VERSION "HINBNNNYNNNNNNNNNNNNNNNNNNNNNNNNNNNYYNNNNN/4>%%%/4/'%**4NNN///"

NS_ :

BS_:

BU_: Traffic Tester CGW ADU

BO_ 1025 PCM_ELEC_AC_INFO: 32 CGW
 SG_ Gen_on_disp_req_CMU m2 : 182|2@0+ (1,0) [0|0] "" Vector__XXX
 SG_ DrvSys_Pwrdwn_Req_Xev m2 : 183|1@0+ (1,0) [0|0] "" Vector__XXX
 SG_ V2H_Supply_State m2 : 169|2@0+ (1,0) [0|0] "" Vector__XXX
 SG_ TrqDwn_MsgC_Rq m2 : 170|1@0+ (1,0) [0|0] "" Vector__XXX
 SG_ SelfWake_Set_Req m2 : 172|2@0+ (1,0) [0|0] "" Vector__XXX
 SG_ PSU_Supply_State m2 : 160|4@0+ (1,0) [0|0] "" Vector__XXX
 SG_ HvBatSysWarn_D_Rq m2 : 162|2@0+ (1,0) [0|0] "" Vector__XXX
 SG_ GenSysState_D_Rq m2 : 165|3@0+ (1,0) [0|0] "" Vector__XXX
 SG_ TrqDwn_MsgB_Rq m2 : 166|1@0+ (1,0) [0|0] "" Vector__XXX
 SG_ TrqDwn_MsgA_Rq m2 : 167|1@0+ (1,0) [0|0] "" Vector__XXX
 SG_ TrqDwn_BzB_Rq m2 : 152|1@0+ (1,0) [0|0] "" Vector__XXX
 SG_ TrqDwn_BzA_Rq m2 : 153|1@0+ (1,0) [0|0] "" Vector__XXX
 SG_ DispEVMode_D_Rq m2 : 155|2@0+ (1,0) [0|0] "" Vector__XXX
 SG_ BattTemp_Warn_D_Rq m2 : 157|2@0+ (1,0) [0|0] "" Vector__XXX
 SG_ BattTemp m2 : 151|10@0+ (0.5,-30) [-30|60] "degC" Vector__XXX
 SG_ RegenRejMsg_D_Req m2 : 136|1@0+ (1,0) [0|0] "" Vector__XXX
 SG_ RegenRejLamp_D_Req m2 : 137|1@0+ (1,0) [0|0] "" Vector__XXX
 SG_ Mot_D_ReqPwrHis m2 : 138|1@0+ (1,0) [0|0] "" Vector__XXX
 SG_ Mot_D_ReqPwrGain m2 : 140|2@0+ (1,0) [0|0] "" Vector__XXX
 SG_ ElecDrvSys_Pwrdwn_Req m2 : 141|1@0+ (1,0) [0|0] "" Vector__XXX
 SG_ PwrDwn_Flash_Req m2 : 142|1@0+ (1,0) [0|0] "" Vector__XXX
 SG_ PwrDwn_D_Req m2 : 143|1@0+ (1,0) [0|0] "" Vector__XXX
 SG_ Charging_State_D_Actl m1 : 187|4@0+ (1,0) [0|0] "" Vector__XXX
 SG_ Charger_Connector_Fit_State m1 : 191|4@0+ (1,0) [0|0] "" Vector__XXX
 SG_ GenSys_Notavail_Req_Xev m1 : 176|1@0+ (1,0) [0|0] "" Vector__XXX
 SG_ EV_Warning_Ind_Req m1 : 177|1@0+ (1,0) [0|0] "" Vector__XXX
 SG_ ElecDrvSys_Caut_Req m1 : 178|1@0+ (1,0) [0|0] "" Vector__XXX
 SG_ BatteryHeater_ON m1 : 179|1@0+ (1,0) [0|0] "" Vector__XXX
 SG_ Batt_Lack_Warn_D_Rq m1 : 182|3@0+ (1,0) [0|0] "" Vector__XXX
 SG_ BatteryChargingPreTelltale m1 : 183|1@0+ (1,0) [0|0] "" Vector__XXX
 SG_ Charger_Connector_Fitting m1 : 168|1@0+ (1,0) [0|0] "" Vector__XXX
 SG_ Air_BleedingMode_Req m1 : 169|1@0+ (1,0) [0|0] "" Vector__XXX
 SG_ BatteryHeater_info3 m1 : 171|2@0+ (1,0) [0|0] "" Vector__XXX
 SG_ BatteryHeater_info2 m1 : 173|2@0+ (1,0) [0|0] "" Vector__XXX
 SG_ BatteryHeater_info1 m1 : 175|2@0+ (1,0) [0|0] "" Vector__XXX
 SG_ SOC_Charge_Guide_Req_Xev m1 : 160|1@0+ (1,0) [0|0] "" Vector__XXX
 SG_ SOC_LowerLimit_HysL m1 : 152|8@0+ (0.5,0) [0|100] "%" Vector__XXX
 SG_ SOC_LowerLimit_HysH m1 : 144|8@0+ (0.5,0) [0|100] "%" Vector__XXX
 SG_ PbBatteryChargingState m1 : 147|3@0+ (1,0) [0|0] "" Vector__XXX
 SG_ HiVolt_Battery_FullCapacity m1 : 143|12@0+ (0.1,0) [0|100] "kWh" Vector__XXX
 SG_ Useract_Reject_Msg m0 : 186|3@0+ (1,0) [0|0] "" Vector__XXX
 SG_ Leakage_Advan_Com m0 : 187|1@0+ (1,0) [0|0] "" Vector__XXX
 SG_ ChargSys_Error_Req m0 : 188|1@0+ (1,0) [0|0] "" Vector__XXX
 SG_ ChargSys_Warn_Req m0 : 189|1@0+ (1,0) [0|0] "" Vector__XXX
 SG_ ElecDrvSys_mainte_Req m0 : 190|1@0+ (1,0) [0|0] "" Vector__XXX
 SG_ FuelLid_Close_B_Req m0 : 191|1@0+ (1,0) [0|0] "" Vector__XXX
 SG_ SOC_xev_EMPTY m0 : 183|8@0+ (0.5,0) [0|100] "%" Vector__XXX
 SG_ SOC_xev_FULL m0 : 175|8@0+ (0.5,0) [0|100] "%" Vector__XXX
 SG_ Power_generation_State m0 : 161|2@0+ (1,0) [0|0] "" Vector__XXX
 SG_ Battery_Deterioration m0 : 165|4@0+ (1,0) [0|0] "" Vector__XXX
 SG_ Batt_coling_disp_req_TCU m0 : 166|1@0+ (1,0) [0|0] "" Vector__XXX
 SG_ Batt_coling_disp_req_CMU m0 : 167|1@0+ (1,0) [0|0] "" Vector__XXX
 SG_ Max_Charge_Minute_AC m0 : 159|8@0+ (10,0) [0|2530] "min" Vector__XXX
 SG_ Max_Charge_Minute_QBC m0 : 151|8@0+ (5,0) [0|500] "min" Vector__XXX
 SG_ Refueling_Propriety_State m0 : 137|2@0+ (1,0) [0|0] "" Vector__XXX
 SG_ ElecDrvSys_Warn_Req m0 : 138|1@0+ (1,0) [0|0] "" Vector__XXX
 SG_ PowerDown m0 : 139|1@0+ (1,0) [0|0] "" Vector__XXX
 SG_ REX_Run m0 : 140|1@0+ (1,0) [0|0] "" Vector__XXX
 SG_ SuplyStatus m0 : 141|1@0+ (1,0) [0|0] "" Vector__XXX
 SG_ DCChargeStatus m0 : 142|1@0+ (1,0) [0|0] "" Vector__XXX
 SG_ ACChargeStatus m0 : 143|1@0+ (1,0) [0|0] "" Vector__XXX
 SG_ EVData_2_mode M : 135|8@0+ (1,0) [0|0] "" Vector__XXX
 SG_ AirAmb_Te_Actl : 113|10@0+ (0.25,-128) [-128|127.75] "degC"  ADU
 SG_ OilDtrWrn_Stat_B_Actl : 114|1@0+ (1,0) [0|0] "" Vector__XXX
 SG_ SedimentWarning : 115|1@0+ (1,0) [0|0] "" Vector__XXX
 SG_ AirAmbTe_D_Qf : 117|2@0+ (1,0) [0|0] ""  ADU
 SG_ EngClntTe_D_Qf : 119|2@0+ (1,0) [0|0] "" Vector__XXX
 SG_ DPFTelltale : 104|1@0+ (1,0) [0|0] "" Vector__XXX
 SG_ OilDtrWrn_Init_B_Eco : 105|1@0+ (1,0) [0|0] "" Vector__XXX
 SG_ Oil_deteriorate_warning : 106|1@0+ (1,0) [0|0] "" Vector__XXX
 SG_ FuelFilterWarning : 107|1@0+ (1,0) [0|0] "" Vector__XXX
 SG_ OilPressureWarning : 108|1@0+ (1,0) [0|0] "" Vector__XXX
 SG_ OverrevBz_D_Rq : 110|2@0+ (1,0) [0|0] "" Vector__XXX
 SG_ FUEL_CAP_OFF_TELTAL : 111|1@0+ (1,0) [0|0] "" Vector__XXX
 SG_ EngineIdleStatus : 96|1@0+ (1,0) [0|0] "" Vector__XXX
 SG_ BatteryChargingTelltale : 97|1@0+ (1,0) [0|0] "" Vector__XXX
 SG_ DieselGlowplugTelltale : 98|1@0+ (1,0) [0|0] "" Vector__XXX
 SG_ Oil_Deteriorate_Warn_Rst : 99|1@0+ (1,0) [0|0] "" Vector__XXX
 SG_ GPF_SootDepoWarning : 100|1@0+ (1,0) [0|0] "" Vector__XXX
 SG_ PCM_BPS_DrESUPwr_Fail : 101|1@0+ (1,0) [0|0] "" Vector__XXX
 SG_ DriverStatus_disp : 102|1@0+ (1,0) [0|0] "" Vector__XXX
 SG_ LowTempTorqLimit : 103|1@0+ (1,0) [0|0] "" Vector__XXX
 SG_ HighTempTorqLimit : 88|1@0+ (1,0) [0|0] "" Vector__XXX
 SG_ MildHevBatteryWarningTelltale : 89|1@0+ (1,0) [0|0] "" Vector__XXX
 SG_ MildHevWarningTelltale : 90|1@0+ (1,0) [0|0] "" Vector__XXX
 SG_ BatteryPerformanceTelltale : 91|1@0+ (1,0) [0|0] "" Vector__XXX
 SG_ OilLevelWarning : 93|2@0+ (1,0) [0|0] "" Vector__XXX
 SG_ ECMMILRequest : 95|2@0+ (1,0) [0|0] "" Vector__XXX
 SG_ AirAmb_P_Actl : 85|6@0+ (10,500) [500|1110] "millibar" Vector__XXX
 SG_ PCM_INDLvl_D_Rq : 87|2@0+ (1,0) [0|0] "" Vector__XXX
 SG_ FuelPulse : 79|8@0+ (20,0) [0|5100] "Microliters" Vector__XXX
 SG_ EngClnt_Te_Actl : 71|8@0+ (1,-40) [-40|214] "degC" Vector__XXX
 SG_ HPECU_DTC_Clear_Rq : 56|1@0+ (1,0) [0|0] "" Vector__XXX
 SG_ AC_Mode_Sig : 59|3@0+ (1,0) [0|0] "" Vector__XXX
 SG_ BAT_Refcooling_Lvl : 63|4@0+ (1,0) [0|0] "" Vector__XXX
 SG_ FAN_AC_State_Actl : 55|8@0+ (0.5,0) [0|100] "%" Vector__XXX
 SG_ PTCHeater_Win_Actual : 47|8@0+ (50,0) [0|12750] "W" Vector__XXX
 SG_ Permit_Power_AC : 39|8@0+ (50,0) [0|10000] "W" Vector__XXX
 SG_ Compressor_Power_Actual : 31|8@0+ (50,0) [0|10000] "W" Vector__XXX
 SG_ Compressor_Rev_Actual : 15|16@0+ (1,0) [0|10000] "rpm" Vector__XXX
 SG_ PTCHeater_Power_Actual : 7|8@0+ (50,0) [0|10000] "W" Vector__XXX

BO_ 1010 HP_ECU_Infomation: 32 CGW
 SG_ CXP_UERR : 186|1@0+ (1,0) [0|0] ""  ADU
 SG_ GFPEXT : 188|2@0+ (1,0) [0|0] ""  ADU
 SG_ P2Z_INV : 189|1@0+ (1,0) [0|0] ""  ADU
 SG_ GRPHLDR : 190|1@0+ (1,0) [0|0] ""  ADU
 SG_ GRPHLDL : 191|1@0+ (1,0) [0|0] ""  ADU
 SG_ TMPMFIX : 176|1@0+ (1,0) [0|0] ""  ADU
 SG_ TMPABNR : 177|1@0+ (1,0) [0|0] ""  ADU
 SG_ TMPABNL : 178|1@0+ (1,0) [0|0] ""  ADU
 SG_ GRPFAIL1 : 179|1@0+ (1,0) [0|0] ""  ADU
 SG_ GRPFAIL0 : 180|1@0+ (1,0) [0|0] ""  ADU
 SG_ F_HTRSW : 181|1@0+ (1,0) [0|0] ""  ADU
 SG_ F_HTROP : 182|1@0+ (1,0) [0|0] ""  ADU
 SG_ F_HTRGS : 183|1@0+ (1,0) [0|0] ""  ADU
 SG_ Wtrcond_WtrTrg : 175|8@0+ (1,0) [0|255] "deg.C" Vector__XXX
 SG_ HtrcoreWtrTrg : 167|8@0+ (1,0) [0|255] "deg.C" Vector__XXX
 SG_ HPECU_MasterWarning_Rq : 154|3@0+ (1,0) [0|0] "" Vector__XXX
 SG_ HPECU_calc_CVN : 155|1@0+ (1,0) [0|0] "" Vector__XXX
 SG_ HPECU_DTC_Clear_Comp : 156|1@0+ (1,0) [0|0] "" Vector__XXX
 SG_ HP_Remote_PreAC_Res : 157|1@0+ (1,0) [0|0] "" Vector__XXX
 SG_ HP_PreAC_RearDef_Rq : 158|1@0+ (1,0) [0|0] "" Vector__XXX
 SG_ HP_State_PreAC_Operation : 146|4@0+ (1,0) [0|0] "" Vector__XXX
 SG_ HP_Flg_HeatExchgFrost : 149|3@0+ (1,0) [0|0] "" Vector__XXX
 SG_ HP_Fail_OperationCycleFail : 151|2@0+ (1,0) [0|0] "" Vector__XXX
 SG_ HP_State_OperationCycle : 139|4@0+ (1,0) [0|0] "" Vector__XXX
 SG_ HP_Fail_TempRfrgCondOut : 143|4@0+ (1,0) [0|0] "" Vector__XXX
 SG_ HP_Fail_SolVlv_Warm : 131|4@0+ (1,0) [0|0] "" Vector__XXX
 SG_ HP_Fail_SolVlv_HiPre_Fail : 135|4@0+ (1,0) [0|0] "" Vector__XXX
 SG_ DBKL_MET : 113|2@0+ (1,0) [0|0] "" Vector__XXX
 SG_ atcTAO_Ps : 108|8@0+ (1,-127) [-127|128] "" Vector__XXX
 SG_ atcTAO_Dr : 100|8@0+ (1,-127) [-127|128] "" Vector__XXX
 SG_ atcBlwAirflow : 91|7@0+ (5,0) [0|635] "m3/h" Vector__XXX
 SG_ atcAMratioPs : 83|8@0+ (0.5,0) [0|100] "%" Vector__XXX
 SG_ atcAMratioDr : 75|8@0+ (0.5,0) [0|100] "%" Vector__XXX
 SG_ atcAImodeRecRatio : 67|8@0+ (0.5,0) [0|100] "%" Vector__XXX
 SG_ atcADmode : 71|4@0+ (1,0) [0|0] "" Vector__XXX
 SG_ BAT_Cool_DistRate : 63|6@0+ (2,0) [0|100] "%" Vector__XXX
 SG_ BAT_TXV_Trg : 43|12@0+ (0.05,0) [0|100] "%" Vector__XXX
 SG_ FAN_AC_Out_Trg : 35|8@0+ (0.5,0) [0|127.5] "%" Vector__XXX
 SG_ PTCheater_Wout_Trg : 17|14@0+ (1,0) [0|10000] "W" Vector__XXX
 SG_ THO_Control_Req : 8|3@0+ (1,0) [0|0] "" Vector__XXX
 SG_ Compressor_Rev_Rq : 9|1@0+ (1,0) [0|0] "" Vector__XXX
 SG_ Compressor_Rev_Trg : 7|14@0+ (1,0) [0|10000] "rpm" Vector__XXX

BO_ 994 Navi_Tnnl_Brdg_Info: 32 CGW
 SG_ Navi_grad_MM : 135|8@0+ (1,0) [0|255] ""  ADU
 SG_ Navi_Oneway_dist0 : 88|8@0+ (1,0) [0|255] ""  ADU
 SG_ Navi_Oneway_dist_lsb0 : 89|1@0+ (1,0) [0|0] ""  ADU
 SG_ Navi_Oneway_flg0 : 92|3@0+ (1,0) [0|0] ""  ADU
 SG_ Navi_Oneway_MM : 95|3@0+ (1,0) [0|0] ""  ADU
 SG_ Navi_BuildupArea_dist2 : 87|8@0+ (1,0) [0|255] ""  ADU
 SG_ Navi_BuildupArea_dist_lsb2 : 72|1@0+ (1,0) [0|0] ""  ADU
 SG_ Navi_BuildupArea_flg2 : 74|2@0+ (1,0) [0|0] ""  ADU
 SG_ Navi_BuildupArea_dist1 : 66|8@0+ (1,0) [0|255] ""  ADU
 SG_ Navi_BuildupArea_dist_lsb1 : 67|1@0+ (1,0) [0|0] ""  ADU
 SG_ Navi_BuildupArea_flg1 : 69|2@0+ (1,0) [0|0] ""  ADU
 SG_ Navi_BuildupArea_MM : 71|2@0+ (1,0) [0|0] ""  ADU
 SG_ Navi_brdg_sctn_dist0 : 27|8@0+ (1,0) [0|255] ""  ADU
 SG_ Navi_brdg_dist_type0 : 28|1@0+ (1,0) [0|0] ""  ADU
 SG_ Navi_brdg_dist0 : 20|8@0+ (1,0) [0|255] ""  ADU
 SG_ Navi_brdg_dist_lsb0 : 21|1@0+ (1,0) [0|0] ""  ADU
 SG_ Navi_tnnl_sctn_dist_type0 : 13|8@0+ (1,0) [0|255] ""  ADU
 SG_ Navi_tnnl_dist_type0 : 14|1@0+ (1,0) [0|0] ""  ADU
 SG_ Navi_tnnl_dist0 : 6|8@0+ (1,0) [0|255] ""  ADU
 SG_ Navi_tnnl_dist_lsb0 : 7|1@0+ (1,0) [0|0] ""  ADU

BO_ 988 EgoPath_Info2: 32 CGW
 SG_ ADAS_Map_PositionConf_cost56 : 201|7@0+ (1,0) [0|100] "%"  ADU
 SG_ ADAS_Map_PositionConf_cost45 : 192|7@0+ (1,0) [0|100] "%"  ADU
 SG_ ADAS_Map_PositionConf_cost34 : 199|7@0+ (1,0) [0|100] "%"  ADU
 SG_ ADAS_Map_PositionConf_cost23 : 190|7@0+ (1,0) [0|100] "%"  ADU
 SG_ ADAS_Map_PositionConf_cost12 : 181|7@0+ (1,0) [0|100] "%"  ADU
 SG_ ADAS_Map_PositionConfidence4 : 168|3@0+ (1,0) [0|0] ""  ADU
 SG_ ADAS_Map_PositionConfidence3 : 170|2@0+ (1,0) [0|0] ""  ADU
 SG_ ADAS_Map_PositionConfidence2 : 172|2@0+ (1,0) [0|0] ""  ADU
 SG_ ADAS_Map_PositionConfidence1 : 175|3@0+ (1,0) [0|0] ""  ADU
 SG_ MAP_Version : 158|15@0+ (1,0) [0|0] ""  ADU
 SG_ CMU_Package_Version : 143|17@0+ (1,0) [0|131071] ""  ADU
 SG_ NavRegionCode : 133|6@0+ (1,0) [0|63] ""  ADU
 SG_ NavRouteGuidance_flg : 135|2@0+ (1,0) [0|0] ""  ADU
 SG_ Multi_Carriageway_Dist : 105|10@0+ (1,0) [0|1022] "m"  ADU
 SG_ Multi_Carriageway_Ego : 107|2@0+ (1,0) [0|0] ""  ADU
 SG_ Lane_Num_Next : 111|4@0+ (1,0) [0|0] ""  ADU
 SG_ Lane_Num_Dist : 91|12@0+ (1,0) [0|4094] "m"  ADU
 SG_ Lane_Num_Ego : 95|4@0+ (1,0) [0|0] ""  ADU
 SG_ ADAS_Map_Link_Type_Dist : 73|10@0+ (1,0) [0|1022] "m"  ADU
 SG_ ADAS_Map_SUB_Distance_Ego : 67|10@0+ (1,0) [0|1022] "m"  ADU
 SG_ ADAS_Map_SUB_Attribute_Ego : 71|4@0+ (1,0) [0|0] ""  ADU
 SG_ Route_Destination_Dist : 33|12@0+ (1,0) [0|4094] "m"  ADU
 SG_ Route_Destination_Ego : 35|2@0+ (1,0) [0|0] ""  ADU
 SG_ Stop_Info_Dist : 29|10@0+ (1,0) [0|1022] "m"  ADU
 SG_ Stop_Info_Ego : 31|2@0+ (1,0) [0|0] ""  ADU
 SG_ One_Way_Code_Dist : 9|10@0+ (1,0) [0|1022] "m"  ADU
 SG_ One_Way_Code_Ego : 11|2@0+ (1,0) [0|0] ""  ADU
 SG_ Supplymental_Speed_Sign_Ego : 15|4@0+ (1,0) [0|0] ""  ADU
 SG_ Supplymental_Speed_Limit_Ego : 7|8@0+ (1,0) [0|254] "Unitless"  ADU

BO_ 985 ADAS_MAP_Information1: 32 CGW
 SG_ NavCountry_Roadside : 175|2@0+ (1,0) [0|0] ""  ADU
 SG_ Speed_Limit_Unit : 161|2@0+ (1,0) [0|0] ""  ADU
 SG_ Speed_Limit : 155|10@0+ (1,0) [1|999] ""  ADU
 SG_ NavZoneArea_flag_300m : 123|1@0+ (1,0) [0|0] ""  ADU
 SG_ NavZoneArea_flag_200m : 124|1@0+ (1,0) [0|0] ""  ADU
 SG_ NavZoneArea_flag_100m : 125|1@0+ (1,0) [0|0] ""  ADU
 SG_ NavZoneArea_flag : 126|1@0+ (1,0) [0|0] ""  ADU
 SG_ Implicit_Speed_Sign_Ego : 113|3@0+ (1,0) [0|0] ""  ADU
 SG_ Speed_Limit_Sign_Ego : 115|2@0+ (1,0) [0|0] ""  ADU
 SG_ Speed_Limit_Accuracy_Ego : 117|2@0+ (1,0) [0|0] ""  ADU
 SG_ Speed_Limit_Next : 109|8@0+ (1,0) [0|255] "Unitless"  ADU
 SG_ Speed_Limit_Dist : 89|12@0+ (1,0) [0|4094] "m"  ADU
 SG_ Speed_Limit_Ego : 81|8@0+ (1,0) [0|255] "Unitless"  ADU
 SG_ NavFunctionalRoadClass_Next : 86|5@0+ (1,0) [0|0] ""  ADU
 SG_ NavFunctionalRoadClass_Dist : 66|12@0+ (1,0) [0|4094] "m"  ADU
 SG_ NavFunctionalRoadClass_Ego : 71|5@0+ (1,0) [0|0] ""  ADU
 SG_ ADAS_MAP_DR_Confidence : 49|2@0+ (1,0) [0|0] ""  ADU
 SG_ ADAS_MAP_MAP_Accuracy : 51|2@0+ (1,0) [0|0] ""  ADU
 SG_ ADAS_MAP_Curvature300_index : 53|2@0+ (1,0) [0|3] ""  ADU
 SG_ ADAS_MAP_Curvature300_2digit : 44|7@0+ (1,-64) [-64|62] ""  ADU
 SG_ ADAS_MAP_Curvature200_index : 46|2@0+ (1,0) [0|3] ""  ADU
 SG_ ADAS_MAP_Curvature200_2digit : 37|7@0+ (1,-64) [-64|62] ""  ADU
 SG_ ADAS_MAP_Curvature100_index : 39|2@0+ (1,0) [0|3] ""  ADU
 SG_ ADAS_MAP_Curvature100_2digit : 30|7@0+ (1,-64) [-64|62] ""  ADU
 SG_ ADAS_MAP_Curvature0_index : 16|2@0+ (1,0) [0|3] ""  ADU
 SG_ ADAS_MAP_Curvature0_2digit : 23|7@0+ (1,-64) [-64|62] ""  ADU
 SG_ ADAS_Map_SUB_Attribute : 10|3@0+ (1,0) [0|0] ""  ADU
 SG_ ADAS_Map_SUB_Distance : 4|10@0+ (1,0) [0|1022] "m"  ADU
 SG_ ADAS_Map_PositionConfidence : 7|3@0+ (1,0) [0|0] ""  ADU

BO_ 977 HMI_Status_Notification: 8 CGW
 SG_ HMI_State_Notice_ISPU : 7|2@0+ (1,0) [0|0] ""  ADU

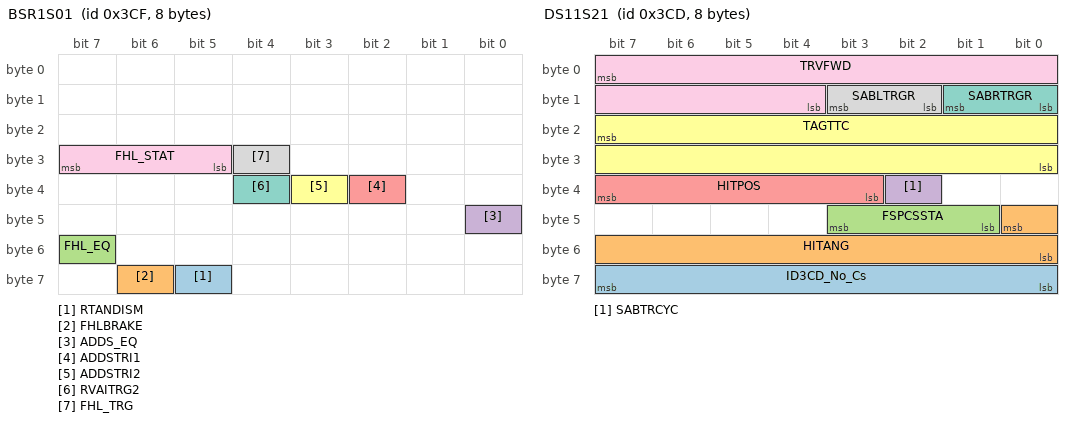
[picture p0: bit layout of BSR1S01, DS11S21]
BO_ 975 BSR1S01: 8 ADU
 SG_ RTANDISM : 61|1@0+ (1,0) [0|1] ""  CGW
 SG_ FHLBRAKE : 62|1@0+ (1,0) [0|1] ""  CGW
 SG_ FHL_EQ : 55|1@0+ (1,0) [0|1] ""  CGW
 SG_ ADDS_EQ : 40|1@0+ (1,0) [0|1] ""  CGW
 SG_ ADDSTRI1 : 34|1@0+ (1,0) [0|1] ""  CGW
 SG_ ADDSTRI2 : 35|1@0+ (1,0) [0|1] ""  CGW
 SG_ RVAITRG2 : 36|1@0+ (1,0) [0|1] ""  CGW
 SG_ FHL_TRG : 28|1@0+ (1,0) [0|1] ""  CGW
 SG_ FHL_STAT : 31|3@0+ (1,0) [0|7] ""  CGW

BO_ 974 BCC1S06: 8 ADU
 SG_ CAAINDIR : 34|2@0+ (1,0) [0|3] ""  CGW
 SG_ CAAINDIM : 38|4@0+ (1,0) [0|15] ""  CGW

BO_ 973 DS11S21: 8 ADU
 SG_ ID3CD_No_Cs : 63|8@0+ (1,0) [0|255] ""  CGW
 SG_ HITANG : 40|9@0- (0.01,0) [-2.56|2.55] "rad"  CGW
 SG_ FSPCSSTA : 43|3@0+ (1,0) [0|7] ""  CGW
 SG_ SABTRCYC : 34|1@0+ (1,0) [0|1] ""  CGW
 SG_ HITPOS : 39|5@0+ (1,0) [0|31] ""  CGW
 SG_ TAGTTC : 23|16@0+ (1,0) [0|65535] "ms"  CGW
 SG_ SABRTRGR : 9|2@0+ (1,0) [0|3] ""  CGW
 SG_ SABLTRGR : 11|2@0+ (1,0) [0|3] ""  CGW
 SG_ TRVFWD : 7|12@0+ (0.2,0) [0|819] "km/h"  CGW

BO_ 972 CSR1S08: 8 ADU
 SG_ CSR_BUZ : 43|4@0+ (1,0) [0|15] ""  CGW
 SG_ CSR_VOL : 46|3@0+ (1,0) [0|7] ""  CGW
 SG_ CAM_INF1 : 32|1@0+ (1,0) [0|1] ""  CGW
 SG_ CSRAVABL : 34|1@0+ (1,0) [0|1] ""  CGW
 SG_ ICSAVABL : 35|1@0+ (1,0) [0|1] ""  CGW
 SG_ RCDAVABL : 36|1@0+ (1,0) [0|1] ""  CGW
 SG_ PKSS_VE : 37|1@0+ (1,0) [0|1] ""  CGW
 SG_ PKSSINFO : 29|2@0+ (1,0) [0|3] ""  CGW
 SG_ CSR_INF2 : 30|1@0+ (1,0) [0|1] ""  CGW
 SG_ CSR_INF1 : 31|1@0+ (1,0) [0|1] ""  CGW
 SG_ RLS_DIRT : 17|2@0+ (1,0) [0|3] ""  CGW
 SG_ RRS_DIRT : 19|2@0+ (1,0) [0|3] ""  CGW
 SG_ FLS_DIRT : 21|2@0+ (1,0) [0|3] ""  CGW
 SG_ FRS_DIRT : 23|2@0+ (1,0) [0|3] ""  CGW
 SG_ RLC_DIRT : 9|2@0+ (1,0) [0|3] ""  CGW
 SG_ RRC_DIRT : 11|2@0+ (1,0) [0|3] ""  CGW
 SG_ RL_DIRT : 13|2@0+ (1,0) [0|3] ""  CGW
 SG_ RR_DIRT : 15|2@0+ (1,0) [0|3] ""  CGW
 SG_ FLC_DIRT : 1|2@0+ (1,0) [0|3] ""  CGW
 SG_ FRC_DIRT : 3|2@0+ (1,0) [0|3] ""  CGW
 SG_ FL_DIRT : 5|2@0+ (1,0) [0|3] ""  CGW
 SG_ FR_DIRT : 7|2@0+ (1,0) [0|3] ""  CGW

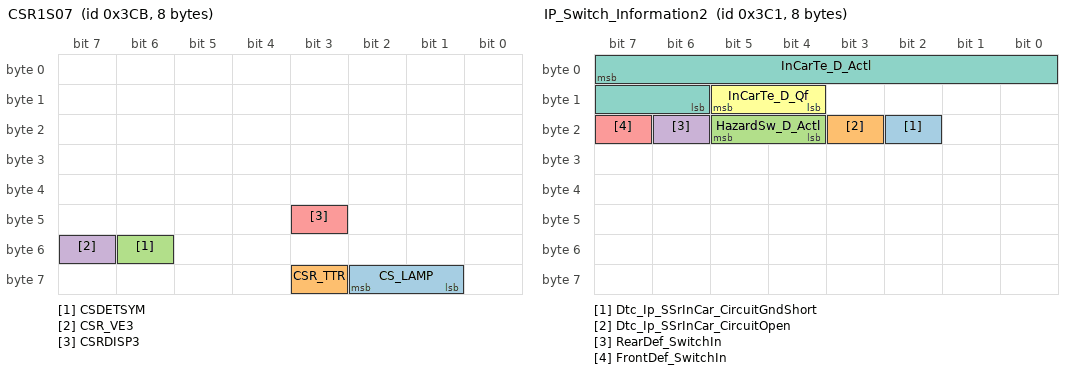
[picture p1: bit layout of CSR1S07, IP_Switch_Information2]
BO_ 971 CSR1S07: 8 ADU
 SG_ CS_LAMP : 58|2@0+ (1,0) [0|3] ""  CGW
 SG_ CSR_TTR : 59|1@0+ (1,0) [0|1] ""  CGW
 SG_ CSDETSYM : 54|1@0+ (1,0) [0|1] ""  CGW
 SG_ CSR_VE3 : 55|1@0+ (1,0) [0|1] ""  CGW
 SG_ CSRDISP3 : 43|1@0+ (1,0) [0|1] ""  CGW

BO_ 961 IP_Switch_Information2: 8 CGW
 SG_ Dtc_Ip_SSrInCar_CircuitGndShort : 18|1@0+ (1,0) [0|0] "" Vector__XXX
 SG_ Dtc_Ip_SSrInCar_CircuitOpen : 19|1@0+ (1,0) [0|0] "" Vector__XXX
 SG_ HazardSw_D_Actl : 21|2@0+ (1,0) [0|0] ""  ADU
 SG_ RearDef_SwitchIn : 22|1@0+ (1,0) [0|0] "" Vector__XXX
 SG_ FrontDef_SwitchIn : 23|1@0+ (1,0) [0|0] "" Vector__XXX
 SG_ InCarTe_D_Qf : 13|2@0+ (1,0) [0|0] ""  ADU
 SG_ InCarTe_D_Actl : 7|10@0+ (0.1,-40) [-40|62.3] "deg.C"  ADU

BO_ 960 IP_Switch_Information: 32 CGW
 SG_ ADAS_MAP_Distance_to_tunnel : 205|9@0+ (1,0) [0|510] "m"  ADU
 SG_ ADAS_MAP_Tunnel_inf : 207|2@0+ (1,0) [0|0] ""  ADU
 SG_ ADAS_Map_Link_Type_Ego : 195|4@0+ (1,0) [0|0] ""  ADU
 SG_ ADAS_Map_FormofWay_Ego : 199|4@0+ (1,0) [0|0] ""  ADU
 SG_ NavFunctionalRoadClass : 92|5@0+ (1,0) [0|0] ""  ADU
 SG_ NavBuildUpArea_flg : 93|1@0+ (1,0) [0|0] ""  ADU
 SG_ NavDataAvailable_flg : 95|2@0+ (1,0) [0|0] ""  ADU
 SG_ NavCountryCode : 73|10@0+ (1,0) [0|1023] ""  ADU
 SG_ ipRearDef_Ind : 60|1@0+ (1,0) [0|0] "" Vector__XXX
 SG_ RearDef_B_Rq : 61|1@0+ (1,0) [0|0] "" Vector__XXX
 SG_ FrontDef_B_Rq : 62|1@0+ (1,0) [0|0] "" Vector__XXX
 SG_ PanelHeaterSwitchIn_RH : 49|3@0+ (1,0) [0|0] "" Vector__XXX
 SG_ PanelHeaterSwitchIn_LH : 52|3@0+ (1,0) [0|0] "" Vector__XXX
 SG_ SteeringHeaterSwitchIn : 55|3@0+ (1,0) [0|0] "" Vector__XXX
 SG_ SeatVentilationSwitchIn_RH : 42|3@0+ (1,0) [0|0] "" Vector__XXX
 SG_ SeatHeaterSwitchIn_RH : 45|3@0+ (1,0) [0|0] "" Vector__XXX
 SG_ SeatVentilationSwitchIn_LH : 32|3@0+ (1,0) [0|0] "" Vector__XXX
 SG_ SeatHeaterSwitchIn_LH : 35|3@0+ (1,0) [0|0] "" Vector__XXX
 SG_ ipREARmode : 37|2@0+ (1,0) [0|0] "" Vector__XXX
 SG_ ipECOmode : 39|2@0+ (1,0) [0|0] "" Vector__XXX
 SG_ ipAImode : 27|4@0+ (1,0) [0|0] "" Vector__XXX
 SG_ ipADmode : 31|4@0+ (1,0) [0|0] "" Vector__XXX
 SG_ ipACmode : 19|4@0+ (1,0) [0|0] "" Vector__XXX
 SG_ ipBlwLvl : 23|4@0+ (1,0) [0|0] "" Vector__XXX
 SG_ ipTSetPs : 15|8@0+ (0.1,12) [12|37.5] "deg.C" Vector__XXX
 SG_ ipTSetDr : 7|8@0+ (0.1,12) [12|37.5] "deg.C" Vector__XXX

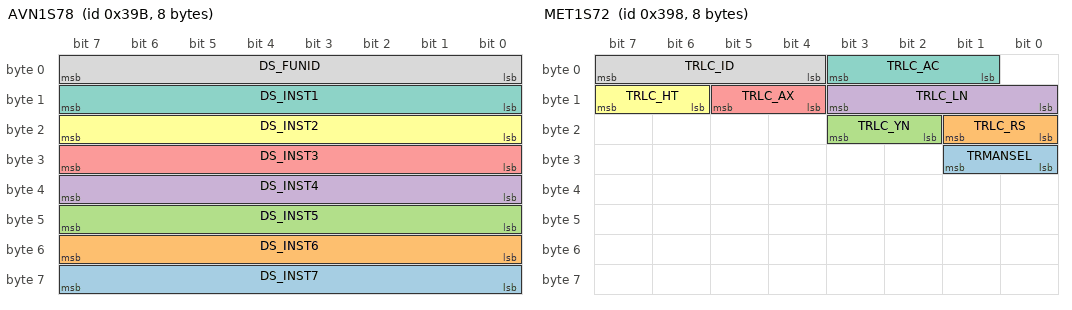
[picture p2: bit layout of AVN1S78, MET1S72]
BO_ 923 AVN1S78: 8 CGW
 SG_ DS_INST7 : 63|8@0+ (1,0) [0|255] ""  ADU
 SG_ DS_INST6 : 55|8@0+ (1,0) [0|255] ""  ADU
 SG_ DS_INST5 : 47|8@0+ (1,0) [0|255] ""  ADU
 SG_ DS_INST4 : 39|8@0+ (1,0) [0|255] ""  ADU
 SG_ DS_INST3 : 31|8@0+ (1,0) [0|255] ""  ADU
 SG_ DS_INST2 : 23|8@0+ (1,0) [0|255] ""  ADU
 SG_ DS_INST1 : 15|8@0+ (1,0) [0|255] ""  ADU
 SG_ DS_FUNID : 7|8@0+ (1,0) [0|255] ""  ADU

BO_ 920 MET1S72: 8 CGW
 SG_ TRMANSEL : 25|2@0+ (1,0) [0|3] ""  ADU
 SG_ TRLC_RS : 17|2@0+ (1,0) [0|3] ""  ADU
 SG_ TRLC_YN : 19|2@0+ (1,0) [0|3] ""  ADU
 SG_ TRLC_LN : 11|4@0+ (1,0) [0|15] ""  ADU
 SG_ TRLC_AX : 13|2@0+ (1,0) [0|3] ""  ADU
 SG_ TRLC_HT : 15|2@0+ (1,0) [0|3] ""  ADU
 SG_ TRLC_AC : 3|3@0+ (1,0) [0|7] ""  ADU
 SG_ TRLC_ID : 7|4@0+ (1,0) [0|15] ""  ADU

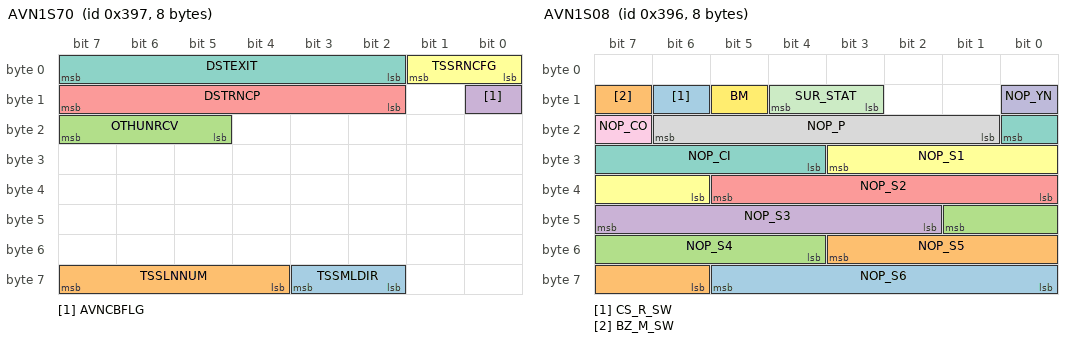
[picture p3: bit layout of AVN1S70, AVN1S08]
BO_ 919 AVN1S70: 8 CGW
 SG_ TSSMLDIR : 59|2@0+ (1,0) [0|3] ""  ADU
 SG_ TSSLNNUM : 63|4@0+ (1,0) [0|15] ""  ADU
 SG_ OTHUNRCV : 23|3@0+ (1,0) [0|7] ""  ADU
 SG_ AVNCBFLG : 8|1@0+ (1,0) [0|1] ""  ADU
 SG_ DSTRNCP : 15|6@0+ (1,0) [0|63] ""  ADU
 SG_ TSSRNCFG : 1|2@0+ (1,0) [0|3] ""  ADU
 SG_ DSTEXIT : 7|6@0+ (1,0) [0|63] ""  ADU

BO_ 918 AVN1S08: 8 CGW
 SG_ NOP_S6 : 61|6@0+ (1,0) [0|63] ""  ADU
 SG_ NOP_S5 : 51|6@0+ (1,0) [0|63] ""  ADU
 SG_ NOP_S4 : 41|6@0+ (1,0) [0|63] ""  ADU
 SG_ NOP_S3 : 47|6@0+ (1,0) [0|63] ""  ADU
 SG_ NOP_S2 : 37|6@0+ (1,0) [0|63] ""  ADU
 SG_ NOP_S1 : 27|6@0+ (1,0) [0|63] ""  ADU
 SG_ NOP_CI : 16|5@0+ (1,0) [0|31] ""  ADU
 SG_ NOP_P : 22|6@0+ (1,0) [0|63] ""  ADU
 SG_ NOP_CO : 23|1@0+ (1,0) [0|1] ""  ADU
 SG_ NOP_YN : 8|1@0+ (1,0) [0|1] ""  ADU
 SG_ SUR_STAT : 12|2@0+ (1,0) [0|3] ""  ADU
 SG_ BM : 13|1@0+ (1,0) [0|1] ""  ADU
 SG_ CS_R_SW : 14|1@0+ (1,0) [0|0] ""  ADU
 SG_ BZ_M_SW : 15|1@0+ (1,0) [0|0] ""  ADU

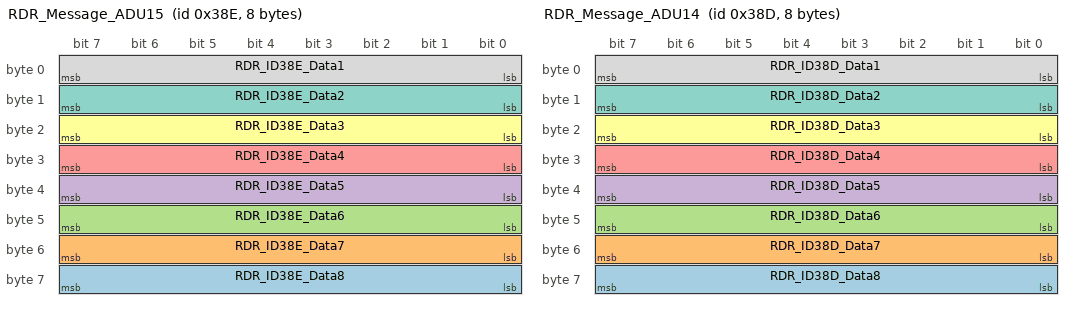
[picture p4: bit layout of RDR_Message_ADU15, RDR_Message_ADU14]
BO_ 910 RDR_Message_ADU15: 8 ADU
 SG_ RDR_ID38E_Data8 : 63|8@0+ (1,0) [0|255] ""  CGW
 SG_ RDR_ID38E_Data7 : 55|8@0+ (1,0) [0|255] ""  CGW
 SG_ RDR_ID38E_Data6 : 47|8@0+ (1,0) [0|255] ""  CGW
 SG_ RDR_ID38E_Data5 : 39|8@0+ (1,0) [0|255] ""  CGW
 SG_ RDR_ID38E_Data4 : 31|8@0+ (1,0) [0|255] ""  CGW
 SG_ RDR_ID38E_Data3 : 23|8@0+ (1,0) [0|255] ""  CGW
 SG_ RDR_ID38E_Data2 : 15|8@0+ (1,0) [0|255] ""  CGW
 SG_ RDR_ID38E_Data1 : 7|8@0+ (1,0) [0|255] ""  CGW

BO_ 909 RDR_Message_ADU14: 8 ADU
 SG_ RDR_ID38D_Data8 : 63|8@0+ (1,0) [0|255] ""  CGW
 SG_ RDR_ID38D_Data7 : 55|8@0+ (1,0) [0|255] ""  CGW
 SG_ RDR_ID38D_Data6 : 47|8@0+ (1,0) [0|255] ""  CGW
 SG_ RDR_ID38D_Data5 : 39|8@0+ (1,0) [0|255] ""  CGW
 SG_ RDR_ID38D_Data4 : 31|8@0+ (1,0) [0|255] ""  CGW
 SG_ RDR_ID38D_Data3 : 23|8@0+ (1,0) [0|255] ""  CGW
 SG_ RDR_ID38D_Data2 : 15|8@0+ (1,0) [0|255] ""  CGW
 SG_ RDR_ID38D_Data1 : 7|8@0+ (1,0) [0|255] ""  CGW

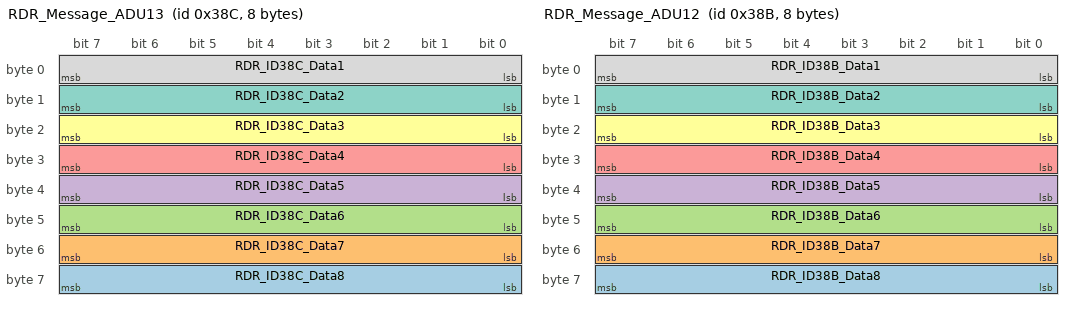
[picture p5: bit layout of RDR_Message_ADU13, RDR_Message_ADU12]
BO_ 908 RDR_Message_ADU13: 8 ADU
 SG_ RDR_ID38C_Data8 : 63|8@0+ (1,0) [0|255] ""  CGW
 SG_ RDR_ID38C_Data7 : 55|8@0+ (1,0) [0|255] ""  CGW
 SG_ RDR_ID38C_Data6 : 47|8@0+ (1,0) [0|255] ""  CGW
 SG_ RDR_ID38C_Data5 : 39|8@0+ (1,0) [0|255] ""  CGW
 SG_ RDR_ID38C_Data4 : 31|8@0+ (1,0) [0|255] ""  CGW
 SG_ RDR_ID38C_Data3 : 23|8@0+ (1,0) [0|255] ""  CGW
 SG_ RDR_ID38C_Data2 : 15|8@0+ (1,0) [0|255] ""  CGW
 SG_ RDR_ID38C_Data1 : 7|8@0+ (1,0) [0|255] ""  CGW

BO_ 907 RDR_Message_ADU12: 8 ADU
 SG_ RDR_ID38B_Data8 : 63|8@0+ (1,0) [0|255] ""  CGW
 SG_ RDR_ID38B_Data7 : 55|8@0+ (1,0) [0|255] ""  CGW
 SG_ RDR_ID38B_Data6 : 47|8@0+ (1,0) [0|255] ""  CGW
 SG_ RDR_ID38B_Data5 : 39|8@0+ (1,0) [0|255] ""  CGW
 SG_ RDR_ID38B_Data4 : 31|8@0+ (1,0) [0|255] ""  CGW
 SG_ RDR_ID38B_Data3 : 23|8@0+ (1,0) [0|255] ""  CGW
 SG_ RDR_ID38B_Data2 : 15|8@0+ (1,0) [0|255] ""  CGW
 SG_ RDR_ID38B_Data1 : 7|8@0+ (1,0) [0|255] ""  CGW

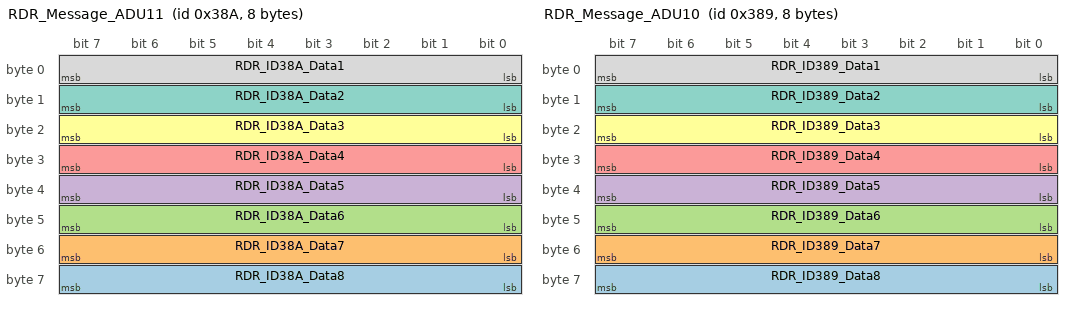
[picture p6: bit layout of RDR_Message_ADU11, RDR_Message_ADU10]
BO_ 906 RDR_Message_ADU11: 8 ADU
 SG_ RDR_ID38A_Data8 : 63|8@0+ (1,0) [0|255] ""  CGW
 SG_ RDR_ID38A_Data7 : 55|8@0+ (1,0) [0|255] ""  CGW
 SG_ RDR_ID38A_Data6 : 47|8@0+ (1,0) [0|255] ""  CGW
 SG_ RDR_ID38A_Data5 : 39|8@0+ (1,0) [0|255] ""  CGW
 SG_ RDR_ID38A_Data4 : 31|8@0+ (1,0) [0|255] ""  CGW
 SG_ RDR_ID38A_Data3 : 23|8@0+ (1,0) [0|255] ""  CGW
 SG_ RDR_ID38A_Data2 : 15|8@0+ (1,0) [0|255] ""  CGW
 SG_ RDR_ID38A_Data1 : 7|8@0+ (1,0) [0|255] ""  CGW

BO_ 905 RDR_Message_ADU10: 8 ADU
 SG_ RDR_ID389_Data8 : 63|8@0+ (1,0) [0|255] ""  CGW
 SG_ RDR_ID389_Data7 : 55|8@0+ (1,0) [0|255] ""  CGW
 SG_ RDR_ID389_Data6 : 47|8@0+ (1,0) [0|255] ""  CGW
 SG_ RDR_ID389_Data5 : 39|8@0+ (1,0) [0|255] ""  CGW
 SG_ RDR_ID389_Data4 : 31|8@0+ (1,0) [0|255] ""  CGW
 SG_ RDR_ID389_Data3 : 23|8@0+ (1,0) [0|255] ""  CGW
 SG_ RDR_ID389_Data2 : 15|8@0+ (1,0) [0|255] ""  CGW
 SG_ RDR_ID389_Data1 : 7|8@0+ (1,0) [0|255] ""  CGW

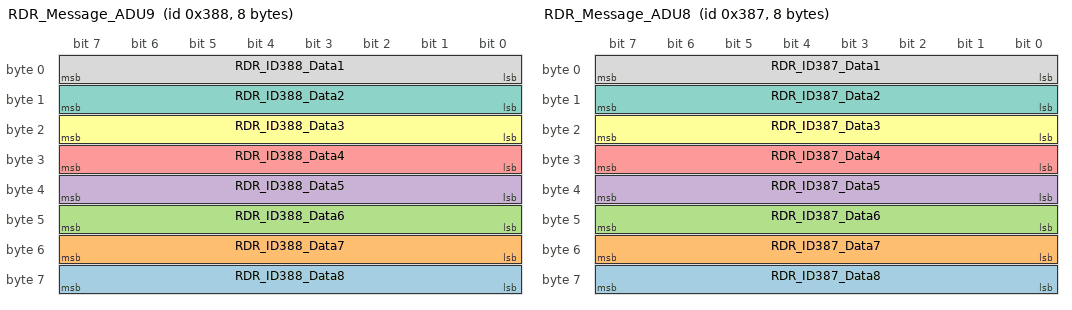
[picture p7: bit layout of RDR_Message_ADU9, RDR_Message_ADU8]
BO_ 904 RDR_Message_ADU9: 8 ADU
 SG_ RDR_ID388_Data8 : 63|8@0+ (1,0) [0|255] ""  CGW
 SG_ RDR_ID388_Data7 : 55|8@0+ (1,0) [0|255] ""  CGW
 SG_ RDR_ID388_Data6 : 47|8@0+ (1,0) [0|255] ""  CGW
 SG_ RDR_ID388_Data5 : 39|8@0+ (1,0) [0|255] ""  CGW
 SG_ RDR_ID388_Data4 : 31|8@0+ (1,0) [0|255] ""  CGW
 SG_ RDR_ID388_Data3 : 23|8@0+ (1,0) [0|255] ""  CGW
 SG_ RDR_ID388_Data2 : 15|8@0+ (1,0) [0|255] ""  CGW
 SG_ RDR_ID388_Data1 : 7|8@0+ (1,0) [0|255] ""  CGW

BO_ 903 RDR_Message_ADU8: 8 ADU
 SG_ RDR_ID387_Data8 : 63|8@0+ (1,0) [0|255] ""  CGW
 SG_ RDR_ID387_Data7 : 55|8@0+ (1,0) [0|255] ""  CGW
 SG_ RDR_ID387_Data6 : 47|8@0+ (1,0) [0|255] ""  CGW
 SG_ RDR_ID387_Data5 : 39|8@0+ (1,0) [0|255] ""  CGW
 SG_ RDR_ID387_Data4 : 31|8@0+ (1,0) [0|255] ""  CGW
 SG_ RDR_ID387_Data3 : 23|8@0+ (1,0) [0|255] ""  CGW
 SG_ RDR_ID387_Data2 : 15|8@0+ (1,0) [0|255] ""  CGW
 SG_ RDR_ID387_Data1 : 7|8@0+ (1,0) [0|255] ""  CGW

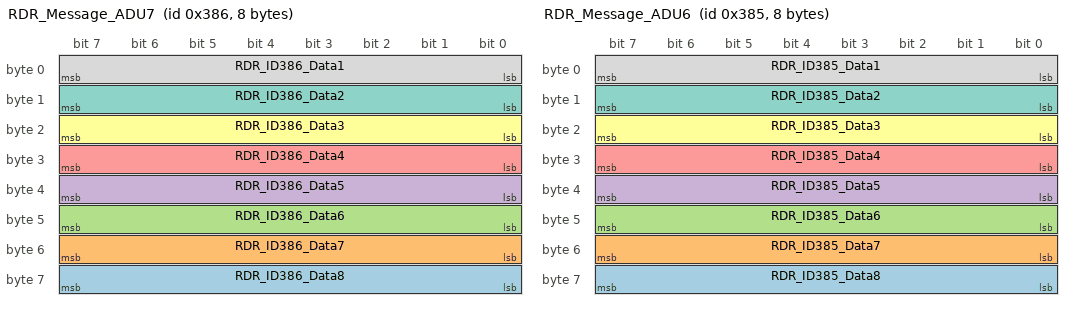
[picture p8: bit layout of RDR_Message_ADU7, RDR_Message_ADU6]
BO_ 902 RDR_Message_ADU7: 8 ADU
 SG_ RDR_ID386_Data8 : 63|8@0+ (1,0) [0|255] ""  CGW
 SG_ RDR_ID386_Data7 : 55|8@0+ (1,0) [0|255] ""  CGW
 SG_ RDR_ID386_Data6 : 47|8@0+ (1,0) [0|255] ""  CGW
 SG_ RDR_ID386_Data5 : 39|8@0+ (1,0) [0|255] ""  CGW
 SG_ RDR_ID386_Data4 : 31|8@0+ (1,0) [0|255] ""  CGW
 SG_ RDR_ID386_Data3 : 23|8@0+ (1,0) [0|255] ""  CGW
 SG_ RDR_ID386_Data2 : 15|8@0+ (1,0) [0|255] ""  CGW
 SG_ RDR_ID386_Data1 : 7|8@0+ (1,0) [0|255] ""  CGW

BO_ 901 RDR_Message_ADU6: 8 ADU
 SG_ RDR_ID385_Data8 : 63|8@0+ (1,0) [0|255] ""  CGW
 SG_ RDR_ID385_Data7 : 55|8@0+ (1,0) [0|255] ""  CGW
 SG_ RDR_ID385_Data6 : 47|8@0+ (1,0) [0|255] ""  CGW
 SG_ RDR_ID385_Data5 : 39|8@0+ (1,0) [0|255] ""  CGW
 SG_ RDR_ID385_Data4 : 31|8@0+ (1,0) [0|255] ""  CGW
 SG_ RDR_ID385_Data3 : 23|8@0+ (1,0) [0|255] ""  CGW
 SG_ RDR_ID385_Data2 : 15|8@0+ (1,0) [0|255] ""  CGW
 SG_ RDR_ID385_Data1 : 7|8@0+ (1,0) [0|255] ""  CGW

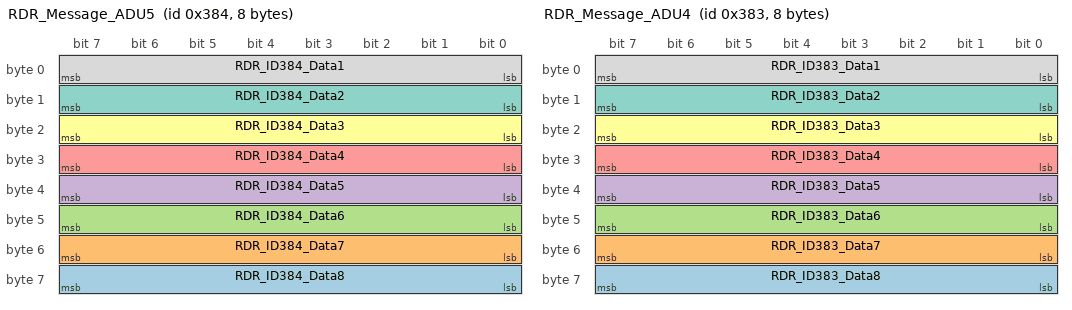
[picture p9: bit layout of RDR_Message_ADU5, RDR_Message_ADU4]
BO_ 900 RDR_Message_ADU5: 8 ADU
 SG_ RDR_ID384_Data8 : 63|8@0+ (1,0) [0|255] ""  CGW
 SG_ RDR_ID384_Data7 : 55|8@0+ (1,0) [0|255] ""  CGW
 SG_ RDR_ID384_Data6 : 47|8@0+ (1,0) [0|255] ""  CGW
 SG_ RDR_ID384_Data5 : 39|8@0+ (1,0) [0|255] ""  CGW
 SG_ RDR_ID384_Data4 : 31|8@0+ (1,0) [0|255] ""  CGW
 SG_ RDR_ID384_Data3 : 23|8@0+ (1,0) [0|255] ""  CGW
 SG_ RDR_ID384_Data2 : 15|8@0+ (1,0) [0|255] ""  CGW
 SG_ RDR_ID384_Data1 : 7|8@0+ (1,0) [0|255] ""  CGW

BO_ 899 RDR_Message_ADU4: 8 ADU
 SG_ RDR_ID383_Data8 : 63|8@0+ (1,0) [0|255] ""  CGW
 SG_ RDR_ID383_Data7 : 55|8@0+ (1,0) [0|255] ""  CGW
 SG_ RDR_ID383_Data6 : 47|8@0+ (1,0) [0|255] ""  CGW
 SG_ RDR_ID383_Data5 : 39|8@0+ (1,0) [0|255] ""  CGW
 SG_ RDR_ID383_Data4 : 31|8@0+ (1,0) [0|255] ""  CGW
 SG_ RDR_ID383_Data3 : 23|8@0+ (1,0) [0|255] ""  CGW
 SG_ RDR_ID383_Data2 : 15|8@0+ (1,0) [0|255] ""  CGW
 SG_ RDR_ID383_Data1 : 7|8@0+ (1,0) [0|255] ""  CGW

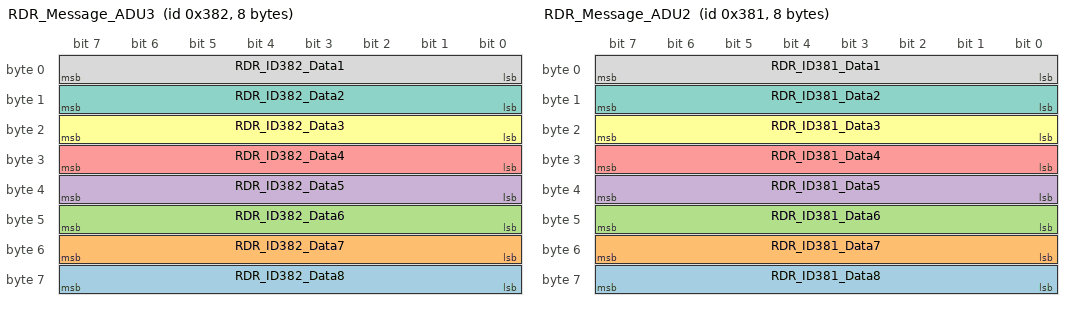
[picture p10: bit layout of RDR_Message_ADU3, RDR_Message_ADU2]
BO_ 898 RDR_Message_ADU3: 8 ADU
 SG_ RDR_ID382_Data8 : 63|8@0+ (1,0) [0|255] ""  CGW
 SG_ RDR_ID382_Data7 : 55|8@0+ (1,0) [0|255] ""  CGW
 SG_ RDR_ID382_Data6 : 47|8@0+ (1,0) [0|255] ""  CGW
 SG_ RDR_ID382_Data5 : 39|8@0+ (1,0) [0|255] ""  CGW
 SG_ RDR_ID382_Data4 : 31|8@0+ (1,0) [0|255] ""  CGW
 SG_ RDR_ID382_Data3 : 23|8@0+ (1,0) [0|255] ""  CGW
 SG_ RDR_ID382_Data2 : 15|8@0+ (1,0) [0|255] ""  CGW
 SG_ RDR_ID382_Data1 : 7|8@0+ (1,0) [0|255] ""  CGW

BO_ 897 RDR_Message_ADU2: 8 ADU
 SG_ RDR_ID381_Data8 : 63|8@0+ (1,0) [0|255] ""  CGW
 SG_ RDR_ID381_Data7 : 55|8@0+ (1,0) [0|255] ""  CGW
 SG_ RDR_ID381_Data6 : 47|8@0+ (1,0) [0|255] ""  CGW
 SG_ RDR_ID381_Data5 : 39|8@0+ (1,0) [0|255] ""  CGW
 SG_ RDR_ID381_Data4 : 31|8@0+ (1,0) [0|255] ""  CGW
 SG_ RDR_ID381_Data3 : 23|8@0+ (1,0) [0|255] ""  CGW
 SG_ RDR_ID381_Data2 : 15|8@0+ (1,0) [0|255] ""  CGW
 SG_ RDR_ID381_Data1 : 7|8@0+ (1,0) [0|255] ""  CGW

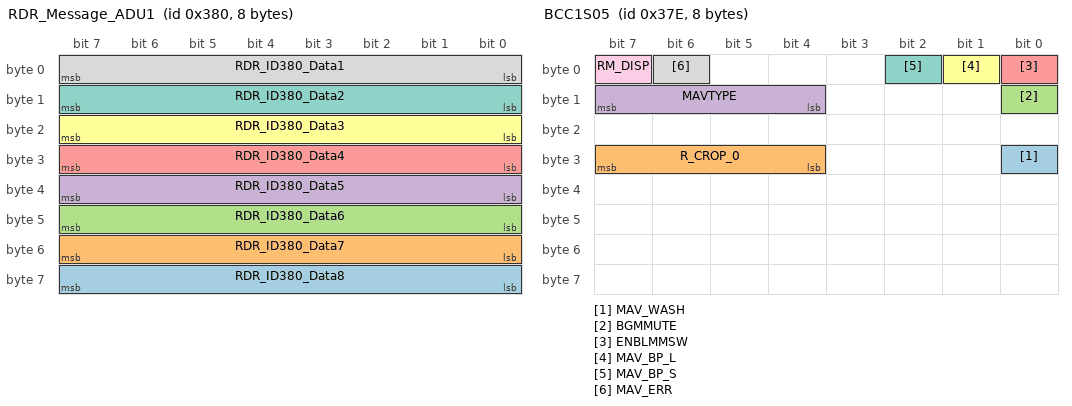
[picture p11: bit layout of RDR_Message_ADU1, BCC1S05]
BO_ 896 RDR_Message_ADU1: 8 ADU
 SG_ RDR_ID380_Data8 : 63|8@0+ (1,0) [0|255] ""  CGW
 SG_ RDR_ID380_Data7 : 55|8@0+ (1,0) [0|255] ""  CGW
 SG_ RDR_ID380_Data6 : 47|8@0+ (1,0) [0|255] ""  CGW
 SG_ RDR_ID380_Data5 : 39|8@0+ (1,0) [0|255] ""  CGW
 SG_ RDR_ID380_Data4 : 31|8@0+ (1,0) [0|255] ""  CGW
 SG_ RDR_ID380_Data3 : 23|8@0+ (1,0) [0|255] ""  CGW
 SG_ RDR_ID380_Data2 : 15|8@0+ (1,0) [0|255] ""  CGW
 SG_ RDR_ID380_Data1 : 7|8@0+ (1,0) [0|255] ""  CGW

BO_ 894 BCC1S05: 8 ADU
 SG_ MAV_WASH : 24|1@0+ (1,0) [0|0] ""  CGW
 SG_ R_CROP_0 : 31|4@0+ (1,0) [0|0] ""  CGW
 SG_ BGMMUTE : 8|1@0+ (1,0) [0|0] ""  CGW
 SG_ MAVTYPE : 15|4@0+ (1,0) [0|0] ""  CGW
 SG_ ENBLMMSW : 0|1@0+ (1,0) [0|0] ""  CGW
 SG_ MAV_BP_L : 1|1@0+ (1,0) [0|0] ""  CGW
 SG_ MAV_BP_S : 2|1@0+ (1,0) [0|0] ""  CGW
 SG_ MAV_ERR : 6|1@0+ (1,0) [0|0] ""  CGW
 SG_ RM_DISP : 7|1@0+ (1,0) [0|0] ""  CGW

BO_ 893 DS11S35: 32 ADU
 SG_ LCDRSTE : 207|3@0+ (1,0) [0|0] ""  CGW
 SG_ LCDRINV : 192|1@0+ (1,0) [0|0] ""  CGW
 SG_ EDAPHZ : 159|3@0+ (1,0) [0|0] ""  CGW
 SG_ EDAHZD : 150|2@0+ (1,0) [0|0] ""  CGW
 SG_ EDAHRN : 151|1@0+ (1,0) [0|0] ""  CGW
 SG_ EDRLCA : 82|3@0+ (1,0) [0|0] ""  CGW
 SG_ EDRAES : 74|3@0+ (1,0) [0|0] ""  CGW
 SG_ EDRLTA : 78|3@0+ (1,0) [0|0] ""  CGW
 SG_ EDRESA : 70|3@0+ (1,0) [0|0] ""  CGW
 SG_ EDRLDWS : 59|4@0+ (1,0) [0|0] ""  CGW
 SG_ EDRLDA : 62|3@0+ (1,0) [0|0] ""  CGW

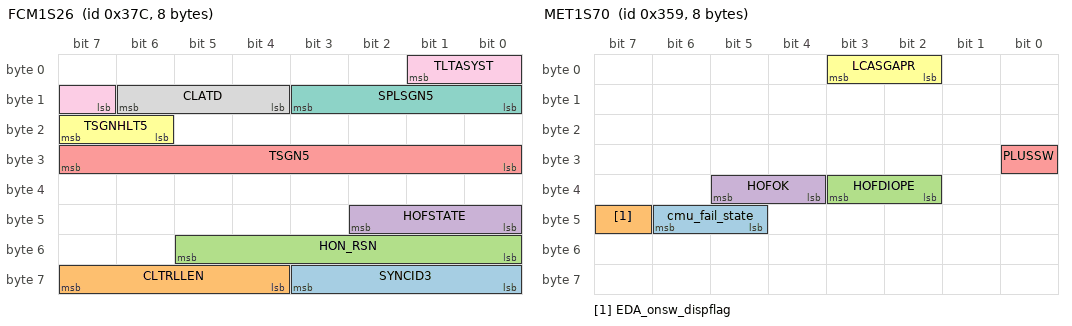
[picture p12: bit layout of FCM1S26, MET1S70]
BO_ 892 FCM1S26: 8 ADU
 SG_ SYNCID3 : 59|4@0+ (1,0) [0|15] ""  CGW
 SG_ CLTRLLEN : 63|4@0+ (1,0) [0|15] ""  CGW
 SG_ HON_RSN : 53|6@0+ (1,0) [0|63] ""  CGW
 SG_ HOFSTATE : 42|3@0+ (1,0) [0|7] ""  CGW
 SG_ TSGN5 : 31|8@0+ (1,0) [0|255] ""  CGW
 SG_ TSGNHLT5 : 23|2@0+ (1,0) [0|3] ""  CGW
 SG_ SPLSGN5 : 11|4@0+ (1,0) [0|15] ""  CGW
 SG_ CLATD : 14|3@0+ (1,0) [0|7] ""  CGW
 SG_ TLTASYST : 1|3@0+ (1,0) [0|7] ""  CGW

BO_ 857 MET1S70: 8 CGW
 SG_ cmu_fail_state : 46|2@0+ (1,0) [0|0] ""  ADU
 SG_ EDA_onsw_dispflag : 47|1@0+ (1,0) [0|0] ""  ADU
 SG_ HOFDIOPE : 35|2@0+ (1,0) [0|0] ""  ADU
 SG_ HOFOK : 37|2@0+ (1,0) [0|3] ""  ADU
 SG_ PLUSSW : 24|1@0+ (1,0) [0|1] ""  ADU
 SG_ LCASGAPR : 3|2@0+ (1,0) [0|3] ""  ADU

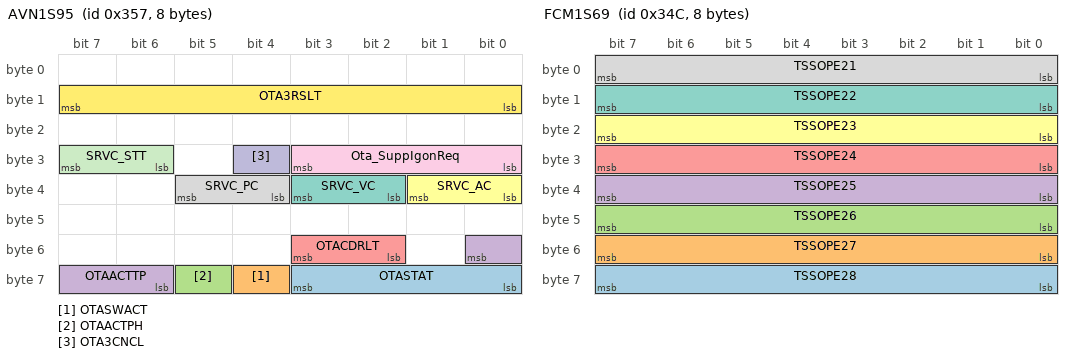
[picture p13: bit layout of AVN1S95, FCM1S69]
BO_ 855 AVN1S95: 8 CGW
 SG_ OTASTAT : 59|4@0+ (1,0) [0|15] ""  ADU
 SG_ OTASWACT : 60|1@0+ (1,0) [0|1] ""  ADU
 SG_ OTAACTPH : 61|1@0+ (1,0) [0|1] ""  ADU
 SG_ OTAACTTP : 48|3@0+ (1,0) [0|7] ""  ADU
 SG_ OTACDRLT : 51|2@0+ (1,0) [0|3] ""  ADU
 SG_ SRVC_AC : 33|2@0+ (1,0) [0|0] "" Vector__XXX
 SG_ SRVC_VC : 35|2@0+ (1,0) [0|0] ""  ADU
 SG_ SRVC_PC : 37|2@0+ (1,0) [0|0] ""  ADU
 SG_ Ota_SuppIgonReq : 27|4@0+ (1,0) [0|0] "" Vector__XXX
 SG_ OTA3CNCL : 28|1@0+ (1,0) [0|1] ""  ADU
 SG_ SRVC_STT : 31|2@0+ (1,0) [0|0] ""  ADU
 SG_ OTA3RSLT : 15|8@0+ (1,0) [0|255] ""  ADU

BO_ 854 AVN1SA5: 32 CGW
 SG_ SPLDIST2 : 246|8@0+ (1,0) [0|255] "m"  ADU
 SG_ SPLUNT2 : 247|1@0+ (1,0) [0|1] ""  ADU
 SG_ SPLDIST1 : 239|8@0+ (1,0) [0|255] "m"  ADU
 SG_ SPLUNT1 : 224|1@0+ (1,0) [0|1] ""  ADU
 SG_ SNBDIST2 : 216|8@0+ (1,0) [0|255] "m"  ADU
 SG_ SNBUNT2 : 217|1@0+ (1,0) [0|1] ""  ADU
 SG_ SNBINF2 : 219|2@0+ (1,0) [0|3] ""  ADU
 SG_ SNBDIST1 : 211|8@0+ (1,0) [0|255] "m"  ADU
 SG_ SNBUNT1 : 212|1@0+ (1,0) [0|1] ""  ADU
 SG_ SNBINF1 : 214|2@0+ (1,0) [0|3] ""  ADU
 SG_ CURINF8 : 194|12@0+ (1,0) [0|4095] ""  ADU
 SG_ CURVAL8 : 190|12@0+ (1,0) [0|4095] ""  ADU
 SG_ CURINF7 : 170|12@0+ (1,0) [0|4095] ""  ADU
 SG_ CURVAL7 : 166|12@0+ (1,0) [0|4095] ""  ADU
 SG_ CURINF6 : 146|12@0+ (1,0) [0|4095] ""  ADU
 SG_ CURVAL6 : 142|12@0+ (1,0) [0|4095] ""  ADU
 SG_ CURINF5 : 122|12@0+ (1,0) [0|4095] ""  ADU
 SG_ CURVAL5 : 118|12@0+ (1,0) [0|4095] ""  ADU
 SG_ CURINF4 : 98|12@0+ (1,0) [0|4095] ""  ADU
 SG_ CURVAL4 : 94|12@0+ (1,0) [0|4095] ""  ADU
 SG_ CURINF3 : 74|12@0+ (1,0) [0|4095] ""  ADU
 SG_ CURVAL3 : 70|12@0+ (1,0) [0|4095] ""  ADU
 SG_ CURINF2 : 50|12@0+ (1,0) [0|4095] ""  ADU
 SG_ CURVAL2 : 46|12@0+ (1,0) [0|4095] ""  ADU
 SG_ CURINF1 : 26|12@0+ (1,0) [0|4095] ""  ADU
 SG_ CURVAL1 : 22|12@0+ (1,0) [0|4095] ""  ADU
 SG_ CURINFO2 : 2|12@0+ (1,0) [0|4095] ""  ADU
 SG_ FRMSID5 : 7|5@0+ (1,0) [0|31] ""  ADU

BO_ 851 AVN1SA4: 32 CGW
 SG_ ALTYP3 : 243|10@0+ (1,0) [0|1023] ""  ADU
 SG_ ALRDTY3 : 232|5@0+ (1,0) [0|31] ""  ADU
 SG_ SPDIST2 : 224|8@0+ (1,0) [0|255] "m"  ADU
 SG_ SPDISTU2 : 225|1@0+ (1,0) [0|1] ""  ADU
 SG_ FWSPAU2 : 229|4@0+ (1,0) [0|15] ""  ADU
 SG_ FWSPTY2 : 216|3@0+ (1,0) [0|7] ""  ADU
 SG_ FWSPD2 : 221|5@0+ (1,0) [0|31] ""  ADU
 SG_ SPDIST1 : 213|8@0+ (1,0) [0|255] "m"  ADU
 SG_ SPDISTU1 : 214|1@0+ (1,0) [0|1] ""  ADU
 SG_ FWSPAU1 : 202|4@0+ (1,0) [0|15] ""  ADU
 SG_ FWSPTY1 : 205|3@0+ (1,0) [0|7] ""  ADU
 SG_ FWSPD1 : 194|5@0+ (1,0) [0|31] ""  ADU
 SG_ MPSPAU1 : 198|4@0+ (1,0) [0|15] ""  ADU
 SG_ MPSPTY1 : 185|3@0+ (1,0) [0|7] ""  ADU
 SG_ MPSP1 : 190|5@0+ (1,0) [0|31] ""  ADU
 SG_ NALRDTY6 : 179|5@0+ (1,0) [0|31] ""  ADU
 SG_ NALRDTY5 : 168|5@0+ (1,0) [0|31] ""  ADU
 SG_ NALRDTY4 : 173|5@0+ (1,0) [0|31] ""  ADU
 SG_ NALRDTY3 : 162|5@0+ (1,0) [0|31] ""  ADU
 SG_ NALRDTY2 : 167|5@0+ (1,0) [0|31] ""  ADU
 SG_ NALRDTY1 : 156|5@0+ (1,0) [0|31] ""  ADU
 SG_ NALANG6 : 146|6@0+ (1,0) [0|63] ""  ADU
 SG_ NALNEN6 : 148|2@0+ (1,0) [0|3] ""  ADU
 SG_ NALNLN6 : 136|4@0+ (1,0) [0|15] ""  ADU
 SG_ NALTYP6 : 130|10@0+ (1,0) [0|1023] ""  ADU
 SG_ NALINT6 : 133|3@0+ (1,0) [0|7] ""  ADU
 SG_ NALANG5 : 123|6@0+ (1,0) [0|63] ""  ADU
 SG_ NALNEN5 : 125|2@0+ (1,0) [0|3] ""  ADU
 SG_ NALNLN5 : 113|4@0+ (1,0) [0|15] ""  ADU
 SG_ NALTYP5 : 107|10@0+ (1,0) [0|1023] ""  ADU
 SG_ NALINT5 : 110|3@0+ (1,0) [0|7] ""  ADU
 SG_ NALANG4 : 100|6@0+ (1,0) [0|63] ""  ADU
 SG_ NALNEN4 : 102|2@0+ (1,0) [0|3] ""  ADU
 SG_ NALNLN4 : 90|4@0+ (1,0) [0|15] ""  ADU
 SG_ NALTYP4 : 84|10@0+ (1,0) [0|1023] ""  ADU
 SG_ NALINT4 : 87|3@0+ (1,0) [0|7] ""  ADU
 SG_ NALANG3 : 77|6@0+ (1,0) [0|63] ""  ADU
 SG_ NALNEN3 : 79|2@0+ (1,0) [0|3] ""  ADU
 SG_ NALNLN3 : 67|4@0+ (1,0) [0|15] ""  ADU
 SG_ NALTYP3 : 61|10@0+ (1,0) [0|1023] ""  ADU
 SG_ NALINT3 : 48|3@0+ (1,0) [0|7] ""  ADU
 SG_ NALANG2 : 54|6@0+ (1,0) [0|63] ""  ADU
 SG_ NALNEN2 : 40|2@0+ (1,0) [0|3] ""  ADU
 SG_ NALNLN2 : 44|4@0+ (1,0) [0|15] ""  ADU
 SG_ NALTYP2 : 38|10@0+ (1,0) [0|1023] ""  ADU
 SG_ NALINT2 : 25|3@0+ (1,0) [0|7] ""  ADU
 SG_ NALANG1 : 31|6@0+ (1,0) [0|63] ""  ADU
 SG_ NALNEN1 : 17|2@0+ (1,0) [0|3] ""  ADU
 SG_ NALNLN1 : 21|4@0+ (1,0) [0|15] ""  ADU
 SG_ NALTYP1 : 15|10@0+ (1,0) [0|1023] ""  ADU
 SG_ NALINT1 : 2|3@0+ (1,0) [0|7] ""  ADU
 SG_ FRMSID3 : 7|5@0+ (1,0) [0|31] ""  ADU

BO_ 850 AVN1SA3: 32 CGW
 SG_ INTID2 : 252|3@0+ (1,0) [0|7] ""  ADU
 SG_ INTID1 : 255|3@0+ (1,0) [0|7] ""  ADU
 SG_ RLDXUNT2 : 240|1@0+ (1,0) [0|1] ""  ADU
 SG_ RLDXUNT1 : 241|1@0+ (1,0) [0|1] ""  ADU
 SG_ ALANG3 : 247|6@0+ (1,0) [0|63] ""  ADU
 SG_ ALNLN3 : 235|4@0+ (1,0) [0|15] ""  ADU
 SG_ CURINF10 : 231|12@0+ (1,0) [0|4095] ""  ADU
 SG_ ALNLN2 : 219|4@0+ (1,0) [0|15] ""  ADU
 SG_ CURVAL10 : 215|12@0+ (1,0) [0|4095] ""  ADU
 SG_ ENSIBD2 : 201|2@0+ (1,0) [0|3] ""  ADU
 SG_ ENSIBD1 : 203|2@0+ (1,0) [0|3] ""  ADU
 SG_ CURINF9 : 199|12@0+ (1,0) [0|4095] ""  ADU
 SG_ ALNLN1 : 187|4@0+ (1,0) [0|15] ""  ADU
 SG_ CURVAL9 : 183|12@0+ (1,0) [0|4095] ""  ADU
 SG_ RLDXDST2 : 175|8@0+ (1,0) [0|255] "m"  ADU
 SG_ RLDXDST1 : 167|8@0+ (1,0) [0|255] "m"  ADU
 SG_ TRLDIST2 : 159|8@0+ (1,0) [0|255] "m"  ADU
 SG_ TRLDIST1 : 151|8@0+ (1,0) [0|255] "m"  ADU
 SG_ PAYMTB1 : 143|8@0+ (1,0) [0|255] ""  ADU
 SG_ PAYMTA1 : 135|8@0+ (1,0) [0|255] ""  ADU
 SG_ TOLSTY1 : 127|8@0+ (1,0) [0|255] ""  ADU
 SG_ TOLDIST1 : 119|8@0+ (1,0) [0|255] "m"  ADU
 SG_ TRLUNT2 : 104|1@0+ (1,0) [0|1] ""  ADU
 SG_ ALRDTY2 : 109|5@0+ (1,0) [0|31] ""  ADU
 SG_ ALTYP2 : 103|10@0+ (1,0) [0|1023] ""  ADU
 SG_ TRLUNT1 : 88|1@0+ (1,0) [0|1] ""  ADU
 SG_ ALRDTY1 : 93|5@0+ (1,0) [0|31] ""  ADU
 SG_ ALTYP1 : 87|10@0+ (1,0) [0|1023] ""  ADU
 SG_ ALANG2 : 77|6@0+ (1,0) [0|63] ""  ADU
 SG_ ENLNTY2 : 71|10@0+ (1,0) [0|1023] ""  ADU
 SG_ ALANG1 : 61|6@0+ (1,0) [0|63] ""  ADU
 SG_ ENLNTY1 : 55|10@0+ (1,0) [0|1023] ""  ADU
 SG_ ENSIG2 : 41|2@0+ (1,0) [0|3] ""  ADU
 SG_ ENSIG1 : 43|2@0+ (1,0) [0|3] ""  ADU
 SG_ ENRDTY2 : 32|5@0+ (1,0) [0|31] ""  ADU
 SG_ ENRDTY1 : 37|5@0+ (1,0) [0|31] ""  ADU
 SG_ INTNLN2 : 26|5@0+ (1,0) [0|31] ""  ADU
 SG_ INTNLN1 : 31|5@0+ (1,0) [0|31] ""  ADU
 SG_ INTDIS2 : 23|8@0+ (1,0) [0|255] "m"  ADU
 SG_ INTDIS1 : 15|8@0+ (1,0) [0|255] "m"  ADU
 SG_ TOLDU1 : 0|1@0+ (1,0) [0|1] ""  ADU
 SG_ INTDISU2 : 1|1@0+ (1,0) [0|1] ""  ADU
 SG_ INTDISU1 : 2|1@0+ (1,0) [0|1] ""  ADU
 SG_ FRMSID2 : 7|5@0+ (1,0) [0|31] ""  ADU

BO_ 849 AVN1SA2: 32 CGW
 SG_ INTID3 : 254|3@0+ (1,0) [0|7] ""  ADU
 SG_ DFLGDU2 : 255|1@0+ (1,0) [0|1] ""  ADU
 SG_ DWAYFLG2 : 241|2@0+ (1,0) [0|3] ""  ADU
 SG_ DWAYFLG1 : 243|2@0+ (1,0) [0|3] ""  ADU
 SG_ CURINF11 : 239|12@0+ (1,0) [0|4095] ""  ADU
 SG_ MPOSDFLG : 225|2@0+ (1,0) [0|3] ""  ADU
 SG_ MAPTYRO : 227|2@0+ (1,0) [0|3] ""  ADU
 SG_ CURVAL11 : 223|12@0+ (1,0) [0|4095] ""  ADU
 SG_ DFLGD2 : 215|8@0+ (1,0) [0|255] "m"  ADU
 SG_ DFLGD1 : 207|8@0+ (1,0) [0|255] "m"  ADU
 SG_ DFLGDU1 : 192|1@0+ (1,0) [0|1] ""  ADU
 SG_ ENRDTY3 : 197|5@0+ (1,0) [0|31] ""  ADU
 SG_ ENSIBD3 : 199|2@0+ (1,0) [0|3] ""  ADU
 SG_ INTNLN3 : 188|5@0+ (1,0) [0|31] ""  ADU
 SG_ INTDISU3 : 189|1@0+ (1,0) [0|1] ""  ADU
 SG_ ENLNTY3 : 183|10@0+ (1,0) [0|1023] ""  ADU
 SG_ INTDIS3 : 175|8@0+ (1,0) [0|255] "m"  ADU
 SG_ LNNUMD3 : 167|8@0+ (1,0) [0|255] "m"  ADU
 SG_ LNNUMD2 : 159|8@0+ (1,0) [0|255] "m"  ADU
 SG_ LNNUMD1 : 151|8@0+ (1,0) [0|255] "m"  ADU
 SG_ LNNUM3 : 139|4@0+ (1,0) [0|15] ""  ADU
 SG_ LNNUM2 : 143|4@0+ (1,0) [0|15] ""  ADU
 SG_ LNNUM1 : 131|4@0+ (1,0) [0|15] ""  ADU
 SG_ ENSIG3 : 133|2@0+ (1,0) [0|3] ""  ADU
 SG_ LNNUMDU3 : 134|1@0+ (1,0) [0|1] ""  ADU
 SG_ LNNUMDU2 : 135|1@0+ (1,0) [0|1] ""  ADU
 SG_ LNNUMDU1 : 120|1@0+ (1,0) [0|1] ""  ADU
 SG_ MPLNNUM : 124|4@0+ (1,0) [0|15] ""  ADU
 SG_ MPMEDFLG : 126|2@0+ (1,0) [0|3] ""  ADU
 SG_ MPLNKTYP : 104|10@0+ (1,0) [0|1023] ""  ADU
 SG_ RDTYPD2 : 96|8@0+ (1,0) [0|255] "m"  ADU
 SG_ RDTYPDU2 : 97|1@0+ (1,0) [0|1] ""  ADU
 SG_ FWRDTYP2 : 102|5@0+ (1,0) [0|31] ""  ADU
 SG_ RDTYPD1 : 94|8@0+ (1,0) [0|255] "m"  ADU
 SG_ RDTYPDU1 : 95|1@0+ (1,0) [0|1] ""  ADU
 SG_ FWRDTYP1 : 84|5@0+ (1,0) [0|31] ""  ADU
 SG_ MPRDTYP : 73|5@0+ (1,0) [0|31] ""  ADU
 SG_ RERTCNTR : 77|4@0+ (1,0) [0|15] ""  ADU
 SG_ CNTRYCD : 71|10@0+ (1,0) [0|1023] ""  ADU
 SG_ DAYFMUPD : 39|32@0+ (1,0) [0|4294967295] ""  ADU
 SG_ MOBNAVST : 28|5@0+ (1,0) [0|31] ""  ADU
 SG_ MAPCNFLG : 30|2@0+ (1,0) [0|3] ""  ADU
 SG_ MAPCVR : 16|2@0+ (1,0) [0|3] ""  ADU
 SG_ MLTMDST : 18|2@0+ (1,0) [0|3] ""  ADU
 SG_ MAPMCNFD : 10|8@0+ (1,0) [0|255] ""  ADU
 SG_ RTGUIDST : 12|2@0+ (1,0) [0|3] ""  ADU
 SG_ SENSORF : 15|3@0+ (1,0) [0|7] ""  ADU
 SG_ SENSST : 2|3@0+ (1,0) [0|7] ""  ADU
 SG_ FRMSID1 : 7|5@0+ (1,0) [0|31] ""  ADU

BO_ 848 AVN1SA6: 8 CGW
 SG_ RECRNOFF : 14|4@0+ (1,0) [0|0] "" Vector__XXX
 SG_ WUREQ : 15|1@0+ (1,0) [0|0] ""  ADU
 SG_ RECEND : 0|1@0+ (1,0) [0|0] "" Vector__XXX
 SG_ IMGI_POF : 1|1@0+ (1,0) [0|0] ""  ADU

BO_ 847 DS11S37: 8 ADU
 SG_ ID34F_No_Cs : 63|8@0+ (1,0) [0|255] ""  CGW
 SG_ LCFP : 51|2@0+ (1,0) [0|0] ""  CGW
 SG_ DM_BZR : 55|4@0+ (1,0) [0|0] ""  CGW
 SG_ LCAINDI : 42|3@0+ (1,0) [0|0] ""  CGW
 SG_ DM_DISPM : 46|4@0+ (1,0) [0|0] ""  CGW
 SG_ DM_HRNRQ : 47|1@0+ (1,0) [0|0] ""  CGW
 SG_ DM_DRULK : 32|1@0+ (1,0) [0|0] ""  CGW
 SG_ ACCSPMEX : 33|1@0+ (1,0) [0|0] ""  CGW
 SG_ ACCSPMD : 35|2@0+ (1,0) [0|0] ""  CGW
 SG_ DM_TRNRQ : 39|3@0+ (1,0) [0|0] ""  CGW
 SG_ LCSRWNGD : 25|2@0+ (1,0) [0|0] ""  CGW
 SG_ LCSARRRD : 28|3@0+ (1,0) [0|0] ""  CGW
 SG_ LCSARRLD : 31|3@0+ (1,0) [0|0] ""  CGW
 SG_ LCSLWNGD : 17|2@0+ (1,0) [0|0] ""  CGW
 SG_ LCASGIND : 21|4@0+ (1,0) [0|0] ""  CGW
 SG_ LCAMSG : 9|4@0+ (1,0) [0|0] ""  CGW
 SG_ LCWNKONR : 10|1@0+ (1,0) [0|0] ""  CGW
 SG_ LCWNKONL : 11|1@0+ (1,0) [0|0] ""  CGW
 SG_ DISPREQA : 12|1@0+ (1,0) [0|0] ""  CGW
 SG_ DISPUP : 13|1@0+ (1,0) [0|0] ""  CGW
 SG_ LTCMODE : 14|1@0+ (1,0) [0|0] ""  CGW
 SG_ LCSONSD : 15|1@0+ (1,0) [0|0] ""  CGW
 SG_ LCSRQBZ : 1|1@0+ (1,0) [0|0] ""  CGW
 SG_ LCAVCBZ : 2|1@0+ (1,0) [0|0] ""  CGW
 SG_ LCANGBZ : 3|1@0+ (1,0) [0|0] ""  CGW
 SG_ ID34F_No_Cnt : 7|4@0+ (1,0) [0|15] "counter"  CGW

BO_ 846 BSR1S03: 8 ADU
 SG_ OMI_R : 36|2@0+ (1,0) [0|0] ""  CGW
 SG_ OMI_L : 38|2@0+ (1,0) [0|0] ""  CGW

BO_ 845 TRA1S01: 8 ADU
 SG_ TRABUZ : 5|2@0+ (1,0) [0|3] ""  CGW

BO_ 844 FCM1S69: 8 ADU
 SG_ TSSOPE28 : 63|8@0+ (1,0) [0|255] ""  CGW
 SG_ TSSOPE27 : 55|8@0+ (1,0) [0|255] ""  CGW
 SG_ TSSOPE26 : 47|8@0+ (1,0) [0|255] ""  CGW
 SG_ TSSOPE25 : 39|8@0+ (1,0) [0|255] ""  CGW
 SG_ TSSOPE24 : 31|8@0+ (1,0) [0|255] ""  CGW
 SG_ TSSOPE23 : 23|8@0+ (1,0) [0|255] ""  CGW
 SG_ TSSOPE22 : 15|8@0+ (1,0) [0|255] ""  CGW
 SG_ TSSOPE21 : 7|8@0+ (1,0) [0|255] ""  CGW

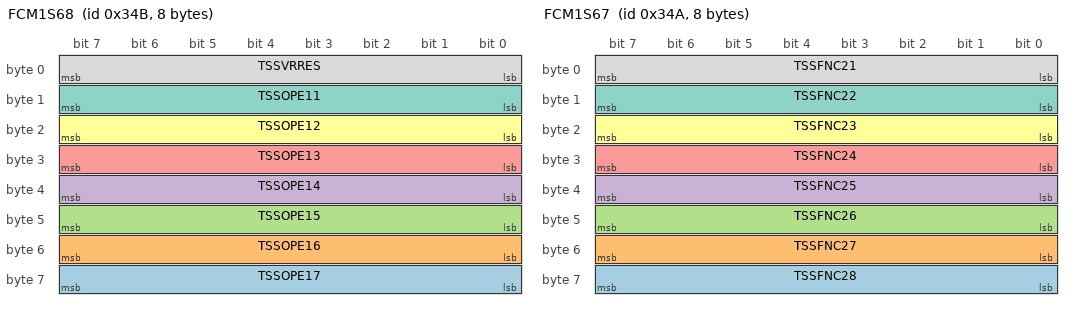
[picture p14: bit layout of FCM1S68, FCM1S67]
BO_ 843 FCM1S68: 8 ADU
 SG_ TSSOPE17 : 63|8@0+ (1,0) [0|255] ""  CGW
 SG_ TSSOPE16 : 55|8@0+ (1,0) [0|255] ""  CGW
 SG_ TSSOPE15 : 47|8@0+ (1,0) [0|255] ""  CGW
 SG_ TSSOPE14 : 39|8@0+ (1,0) [0|255] ""  CGW
 SG_ TSSOPE13 : 31|8@0+ (1,0) [0|255] ""  CGW
 SG_ TSSOPE12 : 23|8@0+ (1,0) [0|255] ""  CGW
 SG_ TSSOPE11 : 15|8@0+ (1,0) [0|255] ""  CGW
 SG_ TSSVRRES : 7|8@0+ (1,0) [0|255] ""  CGW

BO_ 842 FCM1S67: 8 ADU
 SG_ TSSFNC28 : 63|8@0+ (1,0) [0|255] ""  CGW
 SG_ TSSFNC27 : 55|8@0+ (1,0) [0|255] ""  CGW
 SG_ TSSFNC26 : 47|8@0+ (1,0) [0|255] ""  CGW
 SG_ TSSFNC25 : 39|8@0+ (1,0) [0|255] ""  CGW
 SG_ TSSFNC24 : 31|8@0+ (1,0) [0|255] ""  CGW
 SG_ TSSFNC23 : 23|8@0+ (1,0) [0|255] ""  CGW
 SG_ TSSFNC22 : 15|8@0+ (1,0) [0|255] ""  CGW
 SG_ TSSFNC21 : 7|8@0+ (1,0) [0|255] ""  CGW

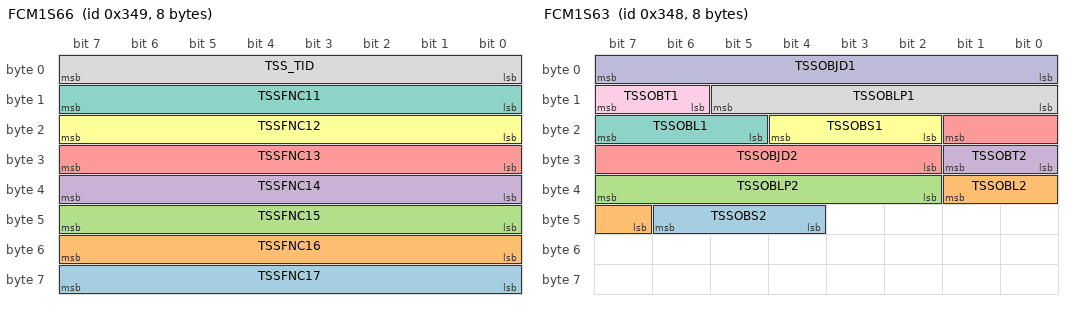
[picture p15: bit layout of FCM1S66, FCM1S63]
BO_ 841 FCM1S66: 8 ADU
 SG_ TSSFNC17 : 63|8@0+ (1,0) [0|255] ""  CGW
 SG_ TSSFNC16 : 55|8@0+ (1,0) [0|255] ""  CGW
 SG_ TSSFNC15 : 47|8@0+ (1,0) [0|255] ""  CGW
 SG_ TSSFNC14 : 39|8@0+ (1,0) [0|255] ""  CGW
 SG_ TSSFNC13 : 31|8@0+ (1,0) [0|255] ""  CGW
 SG_ TSSFNC12 : 23|8@0+ (1,0) [0|255] ""  CGW
 SG_ TSSFNC11 : 15|8@0+ (1,0) [0|255] ""  CGW
 SG_ TSS_TID : 7|8@0+ (1,0) [0|255] ""  CGW

BO_ 840 FCM1S63: 8 ADU
 SG_ TSSOBS2 : 46|3@0+ (1,0) [0|7] ""  CGW
 SG_ TSSOBL2 : 33|3@0+ (1,0) [0|7] ""  CGW
 SG_ TSSOBLP2 : 39|6@0+ (1,0) [0|63] ""  CGW
 SG_ TSSOBT2 : 25|2@0+ (1,0) [0|3] ""  CGW
 SG_ TSSOBJD2 : 17|8@0+ (1,0) [0|255] ""  CGW
 SG_ TSSOBS1 : 20|3@0+ (1,0) [0|7] ""  CGW
 SG_ TSSOBL1 : 23|3@0+ (1,0) [0|7] ""  CGW
 SG_ TSSOBLP1 : 13|6@0+ (1,0) [0|63] ""  CGW
 SG_ TSSOBT1 : 15|2@0+ (1,0) [0|3] ""  CGW
 SG_ TSSOBJD1 : 7|8@0+ (1,0) [0|255] ""  CGW

BO_ 839 FCM1S58: 8 ADU
 SG_ ACCVRAPR : 57|2@0+ (1,0) [0|3] ""  CGW
 SG_ CCSVRAPR : 59|2@0+ (1,0) [0|3] ""  CGW
 SG_ ISAVRAPR : 61|2@0+ (1,0) [0|3] ""  CGW
 SG_ LTAVRAPR : 63|2@0+ (1,0) [0|3] ""  CGW
 SG_ TSSMDREJ : 51|1@0+ (1,0) [0|1] ""  CGW
 SG_ GUI_LTA : 54|1@0+ (1,0) [0|1] ""  CGW
 SG_ GUI_MODE : 55|1@0+ (1,0) [0|1] ""  CGW
 SG_ LDAINDIM : 43|4@0+ (1,0) [0|15] ""  CGW
 SG_ PCSINDIM : 47|4@0+ (1,0) [0|15] ""  CGW
 SG_ FCMINDIR : 39|2@0+ (1,0) [0|3] ""  CGW
 SG_ TSSSPMS1 : 24|1@0+ (1,0) [0|1] ""  CGW
 SG_ TSSSPMS2 : 25|1@0+ (1,0) [0|1] ""  CGW
 SG_ TSSSPMS3 : 26|1@0+ (1,0) [0|1] ""  CGW
 SG_ GUI_DOWN : 30|1@0+ (1,0) [0|1] ""  CGW
 SG_ GUI_UP : 31|1@0+ (1,0) [0|1] ""  CGW
 SG_ TSSSPMD3 : 18|3@0+ (1,0) [0|7] ""  CGW
 SG_ TSSSPMD2 : 21|3@0+ (1,0) [0|7] ""  CGW
 SG_ GUI_SET : 22|1@0+ (1,0) [0|1] ""  CGW
 SG_ GUI_RES : 23|1@0+ (1,0) [0|1] ""  CGW
 SG_ TSSSPMD1 : 10|3@0+ (1,0) [0|7] ""  CGW
 SG_ TSSSPMSG : 13|3@0+ (1,0) [0|7] ""  CGW
 SG_ GUI_CAN : 14|1@0+ (1,0) [0|1] ""  CGW
 SG_ GUI_DIST : 15|1@0+ (1,0) [0|1] ""  CGW
 SG_ TSSSPSEL : 2|3@0+ (1,0) [0|7] ""  CGW
 SG_ TSSSPNUM : 5|3@0+ (1,0) [0|7] ""  CGW
 SG_ TSSSPDIS : 6|1@0+ (1,0) [0|1] ""  CGW
 SG_ GUI_MAIN : 7|1@0+ (1,0) [0|1] ""  CGW

BO_ 838 FCM1S54: 8 ADU
 SG_ OTAMSTAT : 27|4@0+ (1,0) [0|15] ""  CGW
 SG_ OTA3ERR : 23|8@0+ (1,0) [0|255] ""  CGW
 SG_ OTA3PROG : 15|8@0+ (1,0) [0|255] "%"  CGW
 SG_ OTA3STAT : 3|4@0+ (1,0) [0|15] ""  CGW
 SG_ OTA3TYPE : 7|4@0+ (1,0) [0|15] ""  CGW

BO_ 837 FCM1S52: 8 ADU
 SG_ PDAEXIST : 48|1@0+ (1,0) [0|0] ""  CGW
 SG_ PDAONST : 49|1@0+ (1,0) [0|0] ""  CGW
 SG_ SDGEXIST : 50|1@0+ (1,0) [0|0] ""  CGW
 SG_ SDGONST : 51|1@0+ (1,0) [0|0] ""  CGW
 SG_ SDGCONT : 52|1@0+ (1,0) [0|0] ""  CGW
 SG_ USMEXIST : 53|1@0+ (1,0) [0|0] ""  CGW
 SG_ USMONST : 54|1@0+ (1,0) [0|0] ""  CGW
 SG_ USMTLTYP : 41|2@0+ (1,0) [0|0] ""  CGW
 SG_ USMTLDSW : 44|1@0+ (1,0) [0|0] ""  CGW
 SG_ USMSW : 47|2@0+ (1,0) [0|0] ""  CGW
 SG_ USMDSE : 34|3@0+ (1,0) [0|0] ""  CGW
 SG_ USMDSPSW : 35|1@0+ (1,0) [0|0] ""  CGW
 SG_ ISAAVABL : 37|1@0+ (1,0) [0|0] ""  CGW
 SG_ TMNAVABL : 38|1@0+ (1,0) [0|0] ""  CGW
 SG_ TSSPOP : 25|2@0+ (1,0) [0|0] ""  CGW
 SG_ CCEX : 27|1@0+ (1,0) [0|0] ""  CGW
 SG_ CCAVABL : 28|1@0+ (1,0) [0|0] ""  CGW
 SG_ AHBEXIST : 16|1@0+ (1,0) [0|0] ""  CGW
 SG_ IDAAVABL : 8|1@0+ (1,0) [0|0] ""  CGW
 SG_ USMAVABL : 9|1@0+ (1,0) [0|0] ""  CGW
 SG_ AHBAVABL : 10|1@0+ (1,0) [0|0] ""  CGW
 SG_ ACCAVABL : 15|1@0+ (1,0) [0|0] ""  CGW
 SG_ PCSAVABL : 0|1@0+ (1,0) [0|0] ""  CGW
 SG_ TSSTUNA : 1|1@0+ (1,0) [0|0] ""  CGW
 SG_ TSSMALF : 2|1@0+ (1,0) [0|0] ""  CGW
 SG_ FRDTUCT : 3|1@0+ (1,0) [0|0] ""  CGW
 SG_ FRDTEMP : 4|1@0+ (1,0) [0|0] ""  CGW
 SG_ FRDDUST : 5|1@0+ (1,0) [0|0] ""  CGW
 SG_ FCMTEMP : 6|1@0+ (1,0) [0|0] ""  CGW
 SG_ FCMDUST : 7|1@0+ (1,0) [0|0] ""  CGW

BO_ 832 RCMStatusMessage_MAC: 32 CGW
 SG_ RCMStatusMessage_MACTx : 227|28@0+ (1,0) [0|268435455] "" Vector__XXX
 SG_ RCMStatusMessage_FVTx : 231|4@0+ (1,0) [0|15] "" Vector__XXX
 SG_ ID340_No_Cs : 223|8@0+ (1,0) [0|255] "" Vector__XXX
 SG_ ID340_No_Cnt : 211|4@0+ (1,0) [0|15] "" Vector__XXX
 SG_ Sensor_fault_condition : 143|16@0+ (1,0) [0|255] "" Vector__XXX
 SG_ AB_Config : 127|16@0+ (1,0) [0|255] "" Vector__XXX
 SG_ Time_from_1to2_at_multi_event : 119|8@0+ (100,0) [0|5000] "msec" Vector__XXX
 SG_ Max_lat_deltaV_second_old : 95|8@0+ (1,-100) [-100|100] "km/h" Vector__XXX
 SG_ Max_long_deltaV_second_old : 87|8@0+ (1,-100) [-100|100] "km/h" Vector__XXX
 SG_ Max_lat_deltaV_latest : 79|8@0+ (1,-100) [-100|100] "km/h" Vector__XXX
 SG_ Max_long_deltaV_latest : 71|8@0+ (1,-100) [-100|100] "km/h" Vector__XXX
 SG_ Event_Type_Info_second_old : 39|16@0+ (1,0) [0|255] "" Vector__XXX
 SG_ Event_Type_Info_latest : 23|16@0+ (1,0) [0|255] "" Vector__XXX
 SG_ RCM_EDRtype : 10|1@0+ (1,0) [0|0] "" Vector__XXX
 SG_ EDRTrigger : 12|2@0+ (1,0) [0|0] "" Vector__XXX
 SG_ FirstRowBucklePsngr_FD : 0|2@0+ (1,0) [0|0] "" Vector__XXX
 SG_ OCS_Status : 2|2@0+ (1,0) [0|0] "" Vector__XXX
 SG_ PAD_Ind_Req : 5|3@0+ (1,0) [0|0] "" Vector__XXX

BO_ 807 FCM1S51: 8 ADU
 SG_ USMDPRTR : 56|1@0+ (1,0) [0|1] ""  CGW
 SG_ USMDPRTL : 57|1@0+ (1,0) [0|1] ""  CGW
 SG_ USMAVDST : 60|3@0+ (1,0) [0|7] ""  CGW
 SG_ USMPVDST : 63|3@0+ (1,0) [0|7] ""  CGW
 SG_ USMBZ : 50|3@0+ (1,0) [0|0] ""  CGW
 SG_ USMBLNK : 51|1@0+ (1,0) [0|1] ""  CGW
 SG_ USMMSG : 55|4@0+ (1,0) [0|15] ""  CGW
 SG_ USMIRPTR : 40|1@0+ (1,0) [0|1] ""  CGW
 SG_ USMIRPTL : 41|1@0+ (1,0) [0|1] ""  CGW
 SG_ USMOR : 42|1@0+ (1,0) [0|0] ""  CGW
 SG_ USMDSPCR : 43|1@0+ (1,0) [0|0] ""  CGW
 SG_ USMDSPSS : 45|2@0+ (1,0) [0|3] ""  CGW
 SG_ USMDSPTL : 32|3@0+ (1,0) [0|0] ""  CGW
 SG_ USMIRQ : 33|1@0+ (1,0) [0|1] ""  CGW
 SG_ USMDSPPV : 35|2@0+ (1,0) [0|0] ""  CGW
 SG_ DWREQ : 37|2@0+ (1,0) [0|0] ""  CGW
 SG_ USMBLNK2 : 38|1@0+ (1,0) [0|1] ""  CGW
 SG_ USMAVPOS : 39|1@0+ (1,0) [0|1] ""  CGW
 SG_ USMAVCOL : 25|2@0+ (1,0) [0|3] ""  CGW
 SG_ IDAINDI : 27|2@0+ (1,0) [0|3] ""  CGW
 SG_ IDACON : 31|4@0+ (1,0) [0|15] ""  CGW
 SG_ IDAIRQ : 16|1@0+ (1,0) [0|1] ""  CGW
 SG_ IDADSPR : 19|3@0+ (1,0) [0|7] ""  CGW
 SG_ IDACAN : 21|2@0+ (1,0) [0|3] ""  CGW
 SG_ IDABUZZ : 23|2@0+ (1,0) [0|3] ""  CGW
 SG_ IDADSPC : 9|2@0+ (1,0) [0|3] ""  CGW
 SG_ IDAEMPR : 11|2@0+ (1,0) [0|3] ""  CGW
 SG_ IDAEMPL : 13|2@0+ (1,0) [0|3] ""  CGW
 SG_ IDAEMPC : 15|2@0+ (1,0) [0|3] ""  CGW
 SG_ IDAONST : 0|1@0+ (1,0) [0|1] ""  CGW
 SG_ IDASENST : 2|2@0+ (1,0) [0|3] ""  CGW
 SG_ IDAEXIST : 3|1@0+ (1,0) [0|1] ""  CGW
 SG_ IDADSPL : 7|3@0+ (1,0) [0|7] ""  CGW

BO_ 806 FCM1S49: 32 ADU
 SG_ OTHVRVPC : 225|11@0+ (0.1,-185) [-185|19.7] "km/h"  CGW
 SG_ OTHRVPC : 220|11@0+ (0.1,-185) [-185|19.7] "km/h"  CGW
 SG_ OTHOVLPC : 211|7@0+ (1,0) [0|127] "%"  CGW
 SG_ OTHHRVPC : 205|10@0+ (0.1,0) [0|102.3] "km/h"  CGW
 SG_ OTHDISPC : 198|9@0+ (0.1,0) [0|51.1] "m"  CGW
 SG_ OTHTRCYC : 199|1@0+ (1,0) [0|1] ""  CGW
 SG_ OTHCPRO : 186|1@0+ (1,0) [0|1] ""  CGW
 SG_ OTHFNSST : 191|5@0+ (1,0) [0|31] ""  CGW
 SG_ OTHRVLEX : 178|1@0+ (1,0) [0|1] ""  CGW
 SG_ OTHTNO : 183|5@0+ (1,0) [0|31] ""  CGW
 SG_ OTHHRVEL : 164|10@0- (0.1,0) [-51.2|51.1] "km/h"  CGW
 SG_ OTHVRVEL : 159|11@0+ (0.1,-185) [-185|19.7] "km/h"  CGW
 SG_ OTHTSSST : 151|8@0+ (1,0) [0|255] ""  CGW
 SG_ OTHFUNC : 140|4@0+ (1,0) [0|15] ""  CGW
 SG_ OTHGENE : 143|3@0+ (1,0) [0|7] ""  CGW
 SG_ OTHRDANG : 127|9@0- (1,0) [-256|255] "deg"  CGW
 SG_ OTHOVLAP : 118|7@0+ (1,0) [0|127] "%"  CGW
 SG_ OTHHRDIS : 111|9@0- (0.05,0) [-12.8|12.75] "m"  CGW
 SG_ OTHVRDIS : 103|8@0+ (0.1,0) [0|25.5] "m"  CGW
 SG_ OTHRVEL : 87|11@0+ (0.1,-185) [-185|19.7] "km/h"  CGW
 SG_ OTHTTYP : 79|5@0+ (1,0) [0|31] ""  CGW
 SG_ OTHRVANG : 59|9@0- (1,0) [-256|255] "deg"  CGW
 SG_ OTHTTC : 55|12@0+ (1,0) [0|4095] "ms"  CGW
 SG_ OTHPB : 44|1@0+ (1,0) [0|1] ""  CGW
 SG_ OTHFPB : 45|1@0+ (1,0) [0|1] ""  CGW
 SG_ OTHPBA : 46|1@0+ (1,0) [0|1] ""  CGW
 SG_ OTHALM : 47|1@0+ (1,0) [0|1] ""  CGW
 SG_ OTHVH : 39|7@0+ (0.05,0) [0|6.35] "m"  CGW
 SG_ OTHVW : 31|6@0+ (0.05,0) [0|3.15] "m"  CGW

BO_ 805 CSR1G13: 8 ADU
 SG_ KZK325_MACTx : 35|28@0+ (1,0) [0|268435455] ""  CGW
 SG_ FV325_FVTx : 39|4@0+ (1,0) [0|15] ""  CGW
 SG_ ApsShiftLvrLock_D_Req : 15|2@0+ (1,0) [0|0] ""  CGW
 SG_ APPSYS2 : 0|1@0+ (1,0) [0|0] ""  CGW
 SG_ APPMD2 : 3|3@0+ (1,0) [0|0] ""  CGW

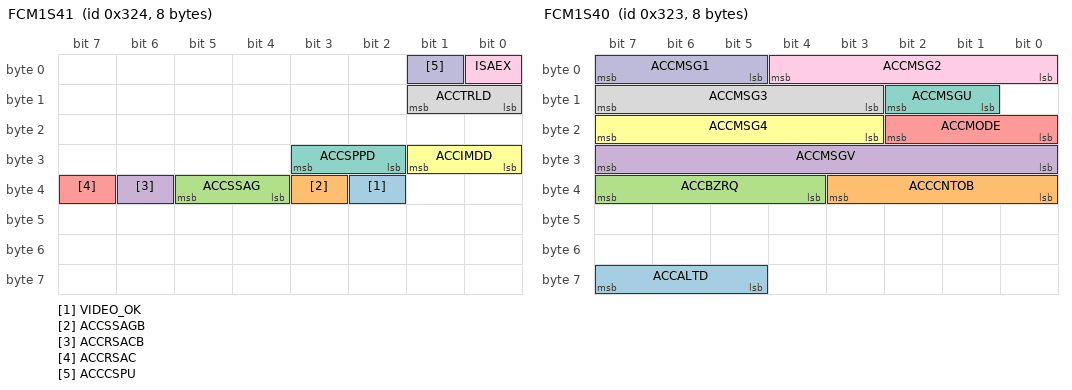
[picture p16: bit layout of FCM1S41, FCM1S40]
BO_ 804 FCM1S41: 8 ADU
 SG_ VIDEO_OK : 34|1@0+ (1,0) [0|1] ""  CGW
 SG_ ACCSSAGB : 35|1@0+ (1,0) [0|1] ""  CGW
 SG_ ACCSSAG : 37|2@0+ (1,0) [0|3] ""  CGW
 SG_ ACCRSACB : 38|1@0+ (1,0) [0|1] ""  CGW
 SG_ ACCRSAC : 39|1@0+ (1,0) [0|1] ""  CGW
 SG_ ACCIMDD : 25|2@0+ (1,0) [0|3] ""  CGW
 SG_ ACCSPPD : 27|2@0+ (1,0) [0|3] ""  CGW
 SG_ ACCTRLD : 9|2@0+ (1,0) [0|3] ""  CGW
 SG_ ISAEX : 0|1@0+ (1,0) [0|1] ""  CGW
 SG_ ACCCSPU : 1|1@0+ (1,0) [0|1] ""  CGW

BO_ 803 FCM1S40: 8 ADU
 SG_ ACCALTD : 63|3@0+ (1,0) [0|7] ""  CGW
 SG_ ACCCNTOB : 35|4@0+ (1,0) [0|15] ""  CGW
 SG_ ACCBZRQ : 39|4@0+ (1,0) [0|15] ""  CGW
 SG_ ACCMSGV : 31|8@0+ (1,0) [0|255] ""  CGW
 SG_ ACCMODE : 18|3@0+ (1,0) [0|7] ""  CGW
 SG_ ACCMSG4 : 23|5@0+ (1,0) [0|31] ""  CGW
 SG_ ACCMSGU : 10|2@0+ (1,0) [0|3] ""  CGW
 SG_ ACCMSG3 : 15|5@0+ (1,0) [0|31] ""  CGW
 SG_ ACCMSG2 : 4|5@0+ (1,0) [0|31] ""  CGW
 SG_ ACCMSG1 : 7|3@0+ (1,0) [0|7] ""  CGW

BO_ 802 FCM1S39: 8 ADU
 SG_ ACCDTST2 : 42|1@0+ (1,0) [0|1] ""  CGW
 SG_ ACCDTST1 : 44|2@0+ (1,0) [0|3] ""  CGW
 SG_ ACCDST : 47|3@0+ (1,0) [0|7] ""  CGW
 SG_ ERMMAXID : 32|1@0+ (1,0) [0|1] ""  CGW
 SG_ ACCSUST2 : 26|1@0+ (1,0) [0|1] ""  CGW
 SG_ ACCSUST1 : 28|2@0+ (1,0) [0|3] ""  CGW
 SG_ ACCSPST2 : 29|1@0+ (1,0) [0|1] ""  CGW
 SG_ ACCSPST1 : 31|2@0+ (1,0) [0|3] ""  CGW
 SG_ ACCSP : 23|8@0+ (1,0) [0|255] ""  CGW
 SG_ ACCSPEXC : 10|1@0+ (1,0) [0|1] ""  CGW
 SG_ ACCSPU : 12|2@0+ (1,0) [0|3] ""  CGW
 SG_ ISALIMID : 13|1@0+ (1,0) [0|1] ""  CGW
 SG_ ASLID : 15|2@0+ (1,0) [0|3] ""  CGW
 SG_ ACCSETID : 0|1@0+ (1,0) [0|1] ""  CGW
 SG_ ISAID : 2|2@0+ (1,0) [0|3] ""  CGW
 SG_ ACCCCSID : 4|2@0+ (1,0) [0|3] ""  CGW
 SG_ ACCID : 6|2@0+ (1,0) [0|3] ""  CGW

BO_ 800 FCM1S81: 8 ADU
 SG_ PCSDISPD : 15|2@0+ (1,0) [0|3] ""  CGW
 SG_ PCSDIDST : 3|4@0+ (1,0) [0|15] ""  CGW
 SG_ PCSDWIND : 5|1@0+ (1,0) [0|1] ""  CGW
 SG_ PCSDWON : 6|1@0+ (1,0) [0|1] ""  CGW
 SG_ PCSDWVLD : 7|1@0+ (1,0) [0|1] ""  CGW

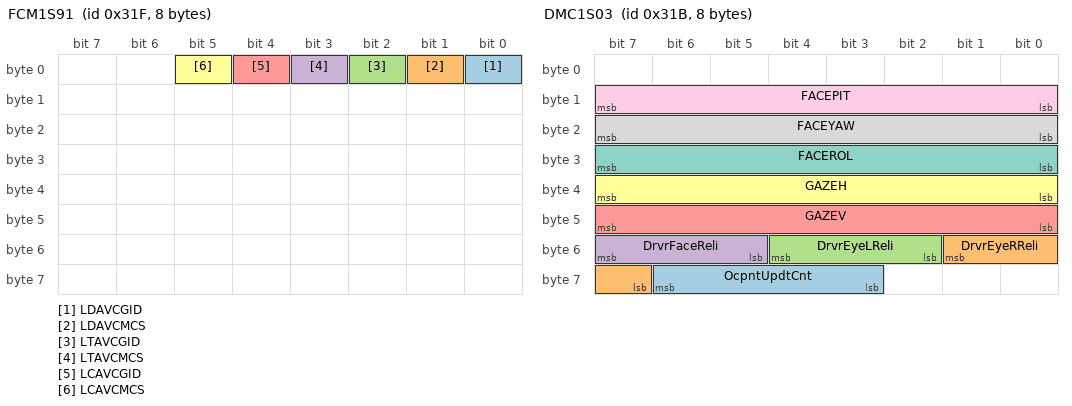
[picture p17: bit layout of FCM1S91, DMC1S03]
BO_ 799 FCM1S91: 8 ADU
 SG_ LDAVCGID : 0|1@0+ (1,0) [0|1] ""  CGW
 SG_ LDAVCMCS : 1|1@0+ (1,0) [0|1] ""  CGW
 SG_ LTAVCGID : 2|1@0+ (1,0) [0|1] ""  CGW
 SG_ LTAVCMCS : 3|1@0+ (1,0) [0|1] ""  CGW
 SG_ LCAVCGID : 4|1@0+ (1,0) [0|1] ""  CGW
 SG_ LCAVCMCS : 5|1@0+ (1,0) [0|1] ""  CGW

BO_ 798 RCP1S02: 8 ADU
 SG_ RLS_WRN : 45|2@0+ (1,0) [0|3] ""  CGW
 SG_ RRS_WRN : 47|2@0+ (1,0) [0|3] ""  CGW
 SG_ FLS_WRN : 33|2@0+ (1,0) [0|3] ""  CGW
 SG_ RLS_POS : 36|3@0+ (1,0) [0|7] ""  CGW
 SG_ RRS_POS : 39|3@0+ (1,0) [0|7] ""  CGW
 SG_ FRS_WRN : 25|2@0+ (1,0) [0|3] ""  CGW
 SG_ FLS_POS : 28|3@0+ (1,0) [0|7] ""  CGW
 SG_ FRS_POS : 31|3@0+ (1,0) [0|7] ""  CGW
 SG_ MV_RC : 17|2@0+ (1,0) [0|3] ""  CGW
 SG_ MV_FC : 19|2@0+ (1,0) [0|3] ""  CGW
 SG_ MV_RRS : 9|2@0+ (1,0) [0|3] ""  CGW
 SG_ MV_RLS : 11|2@0+ (1,0) [0|3] ""  CGW
 SG_ MV_FRS : 13|2@0+ (1,0) [0|3] ""  CGW
 SG_ MV_FLS : 15|2@0+ (1,0) [0|3] ""  CGW
 SG_ MV_RR : 1|2@0+ (1,0) [0|3] ""  CGW
 SG_ MV_RL : 3|2@0+ (1,0) [0|3] ""  CGW
 SG_ MV_FR : 5|2@0+ (1,0) [0|3] ""  CGW
 SG_ MV_FL : 7|2@0+ (1,0) [0|3] ""  CGW

BO_ 797 DMC1S05: 8 ADU
 SG_ DrvrID_12_State_OMS : 40|1@0+ (1,0) [0|0] ""  CGW
 SG_ DrvrID_11_State_OMS : 41|1@0+ (1,0) [0|0] ""  CGW
 SG_ DrvrID_10_State_OMS : 42|1@0+ (1,0) [0|0] ""  CGW
 SG_ DrvrID_9_State_OMS : 43|1@0+ (1,0) [0|0] ""  CGW
 SG_ DrvrID_8_State_OMS : 44|1@0+ (1,0) [0|0] ""  CGW
 SG_ DrvrID_7_State_OMS : 45|1@0+ (1,0) [0|0] ""  CGW
 SG_ DrvrID_6_State_OMS : 46|1@0+ (1,0) [0|0] ""  CGW
 SG_ DrvrID_5_State_OMS : 47|1@0+ (1,0) [0|0] ""  CGW
 SG_ DrvrID_4_State_OMS : 32|1@0+ (1,0) [0|0] ""  CGW
 SG_ DrvrID_3_State_OMS : 33|1@0+ (1,0) [0|0] ""  CGW
 SG_ DrvrID_2_State_OMS : 34|1@0+ (1,0) [0|0] ""  CGW
 SG_ DrvrID_1_State_OMS : 35|1@0+ (1,0) [0|0] ""  CGW
 SG_ DrvrID_Invalid_State_OMS : 36|1@0+ (1,0) [0|0] ""  CGW
 SG_ Deletion_Result_OMS : 24|4@0+ (1,0) [0|0] ""  CGW
 SG_ Deletion_State_OMS : 27|3@0+ (1,0) [0|0] ""  CGW
 SG_ Registration_Result_OMS : 31|4@0+ (1,0) [0|0] ""  CGW
 SG_ Registration_State_OMS : 18|3@0+ (1,0) [0|0] ""  CGW
 SG_ Recovery_Request_OMS : 23|5@0+ (1,0) [0|0] ""  CGW
 SG_ Identification_Score_OMS : 14|7@0+ (1,0) [0|100] "%"  CGW
 SG_ Identification_Result_OMS : 2|4@0+ (1,0) [0|0] ""  CGW
 SG_ Identification_State_OMS : 5|3@0+ (1,0) [0|0] ""  CGW
 SG_ OMS_Mode_OMS : 7|2@0+ (1,0) [0|0] ""  CGW

BO_ 796 DMC1S04: 8 ADU
 SG_ AimHeadZ : 60|1@0+ (1,0) [0|0] ""  CGW
 SG_ DrvrHeadReli : 63|3@0+ (1,0) [0|0] ""  CGW
 SG_ FACEZ : 55|8@0+ (0.01,-0.4) [-0.4|0.87] "m"  CGW
 SG_ FACEY : 47|8@0+ (0.01,-1.25) [-1.25|1.27] "m"  CGW
 SG_ FACEX : 39|8@0+ (0.01,-1.25) [-1.25|0.02] "m"  CGW

BO_ 795 DMC1S03: 8 ADU
 SG_ OcpntUpdtCnt : 62|4@0+ (1,0) [0|15] "counter"  CGW
 SG_ DrvrEyeRReli : 49|3@0+ (1,0) [0|0] ""  CGW
 SG_ DrvrEyeLReli : 52|3@0+ (1,0) [0|0] ""  CGW
 SG_ DrvrFaceReli : 55|3@0+ (1,0) [0|0] ""  CGW
 SG_ GAZEV : 47|8@0+ (1,-120) [-120|122] "deg"  CGW
 SG_ GAZEH : 39|8@0+ (1,-120) [-120|122] "deg"  CGW
 SG_ FACEROL : 31|8@0+ (1,-120) [-120|122] "deg"  CGW
 SG_ FACEYAW : 23|8@0+ (1,-120) [-120|122] "deg"  CGW
 SG_ FACEPIT : 15|8@0+ (1,-120) [-120|122] "deg"  CGW

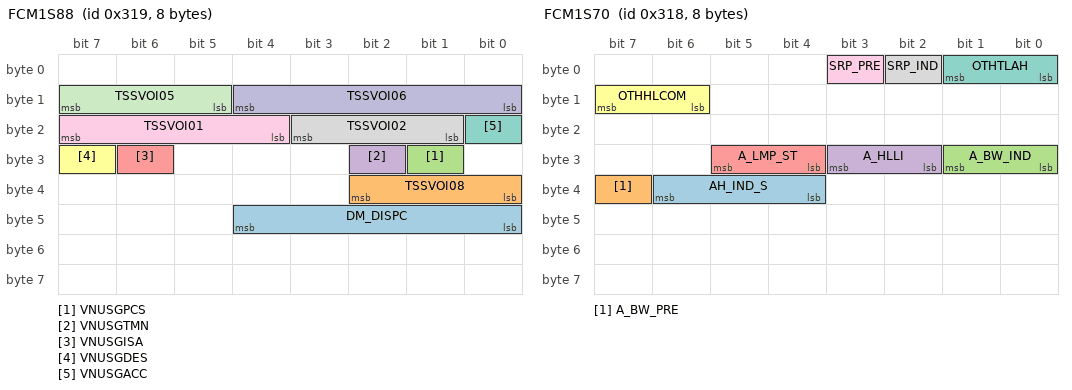
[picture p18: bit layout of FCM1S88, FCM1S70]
BO_ 793 FCM1S88: 8 ADU
 SG_ DM_DISPC : 44|5@0+ (1,0) [0|31] ""  CGW
 SG_ TSSVOI08 : 34|3@0+ (1,0) [0|7] ""  CGW
 SG_ VNUSGPCS : 25|1@0+ (1,0) [0|1] ""  CGW
 SG_ VNUSGTMN : 26|1@0+ (1,0) [0|1] ""  CGW
 SG_ VNUSGISA : 30|1@0+ (1,0) [0|1] ""  CGW
 SG_ VNUSGDES : 31|1@0+ (1,0) [0|1] ""  CGW
 SG_ VNUSGACC : 16|1@0+ (1,0) [0|1] ""  CGW
 SG_ TSSVOI02 : 19|3@0+ (1,0) [0|7] ""  CGW
 SG_ TSSVOI01 : 23|4@0+ (1,0) [0|15] ""  CGW
 SG_ TSSVOI06 : 12|5@0+ (1,0) [0|31] ""  CGW
 SG_ TSSVOI05 : 15|3@0+ (1,0) [0|7] ""  CGW

BO_ 792 FCM1S70: 8 ADU
 SG_ AH_IND_S : 38|3@0+ (1,0) [0|0] ""  CGW
 SG_ A_BW_PRE : 39|1@0+ (1,0) [0|0] ""  CGW
 SG_ A_BW_IND : 25|2@0+ (1,0) [0|0] ""  CGW
 SG_ A_HLLI : 27|2@0+ (1,0) [0|0] ""  CGW
 SG_ A_LMP_ST : 29|2@0+ (1,0) [0|0] ""  CGW
 SG_ OTHHLCOM : 15|2@0+ (1,0) [0|0] ""  CGW
 SG_ OTHTLAH : 1|2@0+ (1,0) [0|0] ""  CGW
 SG_ SRP_IND : 2|1@0+ (1,0) [0|0] ""  CGW
 SG_ SRP_PRE : 3|1@0+ (1,0) [0|0] ""  CGW

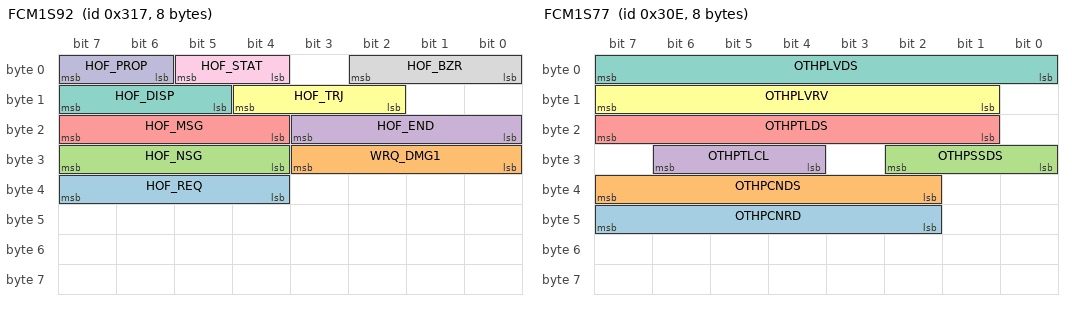
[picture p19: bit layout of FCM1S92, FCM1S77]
BO_ 791 FCM1S92: 8 ADU
 SG_ HOF_REQ : 39|4@0+ (1,0) [0|15] ""  CGW
 SG_ WRQ_DMG1 : 27|4@0+ (1,0) [0|15] ""  CGW
 SG_ HOF_NSG : 31|4@0+ (1,0) [0|15] ""  CGW
 SG_ HOF_END : 19|4@0+ (1,0) [0|15] ""  CGW
 SG_ HOF_MSG : 23|4@0+ (1,0) [0|15] ""  CGW
 SG_ HOF_TRJ : 12|3@0+ (1,0) [0|7] ""  CGW
 SG_ HOF_DISP : 15|3@0+ (1,0) [0|7] ""  CGW
 SG_ HOF_BZR : 2|3@0+ (1,0) [0|7] ""  CGW
 SG_ HOF_STAT : 5|2@0+ (1,0) [0|3] ""  CGW
 SG_ HOF_PROP : 7|2@0+ (1,0) [0|3] ""  CGW

BO_ 790 FCM1S96: 8 ADU
 SG_ EDSSLPON : 0|1@0+ (1,0) [0|1] ""  CGW
 SG_ EDSSSION : 2|2@0+ (1,0) [0|3] ""  CGW
 SG_ EDSSHRN : 4|2@0+ (1,0) [0|3] ""  CGW
 SG_ EDSSBZON : 6|2@0+ (1,0) [0|3] ""  CGW

BO_ 788 FCM1S55: 8 ADU
 SG_ OTH_OFDF : 25|2@0+ (1,0) [0|3] ""  CGW
 SG_ OTHERRC : 29|4@0+ (1,0) [0|15] ""  CGW

BO_ 787 ADU1S07: 32 ADU
 SG_ RSL_BZ_E : 52|1@0+ (1,0) [0|1] ""  CGW
 SG_ RSL_BZ_C : 53|1@0+ (1,0) [0|1] ""  CGW
 SG_ RSR_BZ_E : 54|1@0+ (1,0) [0|1] ""  CGW
 SG_ RSR_BZ_C : 55|1@0+ (1,0) [0|1] ""  CGW
 SG_ FSL_BZ_E : 40|1@0+ (1,0) [0|1] ""  CGW
 SG_ FSL_BZ_C : 41|1@0+ (1,0) [0|1] ""  CGW
 SG_ FSR_BZ_E : 42|1@0+ (1,0) [0|1] ""  CGW
 SG_ FSR_BZ_C : 43|1@0+ (1,0) [0|1] ""  CGW
 SG_ HTR_REQ : 44|1@0+ (1,0) [0|1] ""  CGW
 SG_ FRD_PLRQ : 27|1@0+ (1,0) [0|1] ""  CGW
 SG_ FSR_PLRQ : 28|1@0+ (1,0) [0|1] ""  CGW
 SG_ FSL_PLRQ : 29|1@0+ (1,0) [0|1] ""  CGW
 SG_ RSR_PLRQ : 30|1@0+ (1,0) [0|1] ""  CGW
 SG_ RSL_PLRQ : 31|1@0+ (1,0) [0|1] ""  CGW
 SG_ PLANTREQ : 2|2@0+ (1,0) [0|3] ""  CGW

BO_ 784 RCP1S04: 8 ADU
 SG_ RCPIGOF2 : 33|2@0+ (1,0) [0|3] ""  CGW
 SG_ E_CNT1B3 : 23|8@0+ (1,0) [0|255] ""  CGW
 SG_ E_CRC1B3 : 7|16@0+ (1,0) [0|65535] ""  CGW

BO_ 782 FCM1S77: 8 ADU
 SG_ OTHPCNRD : 47|6@0+ (10,0) [0|630] "m"  CGW
 SG_ OTHPCNDS : 39|6@0+ (5,0) [0|315] "m"  CGW
 SG_ OTHPSSDS : 26|3@0+ (10,30) [30|100] "m"  CGW
 SG_ OTHPTLCL : 30|3@0+ (1,0) [0|7] ""  CGW
 SG_ OTHPTLDS : 23|7@0+ (1,0) [0|127] "m"  CGW
 SG_ OTHPLVRV : 15|7@0- (1,0) [-64|63] "kph"  CGW
 SG_ OTHPLVDS : 7|8@0+ (1,0) [0|255] "m"  CGW

BO_ 780 ADU1S01: 32 ADU
 SG_ IMGOP_P : 0|1@0+ (1,0) [0|0] ""  CGW
 SG_ DRADUABN : 3|3@0+ (1,0) [0|0] ""  CGW
 SG_ DRADUTMP : 4|1@0+ (1,0) [0|0] ""  CGW
 SG_ OFKP_ADU : 5|1@0+ (1,0) [0|1] ""  CGW

BO_ 608 Information4x4: 32 CGW
 SG_ ASE_Jrk_Trg : 86|20@0+ (0.1,-52428.7) [-52428.7|52428.6] "m/s^3" Vector__XXX
 SG_ ASE_Sport_Mode_Active : 87|1@0+ (1,0) [0|0] "" Vector__XXX
 SG_ ASE_PrplWhlTot_Tq_Actl : 71|16@0+ (4,-131072) [-131072|131060] "Nm" Vector__XXX
 SG_ crnt_PT_pwr : 53|12@0+ (0.1,-100) [-100|100] "%" Vector__XXX
 SG_ Ambient_PT_GainReq : 45|8@0+ (0.5,0) [0|100] "%" Vector__XXX
 SG_ TRQ_XFER_CMD_BY_BRK_ALOWD : 46|1@0+ (1,0) [0|0] "" Vector__XXX
 SG_ IDM_SD_Evl_D_Num_260 : 35|5@0+ (1,0) [0|0] "" Vector__XXX
 SG_ TELLTALE_4X4_AUTO : 39|4@0+ (1,0) [0|0] "" Vector__XXX
 SG_ SvdFuelByHV_D_Actl_260 : 23|16@0+ (0.004,0) [0|262.14] "Micro Litter" Vector__XXX
 SG_ TRQ_XFER_CMND : 15|8@0+ (0.5,0) [0|127.5] "Percent" Vector__XXX
 SG_ LOW4 : 2|1@0+ (1,0) [0|0] ""  ADU
 SG_ AI4WD : 3|1@0+ (1,0) [0|0] ""  ADU
 SG_ MODE_4x4 : 7|4@0+ (1,0) [0|0] "" Vector__XXX

BO_ 599 HMI_Request_ADU_CatS3: 32 ADU
 SG_ HMI_Request_ADU_CatS3_MACTx : 227|28@0+ (1,0) [0|268435455] ""  CGW
 SG_ HMI_Request_ADU_CatS3_FVTx : 231|4@0+ (1,0) [0|15] ""  CGW
 SG_ HMI_Request_ADU_CatS3_No_Cs : 223|8@0+ (1,0) [0|255] ""  CGW
 SG_ HMI_Request_ADU_CatS3_No_Cnt : 211|4@0+ (1,0) [0|15] ""  CGW
 SG_ HMI_Warning_LCA1_Rq : 57|1@0+ (1,0) [0|0] ""  CGW
 SG_ HMI_Warning_DM3_Rq : 58|1@0+ (1,0) [0|0] ""  CGW
 SG_ HMI_Warning_DM2_Rq : 59|1@0+ (1,0) [0|0] ""  CGW
 SG_ HMI_Warning_DM1_Rq : 60|1@0+ (1,0) [0|0] ""  CGW
 SG_ HMI_Warning_VCUNIT1_Rq : 61|1@0+ (1,0) [0|0] ""  CGW
 SG_ HMI_Warning_OMC10_Rq : 62|1@0+ (1,0) [0|0] ""  CGW
 SG_ HMI_Warning_OMC8_Rq : 63|1@0+ (1,0) [0|0] ""  CGW
 SG_ HMI_Warning_OMC7_Rq : 48|1@0+ (1,0) [0|0] ""  CGW
 SG_ HMI_Warning_OMC6_Rq : 49|1@0+ (1,0) [0|0] ""  CGW
 SG_ HMI_Warning_OMC5_Rq : 50|1@0+ (1,0) [0|0] ""  CGW
 SG_ HMI_Warning_OMC4_Rq : 51|1@0+ (1,0) [0|0] ""  CGW
 SG_ HMI_Warning_OMC3_Rq : 52|1@0+ (1,0) [0|0] ""  CGW
 SG_ HMI_Warning_OMC2_Rq : 53|1@0+ (1,0) [0|0] ""  CGW
 SG_ HMI_Warning_OMC1_Rq : 54|1@0+ (1,0) [0|0] ""  CGW
 SG_ HMI_Warning_VMC8_Rq : 55|1@0+ (1,0) [0|0] ""  CGW
 SG_ HMI_Warning_VMC7_Rq : 40|1@0+ (1,0) [0|0] ""  CGW
 SG_ HMI_Warning_VMC6_Rq : 41|1@0+ (1,0) [0|0] ""  CGW
 SG_ HMI_Warning_VMC5_Rq : 42|1@0+ (1,0) [0|0] ""  CGW
 SG_ HMI_Warning_VMC4_Rq : 43|1@0+ (1,0) [0|0] ""  CGW
 SG_ HMI_Warning_VMC3_Rq : 44|1@0+ (1,0) [0|0] ""  CGW
 SG_ HMI_Warning_VMC2_Rq : 45|1@0+ (1,0) [0|0] ""  CGW
 SG_ HMI_Warning_VMC1_Rq : 46|1@0+ (1,0) [0|0] ""  CGW
 SG_ HMI_Warning_Sonar4_Rq : 47|1@0+ (1,0) [0|0] ""  CGW
 SG_ HMI_Warning_Sonar3_Rq : 32|1@0+ (1,0) [0|0] ""  CGW
 SG_ HMI_Warning_Sonar2_Rq : 33|1@0+ (1,0) [0|0] ""  CGW
 SG_ HMI_Warning_Sonar1_Rq : 34|1@0+ (1,0) [0|0] ""  CGW
 SG_ HMI_Warning_RSRDR6_Rq : 35|1@0+ (1,0) [0|0] ""  CGW
 SG_ HMI_Warning_RSRDR5_Rq : 36|1@0+ (1,0) [0|0] ""  CGW
 SG_ HMI_Warning_RSRDR4_Rq : 37|1@0+ (1,0) [0|0] ""  CGW
 SG_ HMI_Warning_RSRDR3_Rq : 38|1@0+ (1,0) [0|0] ""  CGW
 SG_ HMI_Warning_RSRDR2_Rq : 39|1@0+ (1,0) [0|0] ""  CGW
 SG_ HMI_Warning_RSRDR1_Rq : 24|1@0+ (1,0) [0|0] ""  CGW
 SG_ HMI_Warning_FSRDR6_Rq : 25|1@0+ (1,0) [0|0] ""  CGW
 SG_ HMI_Warning_FSRDR5_Rq : 26|1@0+ (1,0) [0|0] ""  CGW
 SG_ HMI_Warning_FSRDR4_Rq : 27|1@0+ (1,0) [0|0] ""  CGW
 SG_ HMI_Warning_FSRDR3_Rq : 28|1@0+ (1,0) [0|0] ""  CGW
 SG_ HMI_Warning_FSRDR2_Rq : 29|1@0+ (1,0) [0|0] ""  CGW
 SG_ HMI_Warning_FSRDR1_Rq : 30|1@0+ (1,0) [0|0] ""  CGW
 SG_ HMI_Warning_FRDR6_Rq : 31|1@0+ (1,0) [0|0] ""  CGW
 SG_ HMI_Warning_FRDR5_Rq : 16|1@0+ (1,0) [0|0] ""  CGW
 SG_ HMI_Warning_FRDR4_Rq : 17|1@0+ (1,0) [0|0] ""  CGW
 SG_ HMI_Warning_FRDR3_Rq : 18|1@0+ (1,0) [0|0] ""  CGW
 SG_ HMI_Warning_FRDR2_Rq : 19|1@0+ (1,0) [0|0] ""  CGW
 SG_ HMI_Warning_FRDR1_Rq : 20|1@0+ (1,0) [0|0] ""  CGW
 SG_ HMI_Warning_FSC6_Rq : 21|1@0+ (1,0) [0|0] ""  CGW
 SG_ HMI_Warning_FSC5_Rq : 22|1@0+ (1,0) [0|0] ""  CGW
 SG_ HMI_Warning_FSC4_Rq : 23|1@0+ (1,0) [0|0] ""  CGW
 SG_ HMI_Warning_FSC3_Rq : 8|1@0+ (1,0) [0|0] ""  CGW
 SG_ HMI_Warning_FSC2_Rq : 9|1@0+ (1,0) [0|0] ""  CGW
 SG_ HMI_Warning_FSC1_Rq : 10|1@0+ (1,0) [0|0] ""  CGW
 SG_ HMI_Warning_HBC1_Rq : 12|2@0+ (1,0) [0|0] ""  CGW
 SG_ HMI_Warning_ALH1_Rq : 14|2@0+ (1,0) [0|0] ""  CGW
 SG_ HMI_Warning_PASR1_Rq : 15|1@0+ (1,0) [0|0] ""  CGW
 SG_ HMI_Warning_TSR1_Rq : 1|2@0+ (1,0) [0|0] ""  CGW
 SG_ HMI_Warning_LKA1_Rq : 3|2@0+ (1,0) [0|0] ""  CGW
 SG_ HMI_Warning_ISA1_Rq : 4|1@0+ (1,0) [0|0] ""  CGW
 SG_ HMI_Warning_ASC1_Rq : 5|1@0+ (1,0) [0|0] ""  CGW
 SG_ HMI_Warning_ACC1_Rq : 7|2@0+ (1,0) [0|0] ""  CGW

BO_ 598 HMI_Request_ADU_CatS2: 32 ADU
 SG_ HMI_Request_ADU_CatS2_MACTx : 227|28@0+ (1,0) [0|268435455] ""  CGW
 SG_ HMI_Request_ADU_CatS2_FVTx : 231|4@0+ (1,0) [0|15] ""  CGW
 SG_ HMI_Request_ADU_CatS2_No_Cs : 223|8@0+ (1,0) [0|255] ""  CGW
 SG_ HMI_Request_ADU_CatS2_No_Cnt : 211|4@0+ (1,0) [0|15] ""  CGW
 SG_ HMI_Status_VCUNIT1_Rq : 133|2@0+ (1,0) [0|0] ""  CGW
 SG_ HMI_Status_OMC1_Rq : 134|1@0+ (1,0) [0|0] ""  CGW
 SG_ HMI_Status_VMC1_Rq : 135|1@0+ (1,0) [0|0] ""  CGW
 SG_ HMI_Status_Sonar1_Rq : 120|1@0+ (1,0) [0|0] ""  CGW
 SG_ HMI_Status_RSRDR3_Rq : 121|1@0+ (1,0) [0|0] ""  CGW
 SG_ HMI_Status_RSRDR2_Rq : 122|1@0+ (1,0) [0|0] ""  CGW
 SG_ HMI_Status_RSRDR1_Rq : 123|1@0+ (1,0) [0|0] ""  CGW
 SG_ HMI_Status_FSRDR3_Rq : 124|1@0+ (1,0) [0|0] ""  CGW
 SG_ HMI_Status_FSRDR2_Rq : 125|1@0+ (1,0) [0|0] ""  CGW
 SG_ HMI_Status_FSRDR1_Rq : 126|1@0+ (1,0) [0|0] ""  CGW
 SG_ HMI_Status_FRDR3_Rq : 127|1@0+ (1,0) [0|0] ""  CGW
 SG_ HMI_Status_FRDR2_Rq : 112|1@0+ (1,0) [0|0] ""  CGW
 SG_ HMI_Status_FRDR1_Rq : 113|1@0+ (1,0) [0|0] ""  CGW
 SG_ HMI_Status_FSC3_Rq : 114|1@0+ (1,0) [0|0] ""  CGW
 SG_ HMI_Status_FSC2_Rq : 115|1@0+ (1,0) [0|0] ""  CGW
 SG_ HMI_Status_FSC1_Rq : 116|1@0+ (1,0) [0|0] ""  CGW
 SG_ HMI_Status_TMN2_Rq : 117|1@0+ (1,0) [0|0] ""  CGW
 SG_ HMI_Status_TMN1_Rq : 118|1@0+ (1,0) [0|0] ""  CGW
 SG_ HMI_Status_LCA12_Rq : 119|1@0+ (1,0) [0|0] ""  CGW
 SG_ HMI_Status_LCA11_Rq : 105|2@0+ (1,0) [0|0] ""  CGW
 SG_ HMI_Status_LCA10_Rq : 106|1@0+ (1,0) [0|0] ""  CGW
 SG_ HMI_Status_LCA9_Rq : 107|1@0+ (1,0) [0|0] ""  CGW
 SG_ HMI_Status_LCA8_Rq : 108|1@0+ (1,0) [0|0] ""  CGW
 SG_ HMI_Status_LCA7_Rq : 109|1@0+ (1,0) [0|0] ""  CGW
 SG_ HMI_Status_LCA6_Rq : 110|1@0+ (1,0) [0|0] ""  CGW
 SG_ HMI_Status_LCA5_Rq : 111|1@0+ (1,0) [0|0] ""  CGW
 SG_ HMI_Status_LCA4_Rq : 96|1@0+ (1,0) [0|0] ""  CGW
 SG_ HMI_Status_LCA3_Rq : 97|1@0+ (1,0) [0|0] ""  CGW
 SG_ HMI_Status_LCA2_Rq : 98|1@0+ (1,0) [0|0] ""  CGW
 SG_ HMI_Status_LCA1_Rq : 103|5@0+ (1,0) [0|0] ""  CGW
 SG_ HMI_Status_HoF11_Rq : 88|1@0+ (1,0) [0|0] ""  CGW
 SG_ HMI_Status_HoF10_Rq : 90|2@0+ (1,0) [0|0] ""  CGW
 SG_ HMI_Status_HoF9_Rq : 91|1@0+ (1,0) [0|0] ""  CGW
 SG_ HMI_Status_HoF8_Rq : 92|1@0+ (1,0) [0|0] ""  CGW
 SG_ HMI_Status_HoF7_Rq : 93|1@0+ (1,0) [0|0] ""  CGW
 SG_ HMI_Status_HoF6_Rq : 94|1@0+ (1,0) [0|0] ""  CGW
 SG_ HMI_Status_HoF5_Rq : 95|1@0+ (1,0) [0|0] ""  CGW
 SG_ HMI_Status_HoF4_Rq : 80|1@0+ (1,0) [0|0] ""  CGW
 SG_ HMI_Status_HoF3_Rq : 81|1@0+ (1,0) [0|0] ""  CGW
 SG_ HMI_Status_HoF2_Rq : 86|5@0+ (1,0) [0|0] ""  CGW
 SG_ HMI_Status_HoF1_Rq : 87|1@0+ (1,0) [0|0] ""  CGW
 SG_ HMI_Status_AESESA1_Rq : 74|3@0+ (1,0) [0|0] ""  CGW
 SG_ HMI_Status_PDA6_Rq : 75|1@0+ (1,0) [0|0] ""  CGW
 SG_ HMI_Status_PDA5_Rq : 76|1@0+ (1,0) [0|0] ""  CGW
 SG_ HMI_Status_PDA2_Rq : 79|2@0+ (1,0) [0|0] ""  CGW
 SG_ HMI_Status_PDA1_Rq : 66|3@0+ (1,0) [0|0] ""  CGW
 SG_ HMI_Status_REDKEY2_Rq : 67|1@0+ (1,0) [0|0] ""  CGW
 SG_ HMI_Status_REDKEY1_Rq : 68|1@0+ (1,0) [0|0] ""  CGW
 SG_ HMI_Status_EDA3_Rq : 69|1@0+ (1,0) [0|0] ""  CGW
 SG_ HMI_Status_EDA2_Rq : 70|1@0+ (1,0) [0|0] ""  CGW
 SG_ HMI_Status_EDA1_Rq : 58|4@0+ (1,0) [0|0] ""  CGW
 SG_ HMI_Status_APSRPC1_Rq : 61|3@0+ (1,0) [0|0] ""  CGW
 SG_ HMI_Status_DM18_Rq : 62|1@0+ (1,0) [0|0] ""  CGW
 SG_ HMI_Status_DM14_Rq : 50|1@0+ (1,0) [0|0] ""  CGW
 SG_ HMI_Status_DM13_Rq : 51|1@0+ (1,0) [0|0] ""  CGW
 SG_ HMI_Status_DM12_Rq : 52|1@0+ (1,0) [0|0] ""  CGW
 SG_ HMI_Status_DM11_Rq : 53|1@0+ (1,0) [0|0] ""  CGW
 SG_ HMI_Status_DM10_Rq : 54|1@0+ (1,0) [0|0] ""  CGW
 SG_ HMI_Status_DM9_Rq : 55|1@0+ (1,0) [0|0] ""  CGW
 SG_ HMI_Status_DM8_Rq : 41|2@0+ (1,0) [0|0] ""  CGW
 SG_ HMI_Status_DM7_Rq : 42|1@0+ (1,0) [0|0] ""  CGW
 SG_ HMI_Status_DM6_Rq : 43|1@0+ (1,0) [0|0] ""  CGW
 SG_ HMI_Status_DM5_Rq : 44|1@0+ (1,0) [0|0] ""  CGW
 SG_ HMI_Status_DM4_Rq : 45|1@0+ (1,0) [0|0] ""  CGW
 SG_ HMI_Status_DM3_Rq : 46|1@0+ (1,0) [0|0] ""  CGW
 SG_ HMI_Status_DM2_Rq : 47|1@0+ (1,0) [0|0] ""  CGW
 SG_ HMI_Status_DM1_Rq : 34|3@0+ (1,0) [0|0] ""  CGW
 SG_ HMI_Status_PASFR8_Rq : 37|3@0+ (1,0) [0|0] ""  CGW
 SG_ HMI_Status_PASFR7_Rq : 24|3@0+ (1,0) [0|0] ""  CGW
 SG_ HMI_Status_PASFR6_Rq : 27|3@0+ (1,0) [0|0] ""  CGW
 SG_ HMI_Status_PASFR5_Rq : 30|3@0+ (1,0) [0|0] ""  CGW
 SG_ HMI_Status_PASFR4_Rq : 17|3@0+ (1,0) [0|0] ""  CGW
 SG_ HMI_Status_PASFR3_Rq : 20|3@0+ (1,0) [0|0] ""  CGW
 SG_ HMI_Status_PASFR2_Rq : 23|3@0+ (1,0) [0|0] ""  CGW
 SG_ HMI_Status_PASFR1_Rq : 10|3@0+ (1,0) [0|0] ""  CGW
 SG_ HMI_Status_PASR4_Rq : 13|3@0+ (1,0) [0|0] ""  CGW
 SG_ HMI_Status_PASR3_Rq : 0|3@0+ (1,0) [0|0] ""  CGW
 SG_ HMI_Status_PASR2_Rq : 3|3@0+ (1,0) [0|0] ""  CGW
 SG_ HMI_Status_PASR1_Rq : 6|3@0+ (1,0) [0|0] ""  CGW
 SG_ HMI_Status_PAS1_Rq : 7|1@0+ (1,0) [0|0] ""  CGW

BA_DEF_REL_ BU_SG_REL_  "SC_Verification" ENUM  "No","Yes";
BA_DEF_ BO_  "SCP_FreshnessValueTxLength" INT 0 512;
BA_DEF_ BO_  "SCP_FreshnessValueLength" INT 0 512;
BA_DEF_ BO_  "SCP_DataId" INT 0 65535;
BA_DEF_ BO_  "SCP_AuthInfoTxLength" INT 0 512;
BA_DEF_ BO_  "SC_Message" ENUM  "No","Yes";
BA_DEF_ BO_  "CANFD_BRS" ENUM  "0","1";
BA_DEF_ BO_  "VFrameFormat" ENUM  "StandardCAN","ExtendedCAN","reserved","reserved","reserved","reserved","reserved","reserved","reserved","reserved","reserved","reserved","reserved","reserved","StandardCAN_FD","ExtendedCAN_FD";
BA_DEF_ BO_  "DiagRequest" ENUM  "No","Yes";
BA_DEF_ BO_  "DiagResponse" ENUM  "No","Yes";
BA_DEF_ BO_  "DiagState" ENUM  "No","Yes";
BA_DEF_ BO_  "DiagConnection" INT 0 65535;
BA_DEF_ BO_  "GenMsgCycleTime" INT 0 10000;
BA_DEF_ BO_  "GenMsgCycleTimeFast" INT 0 100000;
BA_DEF_ BO_  "GenMsgDelayTime" INT 0 1000;
BA_DEF_ BO_  "GenMsgILSupport" ENUM  "No","Yes";
BA_DEF_ BO_  "GenMsgNrOfRepetition" INT 0 100;
BA_DEF_ BO_  "GenMsgSendType" ENUM  "FixedPeriodic","Event","EnabledPeriodic","NotUsed","NotUsed","EventPeriodic","NotUsed","NotUsed","NoMsgSendType";
BA_DEF_ SG_  "GenSigSendType" ENUM  "Cyclic","OnWrite","OnWriteWithRepetition","OnChange","OnChangeWithRepetition","IfActive","IfActiveWithRepetition","NoSigSendType";
BA_DEF_ SG_  "GenSigStartValue" FLOAT 0 1E+011;
BA_DEF_ SG_  "GenSigTimeoutTime_CGW" INT 0 100000;
BA_DEF_ SG_  "GenSigTimeoutTime_ADU" INT 0 100000;
BA_DEF_ BO_  "NetworkInitialization" ENUM  "No","Yes";
BA_DEF_ SG_  "GenSigEnvVarType" ENUM  "int","float","undef";
BA_DEF_ SG_  "NWM-WakeupAllowed" ENUM  "No","Yes";
BA_DEF_ BO_  "NmAsrMessage" ENUM  "No","Yes";
BA_DEF_ BO_  "GenMsgTxConditionAccOn" ENUM  "No","Yes";
BA_DEF_ BO_  "GenMsgTxConditionIg1On" ENUM  "No","Yes";
BA_DEF_ BO_  "GenMsgTxConditionPlusBOn" ENUM  "No","Yes";
BA_DEF_ SG_  "GenSigInvalidValue" INT 0 10000000000;
BA_DEF_ BO_  "CANoeMsgTxTimingIgnitionSwitched" ENUM  "AccOn","IG1On","IG2On","NoMsgTxTiming";
BA_DEF_DEF_REL_ "SC_Verification" "Yes";
BA_DEF_DEF_  "SCP_FreshnessValueTxLength" 4;
BA_DEF_DEF_  "SCP_FreshnessValueLength" 48;
BA_DEF_DEF_  "SCP_DataId" 0;
BA_DEF_DEF_  "SCP_AuthInfoTxLength" 28;
BA_DEF_DEF_  "SC_Message" "No";
BA_DEF_DEF_  "CANFD_BRS" "1";
BA_DEF_DEF_  "VFrameFormat" "ExtendedCAN_FD";
BA_DEF_DEF_  "DiagRequest" "No";
BA_DEF_DEF_  "DiagResponse" "No";
BA_DEF_DEF_  "DiagState" "No";
BA_DEF_DEF_  "DiagConnection" 0;
BA_DEF_DEF_  "GenMsgCycleTime" 0;
BA_DEF_DEF_  "GenMsgCycleTimeFast" 0;
BA_DEF_DEF_  "GenMsgDelayTime" 20;
BA_DEF_DEF_  "GenMsgILSupport" "Yes";
BA_DEF_DEF_  "GenMsgNrOfRepetition" 0;
BA_DEF_DEF_  "GenMsgSendType" "NoMsgSendType";
BA_DEF_DEF_  "GenSigSendType" "NoSigSendType";
BA_DEF_DEF_  "GenSigStartValue" 0;
BA_DEF_DEF_  "GenSigTimeoutTime_CGW" 5000;
BA_DEF_DEF_  "GenSigTimeoutTime_ADU" 5000;
BA_DEF_DEF_  "NetworkInitialization" "No";
BA_DEF_DEF_  "GenSigEnvVarType" "undef";
BA_DEF_DEF_  "NWM-WakeupAllowed" "No";
BA_DEF_DEF_  "NmAsrMessage" "No";
BA_DEF_DEF_  "GenMsgTxConditionAccOn" "No";
BA_DEF_DEF_  "GenMsgTxConditionIg1On" "No";
BA_DEF_DEF_  "GenMsgTxConditionPlusBOn" "No";
BA_DEF_DEF_  "GenSigInvalidValue" 0;
BA_DEF_DEF_  "CANoeMsgTxTimingIgnitionSwitched" "NoMsgTxTiming";
BA_ "GenMsgSendType" BO_ 1025 0;
BA_ "GenMsgCycleTime" BO_ 1025 200;
BA_ "NetworkInitialization" BO_ 1025 1;
BA_ "VFrameFormat" BO_ 1025 14;
BA_ "GenMsgSendType" BO_ 1010 5;
BA_ "GenMsgCycleTime" BO_ 1010 200;
BA_ "NetworkInitialization" BO_ 1010 1;
BA_ "VFrameFormat" BO_ 1010 14;
BA_ "GenMsgSendType" BO_ 994 0;
BA_ "GenMsgCycleTime" BO_ 994 200;
BA_ "VFrameFormat" BO_ 994 14;
BA_ "GenMsgSendType" BO_ 988 0;
BA_ "GenMsgCycleTime" BO_ 988 300;
BA_ "VFrameFormat" BO_ 988 14;
BA_ "GenMsgSendType" BO_ 985 5;
BA_ "GenMsgCycleTime" BO_ 985 300;
BA_ "VFrameFormat" BO_ 985 14;
BA_ "GenMsgSendType" BO_ 977 5;
BA_ "GenMsgCycleTime" BO_ 977 500;
BA_ "VFrameFormat" BO_ 977 14;
BA_ "GenMsgSendType" BO_ 975 5;
BA_ "GenMsgCycleTime" BO_ 975 1000;
BA_ "VFrameFormat" BO_ 975 14;
BA_ "GenMsgSendType" BO_ 974 5;
BA_ "GenMsgCycleTime" BO_ 974 1008;
BA_ "VFrameFormat" BO_ 974 14;
BA_ "GenMsgSendType" BO_ 973 5;
BA_ "GenMsgCycleTime" BO_ 973 1000;
BA_ "VFrameFormat" BO_ 973 14;
BA_ "GenMsgSendType" BO_ 972 5;
BA_ "GenMsgCycleTime" BO_ 972 1000;
BA_ "VFrameFormat" BO_ 972 14;
BA_ "GenMsgSendType" BO_ 971 5;
BA_ "GenMsgCycleTime" BO_ 971 1000;
BA_ "VFrameFormat" BO_ 971 14;
BA_ "GenMsgSendType" BO_ 961 5;
BA_ "GenMsgCycleTime" BO_ 961 200;
BA_ "VFrameFormat" BO_ 961 14;
BA_ "GenMsgSendType" BO_ 960 5;
BA_ "GenMsgCycleTime" BO_ 960 200;
BA_ "VFrameFormat" BO_ 960 14;
BA_ "GenMsgSendType" BO_ 923 5;
BA_ "GenMsgCycleTime" BO_ 923 1000;
BA_ "VFrameFormat" BO_ 923 14;
BA_ "GenMsgSendType" BO_ 920 5;
BA_ "GenMsgCycleTime" BO_ 920 1000;
BA_ "VFrameFormat" BO_ 920 14;
BA_ "GenMsgSendType" BO_ 919 5;
BA_ "GenMsgCycleTime" BO_ 919 3000;
BA_ "VFrameFormat" BO_ 919 14;
BA_ "GenMsgSendType" BO_ 918 5;
BA_ "GenMsgCycleTime" BO_ 918 1000;
BA_ "VFrameFormat" BO_ 918 14;
BA_ "GenMsgSendType" BO_ 910 0;
BA_ "GenMsgCycleTime" BO_ 910 500;
BA_ "NetworkInitialization" BO_ 910 1;
BA_ "VFrameFormat" BO_ 910 14;
BA_ "GenMsgSendType" BO_ 909 0;
BA_ "GenMsgCycleTime" BO_ 909 500;
BA_ "NetworkInitialization" BO_ 909 1;
BA_ "VFrameFormat" BO_ 909 14;
BA_ "GenMsgSendType" BO_ 908 0;
BA_ "GenMsgCycleTime" BO_ 908 500;
BA_ "NetworkInitialization" BO_ 908 1;
BA_ "VFrameFormat" BO_ 908 14;
BA_ "GenMsgSendType" BO_ 907 0;
BA_ "GenMsgCycleTime" BO_ 907 500;
BA_ "NetworkInitialization" BO_ 907 1;
BA_ "VFrameFormat" BO_ 907 14;
BA_ "GenMsgSendType" BO_ 906 0;
BA_ "GenMsgCycleTime" BO_ 906 500;
BA_ "NetworkInitialization" BO_ 906 1;
BA_ "VFrameFormat" BO_ 906 14;
BA_ "GenMsgSendType" BO_ 905 0;
BA_ "GenMsgCycleTime" BO_ 905 500;
BA_ "NetworkInitialization" BO_ 905 1;
BA_ "VFrameFormat" BO_ 905 14;
BA_ "GenMsgSendType" BO_ 904 0;
BA_ "GenMsgCycleTime" BO_ 904 500;
BA_ "NetworkInitialization" BO_ 904 1;
BA_ "VFrameFormat" BO_ 904 14;
BA_ "GenMsgSendType" BO_ 903 0;
BA_ "GenMsgCycleTime" BO_ 903 500;
BA_ "NetworkInitialization" BO_ 903 1;
BA_ "VFrameFormat" BO_ 903 14;
BA_ "GenMsgSendType" BO_ 902 0;
BA_ "GenMsgCycleTime" BO_ 902 500;
BA_ "NetworkInitialization" BO_ 902 1;
BA_ "VFrameFormat" BO_ 902 14;
BA_ "GenMsgSendType" BO_ 901 0;
BA_ "GenMsgCycleTime" BO_ 901 500;
BA_ "NetworkInitialization" BO_ 901 1;
BA_ "VFrameFormat" BO_ 901 14;
BA_ "GenMsgSendType" BO_ 900 0;
BA_ "GenMsgCycleTime" BO_ 900 500;
BA_ "NetworkInitialization" BO_ 900 1;
BA_ "VFrameFormat" BO_ 900 14;
BA_ "GenMsgSendType" BO_ 899 0;
BA_ "GenMsgCycleTime" BO_ 899 500;
BA_ "NetworkInitialization" BO_ 899 1;
BA_ "VFrameFormat" BO_ 899 14;
BA_ "GenMsgSendType" BO_ 898 0;
BA_ "GenMsgCycleTime" BO_ 898 500;
BA_ "NetworkInitialization" BO_ 898 1;
BA_ "VFrameFormat" BO_ 898 14;
BA_ "GenMsgSendType" BO_ 897 0;
BA_ "GenMsgCycleTime" BO_ 897 500;
BA_ "NetworkInitialization" BO_ 897 1;
BA_ "VFrameFormat" BO_ 897 14;
BA_ "GenMsgSendType" BO_ 896 0;
BA_ "GenMsgCycleTime" BO_ 896 500;
BA_ "NetworkInitialization" BO_ 896 1;
BA_ "VFrameFormat" BO_ 896 14;
BA_ "GenMsgSendType" BO_ 894 5;
BA_ "GenMsgCycleTime" BO_ 894 1000;
BA_ "VFrameFormat" BO_ 894 14;
BA_ "GenMsgSendType" BO_ 893 5;
BA_ "GenMsgCycleTime" BO_ 893 200;
BA_ "VFrameFormat" BO_ 893 14;
BA_ "GenMsgSendType" BO_ 892 5;
BA_ "GenMsgCycleTime" BO_ 892 1000;
BA_ "VFrameFormat" BO_ 892 14;
BA_ "GenMsgSendType" BO_ 857 5;
BA_ "GenMsgCycleTime" BO_ 857 1000;
BA_ "VFrameFormat" BO_ 857 14;
BA_ "GenMsgSendType" BO_ 855 5;
BA_ "GenMsgCycleTime" BO_ 855 1000;
BA_ "VFrameFormat" BO_ 855 14;
BA_ "GenMsgSendType" BO_ 854 0;
BA_ "GenMsgCycleTime" BO_ 854 200;
BA_ "VFrameFormat" BO_ 854 14;
BA_ "GenMsgSendType" BO_ 851 0;
BA_ "GenMsgCycleTime" BO_ 851 200;
BA_ "VFrameFormat" BO_ 851 14;
BA_ "GenMsgSendType" BO_ 850 0;
BA_ "GenMsgCycleTime" BO_ 850 200;
BA_ "VFrameFormat" BO_ 850 14;
BA_ "GenMsgSendType" BO_ 849 0;
BA_ "GenMsgCycleTime" BO_ 849 200;
BA_ "VFrameFormat" BO_ 849 14;
BA_ "GenMsgSendType" BO_ 848 5;
BA_ "GenMsgCycleTime" BO_ 848 100;
BA_ "VFrameFormat" BO_ 848 14;
BA_ "GenMsgSendType" BO_ 847 5;
BA_ "GenMsgCycleTime" BO_ 847 1000;
BA_ "VFrameFormat" BO_ 847 14;
BA_ "GenMsgSendType" BO_ 846 5;
BA_ "GenMsgCycleTime" BO_ 846 1000;
BA_ "VFrameFormat" BO_ 846 14;
BA_ "GenMsgSendType" BO_ 845 5;
BA_ "GenMsgCycleTime" BO_ 845 1000;
BA_ "VFrameFormat" BO_ 845 14;
BA_ "GenMsgSendType" BO_ 844 5;
BA_ "GenMsgCycleTime" BO_ 844 1000;
BA_ "VFrameFormat" BO_ 844 14;
BA_ "GenMsgSendType" BO_ 843 5;
BA_ "GenMsgCycleTime" BO_ 843 1000;
BA_ "VFrameFormat" BO_ 843 14;
BA_ "GenMsgSendType" BO_ 842 5;
BA_ "GenMsgCycleTime" BO_ 842 1000;
BA_ "VFrameFormat" BO_ 842 14;
BA_ "GenMsgSendType" BO_ 841 5;
BA_ "GenMsgCycleTime" BO_ 841 1000;
BA_ "VFrameFormat" BO_ 841 14;
BA_ "GenMsgSendType" BO_ 840 5;
BA_ "GenMsgCycleTime" BO_ 840 1000;
BA_ "VFrameFormat" BO_ 840 14;
BA_ "GenMsgSendType" BO_ 839 5;
BA_ "GenMsgCycleTime" BO_ 839 1000;
BA_ "VFrameFormat" BO_ 839 14;
BA_ "GenMsgSendType" BO_ 838 5;
BA_ "GenMsgCycleTime" BO_ 838 1000;
BA_ "VFrameFormat" BO_ 838 14;
BA_ "GenMsgSendType" BO_ 837 5;
BA_ "GenMsgCycleTime" BO_ 837 1000;
BA_ "VFrameFormat" BO_ 837 14;
BA_ "GenMsgSendType" BO_ 832 5;
BA_ "GenMsgCycleTime" BO_ 832 100;
BA_ "VFrameFormat" BO_ 832 14;
BA_ "GenMsgSendType" BO_ 807 5;
BA_ "GenMsgCycleTime" BO_ 807 1000;
BA_ "VFrameFormat" BO_ 807 14;
BA_ "GenMsgSendType" BO_ 806 5;
BA_ "GenMsgCycleTime" BO_ 806 1000;
BA_ "VFrameFormat" BO_ 806 14;
BA_ "GenMsgSendType" BO_ 805 5;
BA_ "SC_Message" BO_ 805 1;
BA_ "SCP_DataId" BO_ 805 805;
BA_ "GenMsgCycleTime" BO_ 805 1000;
BA_ "VFrameFormat" BO_ 805 14;
BA_ "GenMsgSendType" BO_ 804 5;
BA_ "GenMsgCycleTime" BO_ 804 1000;
BA_ "VFrameFormat" BO_ 804 14;
BA_ "GenMsgSendType" BO_ 803 5;
BA_ "GenMsgCycleTime" BO_ 803 1000;
BA_ "VFrameFormat" BO_ 803 14;
BA_ "GenMsgSendType" BO_ 802 5;
BA_ "GenMsgCycleTime" BO_ 802 1000;
BA_ "VFrameFormat" BO_ 802 14;
BA_ "GenMsgSendType" BO_ 800 5;
BA_ "GenMsgCycleTime" BO_ 800 1000;
BA_ "VFrameFormat" BO_ 800 14;
BA_ "GenMsgSendType" BO_ 799 5;
BA_ "GenMsgCycleTime" BO_ 799 1000;
BA_ "VFrameFormat" BO_ 799 14;
BA_ "GenMsgSendType" BO_ 798 5;
BA_ "GenMsgCycleTime" BO_ 798 1000;
BA_ "VFrameFormat" BO_ 798 14;
BA_ "GenMsgSendType" BO_ 797 0;
BA_ "GenMsgCycleTime" BO_ 797 100;
BA_ "VFrameFormat" BO_ 797 14;
BA_ "GenMsgSendType" BO_ 796 0;
BA_ "GenMsgCycleTime" BO_ 796 100;
BA_ "VFrameFormat" BO_ 796 14;
BA_ "GenMsgSendType" BO_ 795 0;
BA_ "GenMsgCycleTime" BO_ 795 100;
BA_ "VFrameFormat" BO_ 795 14;
BA_ "GenMsgSendType" BO_ 793 5;
BA_ "GenMsgCycleTime" BO_ 793 1000;
BA_ "VFrameFormat" BO_ 793 14;
BA_ "GenMsgSendType" BO_ 792 5;
BA_ "GenMsgCycleTime" BO_ 792 1000;
BA_ "VFrameFormat" BO_ 792 14;
BA_ "GenMsgSendType" BO_ 791 5;
BA_ "GenMsgCycleTime" BO_ 791 1000;
BA_ "VFrameFormat" BO_ 791 14;
BA_ "GenMsgSendType" BO_ 790 5;
BA_ "GenMsgCycleTime" BO_ 790 1000;
BA_ "VFrameFormat" BO_ 790 14;
BA_ "GenMsgSendType" BO_ 788 0;
BA_ "GenMsgCycleTime" BO_ 788 100;
BA_ "VFrameFormat" BO_ 788 14;
BA_ "GenMsgSendType" BO_ 787 5;
BA_ "GenMsgCycleTime" BO_ 787 1000;
BA_ "VFrameFormat" BO_ 787 14;
BA_ "GenMsgSendType" BO_ 784 0;
BA_ "GenMsgCycleTime" BO_ 784 200;
BA_ "VFrameFormat" BO_ 784 14;
BA_ "GenMsgSendType" BO_ 782 0;
BA_ "GenMsgCycleTime" BO_ 782 200;
BA_ "VFrameFormat" BO_ 782 14;
BA_ "GenMsgSendType" BO_ 780 5;
BA_ "GenMsgCycleTime" BO_ 780 1000;
BA_ "VFrameFormat" BO_ 780 14;
BA_ "GenMsgSendType" BO_ 608 0;
BA_ "GenMsgCycleTime" BO_ 608 20;
BA_ "GenMsgDelayTime" BO_ 608 0;
BA_ "NetworkInitialization" BO_ 608 1;
BA_ "VFrameFormat" BO_ 608 14;
BA_ "GenMsgSendType" BO_ 599 5;
BA_ "GenMsgCycleTime" BO_ 599 100;
BA_ "VFrameFormat" BO_ 599 14;
BA_ "GenMsgSendType" BO_ 598 5;
BA_ "GenMsgCycleTime" BO_ 598 100;
BA_ "VFrameFormat" BO_ 598 14;
BA_ "GenMsgTxConditionIg1On" BO_ 975 1;
BA_ "GenMsgTxConditionIg1On" BO_ 974 1;
BA_ "GenMsgTxConditionIg1On" BO_ 973 1;
BA_ "GenMsgTxConditionIg1On" BO_ 972 1;
BA_ "GenMsgTxConditionIg1On" BO_ 971 1;
BA_ "GenMsgTxConditionIg1On" BO_ 920 1;
BA_ "GenMsgTxConditionIg1On" BO_ 919 1;
BA_ "GenMsgTxConditionIg1On" BO_ 910 1;
BA_ "GenMsgTxConditionIg1On" BO_ 909 1;
BA_ "GenMsgTxConditionIg1On" BO_ 908 1;
BA_ "GenMsgTxConditionIg1On" BO_ 907 1;
BA_ "GenMsgTxConditionIg1On" BO_ 906 1;
BA_ "GenMsgTxConditionIg1On" BO_ 905 1;
BA_ "GenMsgTxConditionIg1On" BO_ 904 1;
BA_ "GenMsgTxConditionIg1On" BO_ 903 1;
BA_ "GenMsgTxConditionIg1On" BO_ 902 1;
BA_ "GenMsgTxConditionIg1On" BO_ 901 1;
BA_ "GenMsgTxConditionIg1On" BO_ 900 1;
BA_ "GenMsgTxConditionIg1On" BO_ 899 1;
BA_ "GenMsgTxConditionIg1On" BO_ 898 1;
BA_ "GenMsgTxConditionIg1On" BO_ 897 1;
BA_ "GenMsgTxConditionIg1On" BO_ 896 1;
BA_ "GenMsgTxConditionIg1On" BO_ 894 1;
BA_ "GenMsgTxConditionIg1On" BO_ 893 1;
BA_ "GenMsgTxConditionIg1On" BO_ 892 1;
BA_ "GenMsgTxConditionIg1On" BO_ 857 1;
BA_ "GenMsgTxConditionIg1On" BO_ 854 1;
BA_ "GenMsgTxConditionIg1On" BO_ 851 1;
BA_ "GenMsgTxConditionIg1On" BO_ 850 1;
BA_ "GenMsgTxConditionIg1On" BO_ 849 1;
BA_ "GenMsgTxConditionIg1On" BO_ 847 1;
BA_ "GenMsgTxConditionIg1On" BO_ 845 1;
BA_ "GenMsgTxConditionIg1On" BO_ 844 1;
BA_ "GenMsgTxConditionIg1On" BO_ 843 1;
BA_ "GenMsgTxConditionIg1On" BO_ 842 1;
BA_ "GenMsgTxConditionIg1On" BO_ 841 1;
BA_ "GenMsgTxConditionIg1On" BO_ 840 1;
BA_ "GenMsgTxConditionIg1On" BO_ 839 1;
BA_ "GenMsgTxConditionIg1On" BO_ 838 1;
BA_ "GenMsgTxConditionIg1On" BO_ 837 1;
BA_ "GenMsgTxConditionIg1On" BO_ 832 1;
BA_ "GenMsgTxConditionIg1On" BO_ 807 1;
BA_ "GenMsgTxConditionIg1On" BO_ 806 1;
BA_ "GenMsgTxConditionIg1On" BO_ 805 1;
BA_ "GenMsgTxConditionIg1On" BO_ 804 1;
BA_ "GenMsgTxConditionIg1On" BO_ 803 1;
BA_ "GenMsgTxConditionIg1On" BO_ 802 1;
BA_ "GenMsgTxConditionIg1On" BO_ 800 1;
BA_ "GenMsgTxConditionIg1On" BO_ 799 1;
BA_ "GenMsgTxConditionIg1On" BO_ 798 1;
BA_ "GenMsgTxConditionIg1On" BO_ 793 1;
BA_ "GenMsgTxConditionIg1On" BO_ 792 1;
BA_ "GenMsgTxConditionIg1On" BO_ 791 1;
BA_ "GenMsgTxConditionIg1On" BO_ 790 1;
BA_ "GenMsgTxConditionIg1On" BO_ 788 1;
BA_ "GenMsgTxConditionIg1On" BO_ 787 1;
BA_ "GenMsgTxConditionIg1On" BO_ 784 1;
BA_ "GenMsgTxConditionIg1On" BO_ 782 1;
BA_ "GenMsgTxConditionIg1On" BO_ 780 1;
BA_ "GenMsgTxConditionIg1On" BO_ 608 1;
BA_ "GenMsgTxConditionIg1On" BO_ 599 1;
BA_ "GenMsgTxConditionIg1On" BO_ 598 1;
BA_ "GenMsgTxConditionPlusBOn" BO_ 1025 1;
BA_ "GenMsgTxConditionPlusBOn" BO_ 1010 1;
BA_ "GenMsgTxConditionPlusBOn" BO_ 994 1;
BA_ "GenMsgTxConditionPlusBOn" BO_ 988 1;
BA_ "GenMsgTxConditionPlusBOn" BO_ 985 1;
BA_ "GenMsgTxConditionPlusBOn" BO_ 977 1;
BA_ "GenMsgTxConditionPlusBOn" BO_ 961 1;
BA_ "GenMsgTxConditionPlusBOn" BO_ 960 1;
BA_ "GenMsgTxConditionPlusBOn" BO_ 923 1;
BA_ "GenMsgTxConditionPlusBOn" BO_ 918 1;
BA_ "GenMsgTxConditionPlusBOn" BO_ 855 1;
BA_ "GenMsgTxConditionPlusBOn" BO_ 848 1;
BA_ "GenMsgTxConditionPlusBOn" BO_ 846 1;
BA_ "GenMsgTxConditionPlusBOn" BO_ 797 1;
BA_ "GenMsgTxConditionPlusBOn" BO_ 796 1;
BA_ "GenMsgTxConditionPlusBOn" BO_ 795 1;
BA_ "GenSigInvalidValue" SG_ 1025 BattTemp 511;
BA_ "GenSigStartValue" SG_ 1025 Charging_State_D_Actl 14;
BA_ "GenSigInvalidValue" SG_ 1025 Charging_State_D_Actl 15;
BA_ "GenSigStartValue" SG_ 1025 Charger_Connector_Fit_State 14;
BA_ "GenSigInvalidValue" SG_ 1025 Charger_Connector_Fit_State 15;
BA_ "GenSigStartValue" SG_ 1025 SOC_LowerLimit_HysL 254;
BA_ "GenSigInvalidValue" SG_ 1025 SOC_LowerLimit_HysL 255;
BA_ "GenSigStartValue" SG_ 1025 SOC_LowerLimit_HysH 254;
BA_ "GenSigInvalidValue" SG_ 1025 SOC_LowerLimit_HysH 255;
BA_ "GenSigInvalidValue" SG_ 1025 HiVolt_Battery_FullCapacity 4095;
BA_ "GenSigStartValue" SG_ 1025 SOC_xev_EMPTY 254;
BA_ "GenSigInvalidValue" SG_ 1025 SOC_xev_EMPTY 255;
BA_ "GenSigStartValue" SG_ 1025 SOC_xev_FULL 254;
BA_ "GenSigInvalidValue" SG_ 1025 SOC_xev_FULL 255;
BA_ "GenSigInvalidValue" SG_ 1025 Max_Charge_Minute_AC 255;
BA_ "GenSigTimeoutTime_ADU" SG_ 1025 AirAmb_Te_Actl 300;
BA_ "GenSigStartValue" SG_ 1025 AirAmbTe_D_Qf 1;
BA_ "GenSigTimeoutTime_ADU" SG_ 1025 AirAmbTe_D_Qf 300;
BA_ "GenSigStartValue" SG_ 1025 EngClntTe_D_Qf 1;
BA_ "GenSigStartValue" SG_ 1025 GPF_SootDepoWarning 1;
BA_ "GenSigStartValue" SG_ 1025 ECMMILRequest 1;
BA_ "GenSigStartValue" SG_ 1025 AirAmb_P_Actl 62;
BA_ "GenSigInvalidValue" SG_ 1025 AirAmb_P_Actl 63;
BA_ "GenSigInvalidValue" SG_ 1025 Permit_Power_AC 255;
BA_ "GenSigInvalidValue" SG_ 1025 Compressor_Power_Actual 255;
BA_ "GenSigInvalidValue" SG_ 1025 Compressor_Rev_Actual 65535;
BA_ "GenSigInvalidValue" SG_ 1025 PTCHeater_Power_Actual 255;
BA_ "GenSigSendType" SG_ 1010 CXP_UERR 3;
BA_ "GenSigSendType" SG_ 1010 P2Z_INV 3;
BA_ "GenSigSendType" SG_ 1010 GRPHLDR 3;
BA_ "GenSigSendType" SG_ 1010 GRPHLDL 3;
BA_ "GenSigSendType" SG_ 1010 TMPMFIX 3;
BA_ "GenSigSendType" SG_ 1010 TMPABNR 3;
BA_ "GenSigSendType" SG_ 1010 TMPABNL 3;
BA_ "GenSigSendType" SG_ 1010 GRPFAIL1 3;
BA_ "GenSigSendType" SG_ 1010 GRPFAIL0 3;
BA_ "GenSigSendType" SG_ 1010 F_HTRSW 3;
BA_ "GenSigSendType" SG_ 1010 F_HTROP 3;
BA_ "GenSigSendType" SG_ 1010 F_HTRGS 3;
BA_ "GenSigSendType" SG_ 1010 HPECU_MasterWarning_Rq 3;
BA_ "GenSigSendType" SG_ 1010 HPECU_calc_CVN 3;
BA_ "GenSigSendType" SG_ 1010 HPECU_DTC_Clear_Comp 3;
BA_ "GenSigSendType" SG_ 1010 HP_Remote_PreAC_Res 3;
BA_ "GenSigSendType" SG_ 1010 HP_PreAC_RearDef_Rq 3;
BA_ "GenSigSendType" SG_ 1010 HP_State_PreAC_Operation 3;
BA_ "GenSigSendType" SG_ 1010 HP_Flg_HeatExchgFrost 3;
BA_ "GenSigSendType" SG_ 1010 HP_Fail_OperationCycleFail 3;
BA_ "GenSigSendType" SG_ 1010 HP_State_OperationCycle 3;
BA_ "GenSigSendType" SG_ 1010 HP_Fail_TempRfrgCondOut 3;
BA_ "GenSigSendType" SG_ 1010 HP_Fail_SolVlv_Warm 3;
BA_ "GenSigSendType" SG_ 1010 HP_Fail_SolVlv_HiPre_Fail 3;
BA_ "GenSigSendType" SG_ 1010 DBKL_MET 3;
BA_ "GenSigStartValue" SG_ 1010 DBKL_MET 2;
BA_ "GenSigStartValue" SG_ 1010 atcAMratioPs 254;
BA_ "GenSigInvalidValue" SG_ 1010 atcAMratioPs 255;
BA_ "GenSigStartValue" SG_ 1010 atcAMratioDr 254;
BA_ "GenSigInvalidValue" SG_ 1010 atcAMratioDr 255;
BA_ "GenSigStartValue" SG_ 1010 atcAImodeRecRatio 254;
BA_ "GenSigInvalidValue" SG_ 1010 atcAImodeRecRatio 255;
BA_ "GenSigStartValue" SG_ 1010 atcADmode 14;
BA_ "GenSigInvalidValue" SG_ 1010 atcADmode 15;
BA_ "GenSigInvalidValue" SG_ 1010 BAT_Cool_DistRate 63;
BA_ "GenSigStartValue" SG_ 1010 BAT_TXV_Trg 4094;
BA_ "GenSigInvalidValue" SG_ 994 Navi_grad_MM 255;
BA_ "GenSigInvalidValue" SG_ 994 Navi_Oneway_dist0 255;
BA_ "GenSigInvalidValue" SG_ 994 Navi_Oneway_flg0 7;
BA_ "GenSigInvalidValue" SG_ 994 Navi_Oneway_MM 7;
BA_ "GenSigInvalidValue" SG_ 994 Navi_BuildupArea_dist2 255;
BA_ "GenSigInvalidValue" SG_ 994 Navi_BuildupArea_flg2 3;
BA_ "GenSigInvalidValue" SG_ 994 Navi_BuildupArea_dist1 255;
BA_ "GenSigInvalidValue" SG_ 994 Navi_BuildupArea_flg1 3;
BA_ "GenSigInvalidValue" SG_ 994 Navi_BuildupArea_MM 3;
BA_ "GenSigInvalidValue" SG_ 994 Navi_brdg_sctn_dist0 255;
BA_ "GenSigInvalidValue" SG_ 994 Navi_brdg_dist0 255;
BA_ "GenSigInvalidValue" SG_ 994 Navi_tnnl_sctn_dist_type0 255;
BA_ "GenSigInvalidValue" SG_ 994 Navi_tnnl_dist0 255;
BA_ "GenSigStartValue" SG_ 988 Multi_Carriageway_Dist 1023;
BA_ "GenSigStartValue" SG_ 988 Lane_Num_Dist 4095;
BA_ "GenSigStartValue" SG_ 988 ADAS_Map_Link_Type_Dist 1023;
BA_ "GenSigStartValue" SG_ 988 ADAS_Map_SUB_Distance_Ego 1023;
BA_ "GenSigInvalidValue" SG_ 988 ADAS_Map_SUB_Distance_Ego 1023;
BA_ "GenSigStartValue" SG_ 988 Route_Destination_Dist 4095;
BA_ "GenSigStartValue" SG_ 988 Stop_Info_Dist 1023;
BA_ "GenSigStartValue" SG_ 988 One_Way_Code_Dist 1023;
BA_ "GenSigStartValue" SG_ 988 Supplymental_Speed_Limit_Ego 255;
BA_ "GenSigSendType" SG_ 985 NavCountry_Roadside 3;
BA_ "GenSigSendType" SG_ 985 Speed_Limit_Unit 3;
BA_ "GenSigSendType" SG_ 985 Speed_Limit 3;
BA_ "GenSigInvalidValue" SG_ 985 Speed_Limit 1000;
BA_ "GenSigStartValue" SG_ 985 Speed_Limit_Dist 4095;
BA_ "GenSigStartValue" SG_ 985 NavFunctionalRoadClass_Next 31;
BA_ "GenSigStartValue" SG_ 985 NavFunctionalRoadClass_Dist 4095;
BA_ "GenSigStartValue" SG_ 985 NavFunctionalRoadClass_Ego 31;
BA_ "GenSigStartValue" SG_ 985 ADAS_MAP_DR_Confidence 3;
BA_ "GenSigInvalidValue" SG_ 985 ADAS_MAP_DR_Confidence 3;
BA_ "GenSigStartValue" SG_ 985 ADAS_MAP_MAP_Accuracy 3;
BA_ "GenSigInvalidValue" SG_ 985 ADAS_MAP_MAP_Accuracy 3;
BA_ "GenSigStartValue" SG_ 985 ADAS_MAP_Curvature300_index 3;
BA_ "GenSigStartValue" SG_ 985 ADAS_MAP_Curvature300_2digit 127;
BA_ "GenSigInvalidValue" SG_ 985 ADAS_MAP_Curvature300_2digit 127;
BA_ "GenSigStartValue" SG_ 985 ADAS_MAP_Curvature200_index 3;
BA_ "GenSigStartValue" SG_ 985 ADAS_MAP_Curvature200_2digit 127;
BA_ "GenSigInvalidValue" SG_ 985 ADAS_MAP_Curvature200_2digit 127;
BA_ "GenSigStartValue" SG_ 985 ADAS_MAP_Curvature100_index 3;
BA_ "GenSigStartValue" SG_ 985 ADAS_MAP_Curvature100_2digit 127;
BA_ "GenSigInvalidValue" SG_ 985 ADAS_MAP_Curvature100_2digit 127;
BA_ "GenSigStartValue" SG_ 985 ADAS_MAP_Curvature0_index 3;
BA_ "GenSigStartValue" SG_ 985 ADAS_MAP_Curvature0_2digit 127;
BA_ "GenSigInvalidValue" SG_ 985 ADAS_MAP_Curvature0_2digit 127;
BA_ "GenSigStartValue" SG_ 985 ADAS_Map_SUB_Attribute 7;
BA_ "GenSigInvalidValue" SG_ 985 ADAS_Map_SUB_Attribute 7;
BA_ "GenSigStartValue" SG_ 985 ADAS_Map_SUB_Distance 1023;
BA_ "GenSigInvalidValue" SG_ 985 ADAS_Map_SUB_Distance 1023;
BA_ "GenSigStartValue" SG_ 985 ADAS_Map_PositionConfidence 7;
BA_ "GenSigInvalidValue" SG_ 985 ADAS_Map_PositionConfidence 7;
BA_ "GenSigSendType" SG_ 977 HMI_State_Notice_ISPU 3;
BA_ "GenSigSendType" SG_ 975 RTANDISM 3;
BA_ "GenSigSendType" SG_ 975 FHLBRAKE 3;
BA_ "GenSigSendType" SG_ 975 FHL_EQ 3;
BA_ "GenSigSendType" SG_ 975 ADDSTRI1 3;
BA_ "GenSigSendType" SG_ 975 ADDSTRI2 3;
BA_ "GenSigSendType" SG_ 975 RVAITRG2 3;
BA_ "GenSigSendType" SG_ 975 FHL_TRG 3;
BA_ "GenSigSendType" SG_ 975 FHL_STAT 3;
BA_ "GenSigStartValue" SG_ 975 FHL_STAT 1;
BA_ "GenSigSendType" SG_ 974 CAAINDIR 3;
BA_ "GenSigSendType" SG_ 974 CAAINDIM 3;
BA_ "GenSigStartValue" SG_ 973 HITANG 255;
BA_ "GenSigSendType" SG_ 973 SABTRCYC 3;
BA_ "GenSigStartValue" SG_ 973 TAGTTC 65535;
BA_ "GenSigSendType" SG_ 972 CSR_BUZ 3;
BA_ "GenSigSendType" SG_ 972 CSR_VOL 3;
BA_ "GenSigSendType" SG_ 972 CAM_INF1 3;
BA_ "GenSigSendType" SG_ 972 CSRAVABL 3;
BA_ "GenSigSendType" SG_ 972 ICSAVABL 3;
BA_ "GenSigSendType" SG_ 972 RCDAVABL 3;
BA_ "GenSigSendType" SG_ 972 PKSS_VE 3;
BA_ "GenSigSendType" SG_ 972 PKSSINFO 3;
BA_ "GenSigSendType" SG_ 972 CSR_INF2 3;
BA_ "GenSigSendType" SG_ 972 CSR_INF1 3;
BA_ "GenSigSendType" SG_ 972 RLS_DIRT 3;
BA_ "GenSigSendType" SG_ 972 RRS_DIRT 3;
BA_ "GenSigSendType" SG_ 972 FLS_DIRT 3;
BA_ "GenSigSendType" SG_ 972 FRS_DIRT 3;
BA_ "GenSigSendType" SG_ 972 RLC_DIRT 3;
BA_ "GenSigSendType" SG_ 972 RRC_DIRT 3;
BA_ "GenSigSendType" SG_ 972 RL_DIRT 3;
BA_ "GenSigSendType" SG_ 972 RR_DIRT 3;
BA_ "GenSigSendType" SG_ 972 FLC_DIRT 3;
BA_ "GenSigSendType" SG_ 972 FRC_DIRT 3;
BA_ "GenSigSendType" SG_ 972 FL_DIRT 3;
BA_ "GenSigSendType" SG_ 972 FR_DIRT 3;
BA_ "GenSigSendType" SG_ 971 CS_LAMP 3;
BA_ "GenSigSendType" SG_ 971 CSR_TTR 3;
BA_ "GenSigSendType" SG_ 971 CSDETSYM 3;
BA_ "GenSigSendType" SG_ 971 CSR_VE3 3;
BA_ "GenSigSendType" SG_ 971 CSRDISP3 3;
BA_ "GenSigSendType" SG_ 961 Dtc_Ip_SSrInCar_CircuitGndShort 3;
BA_ "GenSigSendType" SG_ 961 Dtc_Ip_SSrInCar_CircuitOpen 3;
BA_ "GenSigSendType" SG_ 961 HazardSw_D_Actl 3;
BA_ "GenSigStartValue" SG_ 961 HazardSw_D_Actl 3;
BA_ "GenSigTimeoutTime_ADU" SG_ 961 HazardSw_D_Actl 600;
BA_ "GenSigSendType" SG_ 961 RearDef_SwitchIn 3;
BA_ "GenSigSendType" SG_ 961 FrontDef_SwitchIn 3;
BA_ "GenSigSendType" SG_ 961 InCarTe_D_Qf 3;
BA_ "GenSigStartValue" SG_ 961 InCarTe_D_Qf 1;
BA_ "GenSigStartValue" SG_ 960 ADAS_MAP_Distance_to_tunnel 511;
BA_ "GenSigStartValue" SG_ 960 ADAS_MAP_Tunnel_inf 3;
BA_ "GenSigStartValue" SG_ 960 ADAS_Map_Link_Type_Ego 14;
BA_ "GenSigInvalidValue" SG_ 960 ADAS_Map_Link_Type_Ego 15;
BA_ "GenSigStartValue" SG_ 960 ADAS_Map_FormofWay_Ego 14;
BA_ "GenSigInvalidValue" SG_ 960 ADAS_Map_FormofWay_Ego 15;
BA_ "GenSigSendType" SG_ 960 NavFunctionalRoadClass 3;
BA_ "GenSigStartValue" SG_ 960 NavFunctionalRoadClass 31;
BA_ "GenSigSendType" SG_ 960 NavBuildUpArea_flg 3;
BA_ "GenSigSendType" SG_ 960 NavDataAvailable_flg 3;
BA_ "GenSigSendType" SG_ 960 NavCountryCode 3;
BA_ "GenSigSendType" SG_ 960 ipRearDef_Ind 3;
BA_ "GenSigSendType" SG_ 960 RearDef_B_Rq 3;
BA_ "GenSigSendType" SG_ 960 FrontDef_B_Rq 3;
BA_ "GenSigSendType" SG_ 960 PanelHeaterSwitchIn_RH 3;
BA_ "GenSigSendType" SG_ 960 PanelHeaterSwitchIn_LH 3;
BA_ "GenSigSendType" SG_ 960 SteeringHeaterSwitchIn 3;
BA_ "GenSigSendType" SG_ 960 SeatVentilationSwitchIn_RH 3;
BA_ "GenSigSendType" SG_ 960 SeatHeaterSwitchIn_RH 3;
BA_ "GenSigSendType" SG_ 960 SeatVentilationSwitchIn_LH 3;
BA_ "GenSigSendType" SG_ 960 SeatHeaterSwitchIn_LH 3;
BA_ "GenSigSendType" SG_ 960 ipREARmode 3;
BA_ "GenSigSendType" SG_ 960 ipECOmode 3;
BA_ "GenSigSendType" SG_ 960 ipAImode 3;
BA_ "GenSigSendType" SG_ 960 ipADmode 3;
BA_ "GenSigSendType" SG_ 960 ipACmode 3;
BA_ "GenSigSendType" SG_ 960 ipBlwLvl 3;
BA_ "GenSigSendType" SG_ 960 ipTSetPs 3;
BA_ "GenSigSendType" SG_ 960 ipTSetDr 3;
BA_ "GenSigSendType" SG_ 923 DS_INST7 3;
BA_ "GenSigSendType" SG_ 923 DS_INST6 3;
BA_ "GenSigSendType" SG_ 923 DS_INST5 3;
BA_ "GenSigSendType" SG_ 923 DS_INST4 3;
BA_ "GenSigSendType" SG_ 923 DS_INST3 3;
BA_ "GenSigSendType" SG_ 923 DS_INST2 3;
BA_ "GenSigSendType" SG_ 923 DS_INST1 3;
BA_ "GenSigSendType" SG_ 923 DS_FUNID 3;
BA_ "GenSigSendType" SG_ 920 TRMANSEL 3;
BA_ "GenSigSendType" SG_ 920 TRLC_RS 3;
BA_ "GenSigSendType" SG_ 920 TRLC_YN 3;
BA_ "GenSigSendType" SG_ 920 TRLC_LN 3;
BA_ "GenSigSendType" SG_ 920 TRLC_AX 3;
BA_ "GenSigSendType" SG_ 920 TRLC_HT 3;
BA_ "GenSigSendType" SG_ 920 TRLC_AC 3;
BA_ "GenSigSendType" SG_ 920 TRLC_ID 3;
BA_ "GenSigSendType" SG_ 919 TSSMLDIR 3;
BA_ "GenSigSendType" SG_ 919 TSSLNNUM 3;
BA_ "GenSigSendType" SG_ 919 OTHUNRCV 3;
BA_ "GenSigSendType" SG_ 919 AVNCBFLG 3;
BA_ "GenSigSendType" SG_ 919 DSTRNCP 3;
BA_ "GenSigSendType" SG_ 919 TSSRNCFG 3;
BA_ "GenSigSendType" SG_ 919 DSTEXIT 3;
BA_ "GenSigStartValue" SG_ 918 NOP_S6 63;
BA_ "GenSigStartValue" SG_ 918 NOP_S5 63;
BA_ "GenSigStartValue" SG_ 918 NOP_S4 63;
BA_ "GenSigStartValue" SG_ 918 NOP_S3 63;
BA_ "GenSigStartValue" SG_ 918 NOP_S2 63;
BA_ "GenSigStartValue" SG_ 918 NOP_S1 63;
BA_ "GenSigStartValue" SG_ 918 NOP_CI 31;
BA_ "GenSigStartValue" SG_ 918 NOP_P 63;
BA_ "GenSigSendType" SG_ 918 SUR_STAT 3;
BA_ "GenSigSendType" SG_ 918 BM 3;
BA_ "GenSigSendType" SG_ 918 CS_R_SW 3;
BA_ "GenSigSendType" SG_ 918 BZ_M_SW 3;
BA_ "GenSigSendType" SG_ 894 MAV_WASH 3;
BA_ "GenSigSendType" SG_ 894 R_CROP_0 3;
BA_ "GenSigSendType" SG_ 894 BGMMUTE 3;
BA_ "GenSigSendType" SG_ 894 MAVTYPE 3;
BA_ "GenSigSendType" SG_ 894 ENBLMMSW 3;
BA_ "GenSigSendType" SG_ 894 MAV_BP_L 3;
BA_ "GenSigSendType" SG_ 894 MAV_BP_S 3;
BA_ "GenSigSendType" SG_ 894 MAV_ERR 3;
BA_ "GenSigSendType" SG_ 894 RM_DISP 3;
BA_ "GenSigSendType" SG_ 893 EDAPHZ 3;
BA_ "GenSigSendType" SG_ 893 EDAHZD 3;
BA_ "GenSigSendType" SG_ 893 EDAHRN 3;
BA_ "GenSigSendType" SG_ 893 EDRLCA 3;
BA_ "GenSigSendType" SG_ 893 EDRAES 3;
BA_ "GenSigSendType" SG_ 893 EDRLTA 3;
BA_ "GenSigSendType" SG_ 893 EDRESA 3;
BA_ "GenSigSendType" SG_ 893 EDRLDWS 3;
BA_ "GenSigSendType" SG_ 893 EDRLDA 3;
BA_ "GenSigSendType" SG_ 892 SYNCID3 3;
BA_ "GenSigSendType" SG_ 892 CLTRLLEN 3;
BA_ "GenSigSendType" SG_ 892 HON_RSN 3;
BA_ "GenSigSendType" SG_ 892 HOFSTATE 3;
BA_ "GenSigSendType" SG_ 892 TSGN5 3;
BA_ "GenSigSendType" SG_ 892 TSGNHLT5 3;
BA_ "GenSigSendType" SG_ 892 SPLSGN5 3;
BA_ "GenSigSendType" SG_ 892 CLATD 3;
BA_ "GenSigSendType" SG_ 892 TLTASYST 3;
BA_ "GenSigSendType" SG_ 857 cmu_fail_state 3;
BA_ "GenSigSendType" SG_ 857 EDA_onsw_dispflag 3;
BA_ "GenSigSendType" SG_ 857 HOFDIOPE 3;
BA_ "GenSigSendType" SG_ 857 HOFOK 3;
BA_ "GenSigSendType" SG_ 857 PLUSSW 3;
BA_ "GenSigSendType" SG_ 857 LCASGAPR 3;
BA_ "GenSigSendType" SG_ 855 OTASTAT 3;
BA_ "GenSigSendType" SG_ 855 OTASWACT 3;
BA_ "GenSigSendType" SG_ 855 OTAACTPH 3;
BA_ "GenSigSendType" SG_ 855 OTAACTTP 3;
BA_ "GenSigSendType" SG_ 855 OTACDRLT 3;
BA_ "GenSigSendType" SG_ 855 OTA3CNCL 3;
BA_ "GenSigSendType" SG_ 855 OTA3RSLT 3;
BA_ "GenSigStartValue" SG_ 854 SPLDIST2 255;
BA_ "GenSigStartValue" SG_ 854 SPLDIST1 255;
BA_ "GenSigStartValue" SG_ 854 SNBDIST2 255;
BA_ "GenSigStartValue" SG_ 854 SNBINF2 3;
BA_ "GenSigStartValue" SG_ 854 SNBDIST1 255;
BA_ "GenSigStartValue" SG_ 854 SNBINF1 3;
BA_ "GenSigStartValue" SG_ 854 CURINF8 2047;
BA_ "GenSigStartValue" SG_ 854 CURVAL8 2047;
BA_ "GenSigStartValue" SG_ 854 CURINF7 2047;
BA_ "GenSigStartValue" SG_ 854 CURVAL7 2047;
BA_ "GenSigStartValue" SG_ 854 CURINF6 2047;
BA_ "GenSigStartValue" SG_ 854 CURVAL6 2047;
BA_ "GenSigStartValue" SG_ 854 CURINF5 2047;
BA_ "GenSigStartValue" SG_ 854 CURVAL5 2047;
BA_ "GenSigStartValue" SG_ 854 CURINF4 2047;
BA_ "GenSigStartValue" SG_ 854 CURVAL4 2047;
BA_ "GenSigStartValue" SG_ 854 CURINF3 2047;
BA_ "GenSigStartValue" SG_ 854 CURVAL3 2047;
BA_ "GenSigStartValue" SG_ 854 CURINF2 2047;
BA_ "GenSigStartValue" SG_ 854 CURVAL2 2047;
BA_ "GenSigStartValue" SG_ 854 CURINF1 2047;
BA_ "GenSigStartValue" SG_ 854 CURVAL1 2047;
BA_ "GenSigStartValue" SG_ 854 CURINFO2 2047;
BA_ "GenSigStartValue" SG_ 854 FRMSID5 31;
BA_ "GenSigStartValue" SG_ 851 ALTYP3 1023;
BA_ "GenSigStartValue" SG_ 851 ALRDTY3 31;
BA_ "GenSigStartValue" SG_ 851 SPDIST2 255;
BA_ "GenSigStartValue" SG_ 851 FWSPAU2 15;
BA_ "GenSigStartValue" SG_ 851 FWSPTY2 7;
BA_ "GenSigStartValue" SG_ 851 FWSPD2 31;
BA_ "GenSigStartValue" SG_ 851 SPDIST1 255;
BA_ "GenSigStartValue" SG_ 851 FWSPAU1 15;
BA_ "GenSigStartValue" SG_ 851 FWSPTY1 7;
BA_ "GenSigStartValue" SG_ 851 FWSPD1 31;
BA_ "GenSigStartValue" SG_ 851 MPSPAU1 15;
BA_ "GenSigStartValue" SG_ 851 MPSPTY1 7;
BA_ "GenSigStartValue" SG_ 851 MPSP1 31;
BA_ "GenSigStartValue" SG_ 851 NALRDTY6 31;
BA_ "GenSigStartValue" SG_ 851 NALRDTY5 31;
BA_ "GenSigStartValue" SG_ 851 NALRDTY4 31;
BA_ "GenSigStartValue" SG_ 851 NALRDTY3 31;
BA_ "GenSigStartValue" SG_ 851 NALRDTY2 31;
BA_ "GenSigStartValue" SG_ 851 NALRDTY1 31;
BA_ "GenSigStartValue" SG_ 851 NALANG6 63;
BA_ "GenSigStartValue" SG_ 851 NALNEN6 3;
BA_ "GenSigStartValue" SG_ 851 NALNLN6 15;
BA_ "GenSigStartValue" SG_ 851 NALTYP6 1023;
BA_ "GenSigStartValue" SG_ 851 NALINT6 7;
BA_ "GenSigStartValue" SG_ 851 NALANG5 63;
BA_ "GenSigStartValue" SG_ 851 NALNEN5 3;
BA_ "GenSigStartValue" SG_ 851 NALNLN5 15;
BA_ "GenSigStartValue" SG_ 851 NALTYP5 1023;
BA_ "GenSigStartValue" SG_ 851 NALINT5 7;
BA_ "GenSigStartValue" SG_ 851 NALANG4 63;
BA_ "GenSigStartValue" SG_ 851 NALNEN4 3;
BA_ "GenSigStartValue" SG_ 851 NALNLN4 15;
BA_ "GenSigStartValue" SG_ 851 NALTYP4 1023;
BA_ "GenSigStartValue" SG_ 851 NALINT4 7;
BA_ "GenSigStartValue" SG_ 851 NALANG3 63;
BA_ "GenSigStartValue" SG_ 851 NALNEN3 3;
BA_ "GenSigStartValue" SG_ 851 NALNLN3 15;
BA_ "GenSigStartValue" SG_ 851 NALTYP3 1023;
BA_ "GenSigStartValue" SG_ 851 NALINT3 7;
BA_ "GenSigStartValue" SG_ 851 NALANG2 63;
BA_ "GenSigStartValue" SG_ 851 NALNEN2 3;
BA_ "GenSigStartValue" SG_ 851 NALNLN2 15;
BA_ "GenSigStartValue" SG_ 851 NALTYP2 1023;
BA_ "GenSigStartValue" SG_ 851 NALINT2 7;
BA_ "GenSigStartValue" SG_ 851 NALANG1 63;
BA_ "GenSigStartValue" SG_ 851 NALNEN1 3;
BA_ "GenSigStartValue" SG_ 851 NALNLN1 15;
BA_ "GenSigStartValue" SG_ 851 NALTYP1 1023;
BA_ "GenSigStartValue" SG_ 851 NALINT1 7;
BA_ "GenSigStartValue" SG_ 851 FRMSID3 31;
BA_ "GenSigStartValue" SG_ 850 INTID2 7;
BA_ "GenSigStartValue" SG_ 850 INTID1 7;
BA_ "GenSigStartValue" SG_ 850 ALANG3 63;
BA_ "GenSigStartValue" SG_ 850 ALNLN3 15;
BA_ "GenSigStartValue" SG_ 850 CURINF10 2047;
BA_ "GenSigStartValue" SG_ 850 ALNLN2 15;
BA_ "GenSigStartValue" SG_ 850 CURVAL10 2047;
BA_ "GenSigStartValue" SG_ 850 ENSIBD2 3;
BA_ "GenSigStartValue" SG_ 850 ENSIBD1 3;
BA_ "GenSigStartValue" SG_ 850 CURINF9 2047;
BA_ "GenSigStartValue" SG_ 850 ALNLN1 15;
BA_ "GenSigStartValue" SG_ 850 CURVAL9 2047;
BA_ "GenSigStartValue" SG_ 850 RLDXDST2 255;
BA_ "GenSigStartValue" SG_ 850 RLDXDST1 255;
BA_ "GenSigStartValue" SG_ 850 TRLDIST2 255;
BA_ "GenSigStartValue" SG_ 850 TRLDIST1 255;
BA_ "GenSigStartValue" SG_ 850 PAYMTB1 255;
BA_ "GenSigStartValue" SG_ 850 PAYMTA1 255;
BA_ "GenSigStartValue" SG_ 850 TOLSTY1 255;
BA_ "GenSigStartValue" SG_ 850 TOLDIST1 255;
BA_ "GenSigStartValue" SG_ 850 ALRDTY2 31;
BA_ "GenSigStartValue" SG_ 850 ALTYP2 1023;
BA_ "GenSigStartValue" SG_ 850 ALRDTY1 31;
BA_ "GenSigStartValue" SG_ 850 ALTYP1 1023;
BA_ "GenSigStartValue" SG_ 850 ALANG2 63;
BA_ "GenSigStartValue" SG_ 850 ENLNTY2 1023;
BA_ "GenSigStartValue" SG_ 850 ALANG1 63;
BA_ "GenSigStartValue" SG_ 850 ENLNTY1 1023;
BA_ "GenSigStartValue" SG_ 850 ENSIG2 3;
BA_ "GenSigStartValue" SG_ 850 ENSIG1 3;
BA_ "GenSigStartValue" SG_ 850 ENRDTY2 31;
BA_ "GenSigStartValue" SG_ 850 ENRDTY1 31;
BA_ "GenSigStartValue" SG_ 850 INTNLN2 31;
BA_ "GenSigStartValue" SG_ 850 INTNLN1 31;
BA_ "GenSigStartValue" SG_ 850 INTDIS2 255;
BA_ "GenSigStartValue" SG_ 850 INTDIS1 255;
BA_ "GenSigStartValue" SG_ 850 FRMSID2 31;
BA_ "GenSigStartValue" SG_ 849 INTID3 7;
BA_ "GenSigStartValue" SG_ 849 DWAYFLG2 3;
BA_ "GenSigStartValue" SG_ 849 DWAYFLG1 3;
BA_ "GenSigStartValue" SG_ 849 CURINF11 2047;
BA_ "GenSigStartValue" SG_ 849 MPOSDFLG 3;
BA_ "GenSigStartValue" SG_ 849 CURVAL11 2047;
BA_ "GenSigStartValue" SG_ 849 DFLGD2 255;
BA_ "GenSigStartValue" SG_ 849 DFLGD1 255;
BA_ "GenSigStartValue" SG_ 849 ENRDTY3 31;
BA_ "GenSigStartValue" SG_ 849 ENSIBD3 3;
BA_ "GenSigStartValue" SG_ 849 INTNLN3 31;
BA_ "GenSigStartValue" SG_ 849 ENLNTY3 1023;
BA_ "GenSigStartValue" SG_ 849 INTDIS3 255;
BA_ "GenSigStartValue" SG_ 849 LNNUMD3 255;
BA_ "GenSigStartValue" SG_ 849 LNNUMD2 255;
BA_ "GenSigStartValue" SG_ 849 LNNUMD1 255;
BA_ "GenSigStartValue" SG_ 849 LNNUM3 15;
BA_ "GenSigStartValue" SG_ 849 LNNUM2 15;
BA_ "GenSigStartValue" SG_ 849 LNNUM1 15;
BA_ "GenSigStartValue" SG_ 849 ENSIG3 3;
BA_ "GenSigStartValue" SG_ 849 MPLNNUM 15;
BA_ "GenSigStartValue" SG_ 849 MPMEDFLG 3;
BA_ "GenSigStartValue" SG_ 849 MPLNKTYP 1023;
BA_ "GenSigStartValue" SG_ 849 RDTYPD2 255;
BA_ "GenSigStartValue" SG_ 849 FWRDTYP2 31;
BA_ "GenSigStartValue" SG_ 849 RDTYPD1 255;
BA_ "GenSigStartValue" SG_ 849 FWRDTYP1 31;
BA_ "GenSigStartValue" SG_ 849 MPRDTYP 31;
BA_ "GenSigStartValue" SG_ 849 RERTCNTR 15;
BA_ "GenSigStartValue" SG_ 849 CNTRYCD 1023;
BA_ "GenSigStartValue" SG_ 849 DAYFMUPD 4294967295;
BA_ "GenSigStartValue" SG_ 849 MAPCVR 3;
BA_ "GenSigStartValue" SG_ 849 MLTMDST 3;
BA_ "GenSigStartValue" SG_ 849 MAPMCNFD 255;
BA_ "GenSigStartValue" SG_ 849 RTGUIDST 3;
BA_ "GenSigStartValue" SG_ 849 SENSORF 7;
BA_ "GenSigStartValue" SG_ 849 SENSST 7;
BA_ "GenSigStartValue" SG_ 849 FRMSID1 31;
BA_ "GenSigSendType" SG_ 848 RECRNOFF 3;
BA_ "GenSigSendType" SG_ 848 WUREQ 3;
BA_ "GenSigSendType" SG_ 848 RECEND 3;
BA_ "GenSigSendType" SG_ 848 IMGI_POF 3;
BA_ "GenSigSendType" SG_ 847 ID34F_No_Cs 3;
BA_ "GenSigSendType" SG_ 847 LCFP 3;
BA_ "GenSigSendType" SG_ 847 DM_BZR 3;
BA_ "GenSigSendType" SG_ 847 LCAINDI 3;
BA_ "GenSigSendType" SG_ 847 DM_DISPM 3;
BA_ "GenSigSendType" SG_ 847 DM_HRNRQ 3;
BA_ "GenSigSendType" SG_ 847 DM_DRULK 3;
BA_ "GenSigSendType" SG_ 847 ACCSPMEX 3;
BA_ "GenSigSendType" SG_ 847 ACCSPMD 3;
BA_ "GenSigSendType" SG_ 847 DM_TRNRQ 3;
BA_ "GenSigSendType" SG_ 847 LCSRWNGD 3;
BA_ "GenSigSendType" SG_ 847 LCSARRRD 3;
BA_ "GenSigSendType" SG_ 847 LCSARRLD 3;
BA_ "GenSigSendType" SG_ 847 LCSLWNGD 3;
BA_ "GenSigSendType" SG_ 847 LCASGIND 3;
BA_ "GenSigSendType" SG_ 847 LCAMSG 3;
BA_ "GenSigSendType" SG_ 847 LCWNKONR 3;
BA_ "GenSigSendType" SG_ 847 LCWNKONL 3;
BA_ "GenSigSendType" SG_ 847 DISPREQA 3;
BA_ "GenSigSendType" SG_ 847 DISPUP 3;
BA_ "GenSigSendType" SG_ 847 LTCMODE 3;
BA_ "GenSigSendType" SG_ 847 LCSONSD 3;
BA_ "GenSigSendType" SG_ 847 LCSRQBZ 3;
BA_ "GenSigSendType" SG_ 847 LCAVCBZ 3;
BA_ "GenSigSendType" SG_ 847 LCANGBZ 3;
BA_ "GenSigSendType" SG_ 847 ID34F_No_Cnt 3;
BA_ "GenSigSendType" SG_ 846 OMI_R 3;
BA_ "GenSigSendType" SG_ 846 OMI_L 3;
BA_ "GenSigSendType" SG_ 845 TRABUZ 3;
BA_ "GenSigSendType" SG_ 844 TSSOPE28 3;
BA_ "GenSigSendType" SG_ 844 TSSOPE27 3;
BA_ "GenSigSendType" SG_ 844 TSSOPE26 3;
BA_ "GenSigSendType" SG_ 844 TSSOPE25 3;
BA_ "GenSigSendType" SG_ 844 TSSOPE24 3;
BA_ "GenSigSendType" SG_ 844 TSSOPE23 3;
BA_ "GenSigSendType" SG_ 844 TSSOPE22 3;
BA_ "GenSigSendType" SG_ 844 TSSOPE21 3;
BA_ "GenSigSendType" SG_ 843 TSSOPE17 3;
BA_ "GenSigSendType" SG_ 843 TSSOPE16 3;
BA_ "GenSigSendType" SG_ 843 TSSOPE15 3;
BA_ "GenSigSendType" SG_ 843 TSSOPE14 3;
BA_ "GenSigSendType" SG_ 843 TSSOPE13 3;
BA_ "GenSigSendType" SG_ 843 TSSOPE12 3;
BA_ "GenSigSendType" SG_ 843 TSSOPE11 3;
BA_ "GenSigSendType" SG_ 843 TSSVRRES 3;
BA_ "GenSigSendType" SG_ 842 TSSFNC28 3;
BA_ "GenSigSendType" SG_ 842 TSSFNC27 3;
BA_ "GenSigSendType" SG_ 842 TSSFNC26 3;
BA_ "GenSigSendType" SG_ 842 TSSFNC25 3;
BA_ "GenSigSendType" SG_ 842 TSSFNC24 3;
BA_ "GenSigSendType" SG_ 842 TSSFNC23 3;
BA_ "GenSigSendType" SG_ 842 TSSFNC22 3;
BA_ "GenSigSendType" SG_ 842 TSSFNC21 3;
BA_ "GenSigSendType" SG_ 841 TSSFNC17 3;
BA_ "GenSigSendType" SG_ 841 TSSFNC16 3;
BA_ "GenSigSendType" SG_ 841 TSSFNC15 3;
BA_ "GenSigSendType" SG_ 841 TSSFNC14 3;
BA_ "GenSigSendType" SG_ 841 TSSFNC13 3;
BA_ "GenSigSendType" SG_ 841 TSSFNC12 3;
BA_ "GenSigSendType" SG_ 841 TSSFNC11 3;
BA_ "GenSigSendType" SG_ 841 TSS_TID 3;
BA_ "GenSigSendType" SG_ 840 TSSOBS2 3;
BA_ "GenSigSendType" SG_ 840 TSSOBL2 3;
BA_ "GenSigSendType" SG_ 840 TSSOBLP2 3;
BA_ "GenSigSendType" SG_ 840 TSSOBT2 3;
BA_ "GenSigSendType" SG_ 840 TSSOBJD2 3;
BA_ "GenSigSendType" SG_ 840 TSSOBS1 3;
BA_ "GenSigSendType" SG_ 840 TSSOBL1 3;
BA_ "GenSigSendType" SG_ 840 TSSOBLP1 3;
BA_ "GenSigSendType" SG_ 840 TSSOBT1 3;
BA_ "GenSigSendType" SG_ 840 TSSOBJD1 3;
BA_ "GenSigSendType" SG_ 839 ACCVRAPR 3;
BA_ "GenSigSendType" SG_ 839 CCSVRAPR 3;
BA_ "GenSigSendType" SG_ 839 ISAVRAPR 3;
BA_ "GenSigSendType" SG_ 839 LTAVRAPR 3;
BA_ "GenSigSendType" SG_ 839 TSSMDREJ 3;
BA_ "GenSigSendType" SG_ 839 GUI_LTA 3;
BA_ "GenSigSendType" SG_ 839 GUI_MODE 3;
BA_ "GenSigSendType" SG_ 839 LDAINDIM 3;
BA_ "GenSigSendType" SG_ 839 PCSINDIM 3;
BA_ "GenSigSendType" SG_ 839 FCMINDIR 3;
BA_ "GenSigSendType" SG_ 839 TSSSPMS1 3;
BA_ "GenSigSendType" SG_ 839 TSSSPMS2 3;
BA_ "GenSigSendType" SG_ 839 TSSSPMS3 3;
BA_ "GenSigSendType" SG_ 839 GUI_DOWN 3;
BA_ "GenSigSendType" SG_ 839 GUI_UP 3;
BA_ "GenSigSendType" SG_ 839 TSSSPMD3 3;
BA_ "GenSigSendType" SG_ 839 TSSSPMD2 3;
BA_ "GenSigSendType" SG_ 839 GUI_SET 3;
BA_ "GenSigSendType" SG_ 839 GUI_RES 3;
BA_ "GenSigSendType" SG_ 839 TSSSPMD1 3;
BA_ "GenSigSendType" SG_ 839 TSSSPMSG 3;
BA_ "GenSigSendType" SG_ 839 GUI_CAN 3;
BA_ "GenSigSendType" SG_ 839 GUI_DIST 3;
BA_ "GenSigSendType" SG_ 839 TSSSPSEL 3;
BA_ "GenSigSendType" SG_ 839 TSSSPNUM 3;
BA_ "GenSigSendType" SG_ 839 TSSSPDIS 3;
BA_ "GenSigSendType" SG_ 839 GUI_MAIN 3;
BA_ "GenSigSendType" SG_ 838 OTAMSTAT 3;
BA_ "GenSigSendType" SG_ 838 OTA3ERR 3;
BA_ "GenSigStartValue" SG_ 838 OTA3ERR 255;
BA_ "GenSigSendType" SG_ 838 OTA3PROG 3;
BA_ "GenSigStartValue" SG_ 838 OTA3PROG 255;
BA_ "GenSigStartValue" SG_ 838 OTA3STAT 15;
BA_ "GenSigStartValue" SG_ 838 OTA3TYPE 15;
BA_ "GenSigSendType" SG_ 837 PDAEXIST 3;
BA_ "GenSigSendType" SG_ 837 PDAONST 3;
BA_ "GenSigSendType" SG_ 837 SDGEXIST 3;
BA_ "GenSigSendType" SG_ 837 SDGONST 3;
BA_ "GenSigSendType" SG_ 837 SDGCONT 3;
BA_ "GenSigSendType" SG_ 837 USMEXIST 3;
BA_ "GenSigSendType" SG_ 837 USMONST 3;
BA_ "GenSigSendType" SG_ 837 USMTLTYP 3;
BA_ "GenSigSendType" SG_ 837 USMTLDSW 3;
BA_ "GenSigSendType" SG_ 837 USMSW 3;
BA_ "GenSigSendType" SG_ 837 USMDSE 3;
BA_ "GenSigSendType" SG_ 837 USMDSPSW 3;
BA_ "GenSigSendType" SG_ 837 ISAAVABL 3;
BA_ "GenSigSendType" SG_ 837 TMNAVABL 3;
BA_ "GenSigSendType" SG_ 837 TSSPOP 3;
BA_ "GenSigSendType" SG_ 837 CCEX 3;
BA_ "GenSigSendType" SG_ 837 CCAVABL 3;
BA_ "GenSigSendType" SG_ 837 IDAAVABL 3;
BA_ "GenSigSendType" SG_ 837 USMAVABL 3;
BA_ "GenSigSendType" SG_ 837 AHBAVABL 3;
BA_ "GenSigSendType" SG_ 837 ACCAVABL 3;
BA_ "GenSigSendType" SG_ 837 PCSAVABL 3;
BA_ "GenSigSendType" SG_ 837 TSSTUNA 3;
BA_ "GenSigSendType" SG_ 837 TSSMALF 3;
BA_ "GenSigSendType" SG_ 837 FRDTUCT 3;
BA_ "GenSigSendType" SG_ 837 FRDTEMP 3;
BA_ "GenSigSendType" SG_ 837 FRDDUST 3;
BA_ "GenSigSendType" SG_ 837 FCMTEMP 3;
BA_ "GenSigSendType" SG_ 837 FCMDUST 3;
BA_ "GenSigSendType" SG_ 832 Sensor_fault_condition 3;
BA_ "GenSigSendType" SG_ 832 AB_Config 3;
BA_ "GenSigSendType" SG_ 832 Time_from_1to2_at_multi_event 3;
BA_ "GenSigStartValue" SG_ 832 Time_from_1to2_at_multi_event 254;
BA_ "GenSigInvalidValue" SG_ 832 Time_from_1to2_at_multi_event 255;
BA_ "GenSigSendType" SG_ 832 Max_lat_deltaV_second_old 3;
BA_ "GenSigInvalidValue" SG_ 832 Max_lat_deltaV_second_old 254;
BA_ "GenSigSendType" SG_ 832 Max_long_deltaV_second_old 3;
BA_ "GenSigInvalidValue" SG_ 832 Max_long_deltaV_second_old 254;
BA_ "GenSigSendType" SG_ 832 Max_lat_deltaV_latest 3;
BA_ "GenSigInvalidValue" SG_ 832 Max_lat_deltaV_latest 254;
BA_ "GenSigSendType" SG_ 832 Max_long_deltaV_latest 3;
BA_ "GenSigInvalidValue" SG_ 832 Max_long_deltaV_latest 254;
BA_ "GenSigSendType" SG_ 832 Event_Type_Info_second_old 3;
BA_ "GenSigSendType" SG_ 832 Event_Type_Info_latest 3;
BA_ "GenSigSendType" SG_ 832 RCM_EDRtype 3;
BA_ "GenSigSendType" SG_ 832 EDRTrigger 3;
BA_ "GenSigInvalidValue" SG_ 832 EDRTrigger 2;
BA_ "GenSigSendType" SG_ 832 FirstRowBucklePsngr_FD 3;
BA_ "GenSigStartValue" SG_ 832 FirstRowBucklePsngr_FD 1;
BA_ "GenSigSendType" SG_ 832 OCS_Status 3;
BA_ "GenSigStartValue" SG_ 832 OCS_Status 1;
BA_ "GenSigSendType" SG_ 832 PAD_Ind_Req 3;
BA_ "GenSigStartValue" SG_ 832 PAD_Ind_Req 4;
BA_ "GenSigSendType" SG_ 807 USMDPRTR 3;
BA_ "GenSigSendType" SG_ 807 USMDPRTL 3;
BA_ "GenSigSendType" SG_ 807 USMAVDST 3;
BA_ "GenSigSendType" SG_ 807 USMPVDST 3;
BA_ "GenSigSendType" SG_ 807 USMBZ 3;
BA_ "GenSigSendType" SG_ 807 USMBLNK 3;
BA_ "GenSigSendType" SG_ 807 USMMSG 3;
BA_ "GenSigSendType" SG_ 807 USMIRPTR 3;
BA_ "GenSigSendType" SG_ 807 USMIRPTL 3;
BA_ "GenSigSendType" SG_ 807 USMOR 3;
BA_ "GenSigSendType" SG_ 807 USMDSPCR 3;
BA_ "GenSigSendType" SG_ 807 USMDSPSS 3;
BA_ "GenSigSendType" SG_ 807 USMDSPTL 3;
BA_ "GenSigSendType" SG_ 807 USMIRQ 3;
BA_ "GenSigSendType" SG_ 807 USMDSPPV 3;
BA_ "GenSigSendType" SG_ 807 DWREQ 3;
BA_ "GenSigSendType" SG_ 807 USMBLNK2 3;
BA_ "GenSigSendType" SG_ 807 USMAVPOS 3;
BA_ "GenSigSendType" SG_ 807 USMAVCOL 3;
BA_ "GenSigSendType" SG_ 807 IDAINDI 3;
BA_ "GenSigSendType" SG_ 807 IDACON 3;
BA_ "GenSigSendType" SG_ 807 IDAIRQ 3;
BA_ "GenSigSendType" SG_ 807 IDADSPR 3;
BA_ "GenSigSendType" SG_ 807 IDACAN 3;
BA_ "GenSigSendType" SG_ 807 IDABUZZ 3;
BA_ "GenSigSendType" SG_ 807 IDADSPC 3;
BA_ "GenSigSendType" SG_ 807 IDAEMPR 3;
BA_ "GenSigSendType" SG_ 807 IDAEMPL 3;
BA_ "GenSigSendType" SG_ 807 IDAEMPC 3;
BA_ "GenSigSendType" SG_ 807 IDAONST 3;
BA_ "GenSigSendType" SG_ 807 IDASENST 3;
BA_ "GenSigStartValue" SG_ 807 IDASENST 2;
BA_ "GenSigSendType" SG_ 807 IDAEXIST 3;
BA_ "GenSigSendType" SG_ 807 IDADSPL 3;
BA_ "GenSigStartValue" SG_ 806 OTHVRVPC 1850;
BA_ "GenSigStartValue" SG_ 806 OTHRVPC 1850;
BA_ "GenSigSendType" SG_ 806 OTHTRCYC 3;
BA_ "GenSigStartValue" SG_ 806 OTHVRVEL 1850;
BA_ "GenSigStartValue" SG_ 806 OTHVRDIS 255;
BA_ "GenSigStartValue" SG_ 806 OTHRVEL 1850;
BA_ "GenSigStartValue" SG_ 806 OTHTTC 4095;
BA_REL_ "SC_Verification" BU_SG_REL_ CGW SG_ 805 KZK325_MACTx 0;
BA_REL_ "SC_Verification" BU_SG_REL_ CGW SG_ 805 FV325_FVTx 0;
BA_ "GenSigSendType" SG_ 805 APPSYS2 3;
BA_ "GenSigSendType" SG_ 805 APPMD2 3;
BA_ "GenSigSendType" SG_ 804 VIDEO_OK 3;
BA_ "GenSigSendType" SG_ 804 ACCSSAGB 3;
BA_ "GenSigSendType" SG_ 804 ACCSSAG 3;
BA_ "GenSigSendType" SG_ 804 ACCRSACB 3;
BA_ "GenSigSendType" SG_ 804 ACCRSAC 3;
BA_ "GenSigSendType" SG_ 804 ACCIMDD 3;
BA_ "GenSigSendType" SG_ 804 ACCSPPD 3;
BA_ "GenSigSendType" SG_ 804 ACCTRLD 3;
BA_ "GenSigSendType" SG_ 804 ISAEX 3;
BA_ "GenSigSendType" SG_ 804 ACCCSPU 3;
BA_ "GenSigSendType" SG_ 803 ACCALTD 3;
BA_ "GenSigSendType" SG_ 803 ACCCNTOB 3;
BA_ "GenSigSendType" SG_ 803 ACCBZRQ 3;
BA_ "GenSigSendType" SG_ 803 ACCMSGV 3;
BA_ "GenSigSendType" SG_ 803 ACCMODE 3;
BA_ "GenSigSendType" SG_ 803 ACCMSG4 3;
BA_ "GenSigSendType" SG_ 803 ACCMSGU 3;
BA_ "GenSigSendType" SG_ 803 ACCMSG3 3;
BA_ "GenSigSendType" SG_ 803 ACCMSG2 3;
BA_ "GenSigSendType" SG_ 803 ACCMSG1 3;
BA_ "GenSigSendType" SG_ 802 ACCDTST2 3;
BA_ "GenSigSendType" SG_ 802 ACCDTST1 3;
BA_ "GenSigSendType" SG_ 802 ACCDST 3;
BA_ "GenSigSendType" SG_ 802 ERMMAXID 3;
BA_ "GenSigSendType" SG_ 802 ACCSUST2 3;
BA_ "GenSigSendType" SG_ 802 ACCSUST1 3;
BA_ "GenSigSendType" SG_ 802 ACCSPST2 3;
BA_ "GenSigSendType" SG_ 802 ACCSPST1 3;
BA_ "GenSigSendType" SG_ 802 ACCSP 3;
BA_ "GenSigSendType" SG_ 802 ACCSPEXC 3;
BA_ "GenSigSendType" SG_ 802 ACCSPU 3;
BA_ "GenSigSendType" SG_ 802 ISALIMID 3;
BA_ "GenSigSendType" SG_ 802 ASLID 3;
BA_ "GenSigSendType" SG_ 802 ACCSETID 3;
BA_ "GenSigSendType" SG_ 802 ISAID 3;
BA_ "GenSigSendType" SG_ 802 ACCCCSID 3;
BA_ "GenSigSendType" SG_ 802 ACCID 3;
BA_ "GenSigSendType" SG_ 800 PCSDISPD 3;
BA_ "GenSigSendType" SG_ 800 PCSDIDST 3;
BA_ "GenSigSendType" SG_ 800 PCSDWIND 3;
BA_ "GenSigSendType" SG_ 800 PCSDWON 3;
BA_ "GenSigSendType" SG_ 799 LDAVCMCS 3;
BA_ "GenSigSendType" SG_ 799 LTAVCMCS 3;
BA_ "GenSigSendType" SG_ 799 LCAVCMCS 3;
BA_ "GenSigSendType" SG_ 798 RLS_WRN 3;
BA_ "GenSigSendType" SG_ 798 RRS_WRN 3;
BA_ "GenSigSendType" SG_ 798 FLS_WRN 3;
BA_ "GenSigSendType" SG_ 798 RLS_POS 3;
BA_ "GenSigSendType" SG_ 798 RRS_POS 3;
BA_ "GenSigSendType" SG_ 798 FRS_WRN 3;
BA_ "GenSigSendType" SG_ 798 FLS_POS 3;
BA_ "GenSigSendType" SG_ 798 FRS_POS 3;
BA_ "GenSigSendType" SG_ 798 MV_RC 3;
BA_ "GenSigSendType" SG_ 798 MV_FC 3;
BA_ "GenSigSendType" SG_ 798 MV_RRS 3;
BA_ "GenSigSendType" SG_ 798 MV_RLS 3;
BA_ "GenSigSendType" SG_ 798 MV_FRS 3;
BA_ "GenSigSendType" SG_ 798 MV_FLS 3;
BA_ "GenSigSendType" SG_ 798 MV_RR 3;
BA_ "GenSigSendType" SG_ 798 MV_RL 3;
BA_ "GenSigSendType" SG_ 798 MV_FR 3;
BA_ "GenSigSendType" SG_ 798 MV_FL 3;
BA_ "GenSigInvalidValue" SG_ 797 Deletion_Result_OMS 15;
BA_ "GenSigInvalidValue" SG_ 797 Registration_Result_OMS 15;
BA_ "GenSigInvalidValue" SG_ 797 Recovery_Request_OMS 31;
BA_ "GenSigInvalidValue" SG_ 797 Identification_Score_OMS 127;
BA_ "GenSigInvalidValue" SG_ 797 Identification_Result_OMS 15;
BA_ "GenSigInvalidValue" SG_ 796 DrvrHeadReli 7;
BA_ "GenSigStartValue" SG_ 796 FACEZ 126;
BA_ "GenSigInvalidValue" SG_ 796 FACEZ 127;
BA_ "GenSigStartValue" SG_ 796 FACEY 251;
BA_ "GenSigInvalidValue" SG_ 796 FACEY 252;
BA_ "GenSigStartValue" SG_ 796 FACEX 126;
BA_ "GenSigInvalidValue" SG_ 796 FACEX 127;
BA_ "GenSigInvalidValue" SG_ 795 DrvrEyeRReli 7;
BA_ "GenSigInvalidValue" SG_ 795 DrvrEyeLReli 7;
BA_ "GenSigInvalidValue" SG_ 795 DrvrFaceReli 7;
BA_ "GenSigStartValue" SG_ 795 GAZEV 241;
BA_ "GenSigInvalidValue" SG_ 795 GAZEV 242;
BA_ "GenSigStartValue" SG_ 795 GAZEH 241;
BA_ "GenSigInvalidValue" SG_ 795 GAZEH 242;
BA_ "GenSigStartValue" SG_ 795 FACEROL 241;
BA_ "GenSigInvalidValue" SG_ 795 FACEROL 242;
BA_ "GenSigStartValue" SG_ 795 FACEYAW 241;
BA_ "GenSigInvalidValue" SG_ 795 FACEYAW 242;
BA_ "GenSigStartValue" SG_ 795 FACEPIT 241;
BA_ "GenSigInvalidValue" SG_ 795 FACEPIT 242;
BA_ "GenSigSendType" SG_ 793 DM_DISPC 3;
BA_ "GenSigSendType" SG_ 793 TSSVOI08 3;
BA_ "GenSigSendType" SG_ 793 TSSVOI02 3;
BA_ "GenSigSendType" SG_ 793 TSSVOI01 3;
BA_ "GenSigSendType" SG_ 793 TSSVOI06 3;
BA_ "GenSigSendType" SG_ 793 TSSVOI05 3;
BA_ "GenSigSendType" SG_ 792 AH_IND_S 3;
BA_ "GenSigSendType" SG_ 792 A_BW_PRE 3;
BA_ "GenSigSendType" SG_ 792 A_BW_IND 3;
BA_ "GenSigSendType" SG_ 792 A_HLLI 3;
BA_ "GenSigSendType" SG_ 792 A_LMP_ST 3;
BA_ "GenSigSendType" SG_ 792 OTHHLCOM 3;
BA_ "GenSigSendType" SG_ 792 OTHTLAH 3;
BA_ "GenSigSendType" SG_ 792 SRP_IND 3;
BA_ "GenSigSendType" SG_ 792 SRP_PRE 3;
BA_ "GenSigSendType" SG_ 791 HOF_REQ 3;
BA_ "GenSigSendType" SG_ 791 WRQ_DMG1 3;
BA_ "GenSigSendType" SG_ 791 HOF_NSG 3;
BA_ "GenSigSendType" SG_ 791 HOF_END 3;
BA_ "GenSigSendType" SG_ 791 HOF_MSG 3;
BA_ "GenSigSendType" SG_ 791 HOF_TRJ 3;
BA_ "GenSigSendType" SG_ 791 HOF_DISP 3;
BA_ "GenSigSendType" SG_ 791 HOF_BZR 3;
BA_ "GenSigSendType" SG_ 791 HOF_STAT 3;
BA_ "GenSigSendType" SG_ 791 HOF_PROP 3;
BA_ "GenSigSendType" SG_ 790 EDSSLPON 3;
BA_ "GenSigSendType" SG_ 790 EDSSSION 3;
BA_ "GenSigSendType" SG_ 790 EDSSHRN 3;
BA_ "GenSigSendType" SG_ 790 EDSSBZON 3;
BA_ "GenSigSendType" SG_ 787 HTR_REQ 3;
BA_ "GenSigSendType" SG_ 787 PLANTREQ 3;
BA_ "GenSigStartValue" SG_ 782 OTHPCNDS 60;
BA_ "GenSigStartValue" SG_ 782 OTHPSSDS 7;
BA_ "GenSigStartValue" SG_ 782 OTHPTLDS 127;
BA_ "GenSigStartValue" SG_ 782 OTHPLVRV 63;
BA_ "GenSigStartValue" SG_ 782 OTHPLVDS 255;
BA_ "GenSigSendType" SG_ 780 IMGOP_P 3;
BA_ "GenSigSendType" SG_ 780 DRADUABN 3;
BA_ "GenSigSendType" SG_ 780 DRADUTMP 3;
BA_ "GenSigSendType" SG_ 780 OFKP_ADU 3;
BA_ "GenSigInvalidValue" SG_ 608 ASE_Jrk_Trg 1048575;
BA_ "GenSigInvalidValue" SG_ 608 ASE_PrplWhlTot_Tq_Actl 65535;
BA_ "GenSigStartValue" SG_ 608 crnt_PT_pwr 1000;
BA_ "GenSigInvalidValue" SG_ 608 crnt_PT_pwr 2047;
BA_ "GenSigStartValue" SG_ 608 TELLTALE_4X4_AUTO 8;
BA_ "GenSigInvalidValue" SG_ 608 TRQ_XFER_CMND 255;
BA_ "GenSigStartValue" SG_ 608 MODE_4x4 2;
BA_ "GenSigSendType" SG_ 599 HMI_Request_ADU_CatS3_MACTx 3;
BA_ "GenSigSendType" SG_ 599 HMI_Request_ADU_CatS3_FVTx 3;
BA_ "GenSigSendType" SG_ 599 HMI_Request_ADU_CatS3_No_Cs 3;
BA_ "GenSigSendType" SG_ 599 HMI_Request_ADU_CatS3_No_Cnt 3;
BA_ "GenSigSendType" SG_ 599 HMI_Warning_LCA1_Rq 3;
BA_ "GenSigSendType" SG_ 599 HMI_Warning_DM3_Rq 3;
BA_ "GenSigSendType" SG_ 599 HMI_Warning_DM2_Rq 3;
BA_ "GenSigSendType" SG_ 599 HMI_Warning_DM1_Rq 3;
BA_ "GenSigSendType" SG_ 599 HMI_Warning_VCUNIT1_Rq 3;
BA_ "GenSigSendType" SG_ 599 HMI_Warning_OMC10_Rq 3;
BA_ "GenSigSendType" SG_ 599 HMI_Warning_OMC8_Rq 3;
BA_ "GenSigSendType" SG_ 599 HMI_Warning_OMC7_Rq 3;
BA_ "GenSigSendType" SG_ 599 HMI_Warning_OMC6_Rq 3;
BA_ "GenSigSendType" SG_ 599 HMI_Warning_OMC5_Rq 3;
BA_ "GenSigSendType" SG_ 599 HMI_Warning_OMC4_Rq 3;
BA_ "GenSigSendType" SG_ 599 HMI_Warning_OMC3_Rq 3;
BA_ "GenSigSendType" SG_ 599 HMI_Warning_OMC2_Rq 3;
BA_ "GenSigSendType" SG_ 599 HMI_Warning_OMC1_Rq 3;
BA_ "GenSigSendType" SG_ 599 HMI_Warning_VMC8_Rq 3;
BA_ "GenSigSendType" SG_ 599 HMI_Warning_VMC7_Rq 3;
BA_ "GenSigSendType" SG_ 599 HMI_Warning_VMC6_Rq 3;
BA_ "GenSigSendType" SG_ 599 HMI_Warning_VMC5_Rq 3;
BA_ "GenSigSendType" SG_ 599 HMI_Warning_VMC4_Rq 3;
BA_ "GenSigSendType" SG_ 599 HMI_Warning_VMC3_Rq 3;
BA_ "GenSigSendType" SG_ 599 HMI_Warning_VMC2_Rq 3;
BA_ "GenSigSendType" SG_ 599 HMI_Warning_VMC1_Rq 3;
BA_ "GenSigSendType" SG_ 599 HMI_Warning_Sonar4_Rq 3;
BA_ "GenSigSendType" SG_ 599 HMI_Warning_Sonar3_Rq 3;
BA_ "GenSigSendType" SG_ 599 HMI_Warning_Sonar2_Rq 3;
BA_ "GenSigSendType" SG_ 599 HMI_Warning_Sonar1_Rq 3;
BA_ "GenSigSendType" SG_ 599 HMI_Warning_RSRDR6_Rq 3;
BA_ "GenSigSendType" SG_ 599 HMI_Warning_RSRDR5_Rq 3;
BA_ "GenSigSendType" SG_ 599 HMI_Warning_RSRDR4_Rq 3;
BA_ "GenSigSendType" SG_ 599 HMI_Warning_RSRDR3_Rq 3;
BA_ "GenSigSendType" SG_ 599 HMI_Warning_RSRDR2_Rq 3;
BA_ "GenSigSendType" SG_ 599 HMI_Warning_RSRDR1_Rq 3;
BA_ "GenSigSendType" SG_ 599 HMI_Warning_FSRDR6_Rq 3;
BA_ "GenSigSendType" SG_ 599 HMI_Warning_FSRDR5_Rq 3;
BA_ "GenSigSendType" SG_ 599 HMI_Warning_FSRDR4_Rq 3;
BA_ "GenSigSendType" SG_ 599 HMI_Warning_FSRDR3_Rq 3;
BA_ "GenSigSendType" SG_ 599 HMI_Warning_FSRDR2_Rq 3;
BA_ "GenSigSendType" SG_ 599 HMI_Warning_FSRDR1_Rq 3;
BA_ "GenSigSendType" SG_ 599 HMI_Warning_FRDR6_Rq 3;
BA_ "GenSigSendType" SG_ 599 HMI_Warning_FRDR5_Rq 3;
BA_ "GenSigSendType" SG_ 599 HMI_Warning_FRDR4_Rq 3;
BA_ "GenSigSendType" SG_ 599 HMI_Warning_FRDR3_Rq 3;
BA_ "GenSigSendType" SG_ 599 HMI_Warning_FRDR2_Rq 3;
BA_ "GenSigSendType" SG_ 599 HMI_Warning_FRDR1_Rq 3;
BA_ "GenSigSendType" SG_ 599 HMI_Warning_FSC6_Rq 3;
BA_ "GenSigSendType" SG_ 599 HMI_Warning_FSC5_Rq 3;
BA_ "GenSigSendType" SG_ 599 HMI_Warning_FSC4_Rq 3;
BA_ "GenSigSendType" SG_ 599 HMI_Warning_FSC3_Rq 3;
BA_ "GenSigSendType" SG_ 599 HMI_Warning_FSC2_Rq 3;
BA_ "GenSigSendType" SG_ 599 HMI_Warning_FSC1_Rq 3;
BA_ "GenSigSendType" SG_ 599 HMI_Warning_HBC1_Rq 3;
BA_ "GenSigSendType" SG_ 599 HMI_Warning_ALH1_Rq 3;
BA_ "GenSigSendType" SG_ 599 HMI_Warning_PASR1_Rq 3;
BA_ "GenSigSendType" SG_ 599 HMI_Warning_TSR1_Rq 3;
BA_ "GenSigSendType" SG_ 599 HMI_Warning_LKA1_Rq 3;
BA_ "GenSigSendType" SG_ 599 HMI_Warning_ISA1_Rq 3;
BA_ "GenSigSendType" SG_ 599 HMI_Warning_ASC1_Rq 3;
BA_ "GenSigSendType" SG_ 599 HMI_Warning_ACC1_Rq 3;
BA_ "GenSigSendType" SG_ 598 HMI_Request_ADU_CatS2_MACTx 3;
BA_ "GenSigSendType" SG_ 598 HMI_Request_ADU_CatS2_FVTx 3;
BA_ "GenSigSendType" SG_ 598 HMI_Request_ADU_CatS2_No_Cs 3;
BA_ "GenSigSendType" SG_ 598 HMI_Request_ADU_CatS2_No_Cnt 3;
BA_ "GenSigSendType" SG_ 598 HMI_Status_VCUNIT1_Rq 3;
BA_ "GenSigSendType" SG_ 598 HMI_Status_OMC1_Rq 3;
BA_ "GenSigSendType" SG_ 598 HMI_Status_VMC1_Rq 3;
BA_ "GenSigSendType" SG_ 598 HMI_Status_Sonar1_Rq 3;
BA_ "GenSigSendType" SG_ 598 HMI_Status_RSRDR3_Rq 3;
BA_ "GenSigSendType" SG_ 598 HMI_Status_RSRDR2_Rq 3;
BA_ "GenSigSendType" SG_ 598 HMI_Status_RSRDR1_Rq 3;
BA_ "GenSigSendType" SG_ 598 HMI_Status_FSRDR3_Rq 3;
BA_ "GenSigSendType" SG_ 598 HMI_Status_FSRDR2_Rq 3;
BA_ "GenSigSendType" SG_ 598 HMI_Status_FSRDR1_Rq 3;
BA_ "GenSigSendType" SG_ 598 HMI_Status_FRDR3_Rq 3;
BA_ "GenSigSendType" SG_ 598 HMI_Status_FRDR2_Rq 3;
BA_ "GenSigSendType" SG_ 598 HMI_Status_FRDR1_Rq 3;
BA_ "GenSigSendType" SG_ 598 HMI_Status_FSC3_Rq 3;
BA_ "GenSigSendType" SG_ 598 HMI_Status_FSC2_Rq 3;
BA_ "GenSigSendType" SG_ 598 HMI_Status_FSC1_Rq 3;
BA_ "GenSigSendType" SG_ 598 HMI_Status_TMN2_Rq 3;
BA_ "GenSigSendType" SG_ 598 HMI_Status_TMN1_Rq 3;
BA_ "GenSigSendType" SG_ 598 HMI_Status_LCA12_Rq 3;
BA_ "GenSigSendType" SG_ 598 HMI_Status_LCA11_Rq 3;
BA_ "GenSigSendType" SG_ 598 HMI_Status_LCA10_Rq 3;
BA_ "GenSigSendType" SG_ 598 HMI_Status_LCA9_Rq 3;
BA_ "GenSigSendType" SG_ 598 HMI_Status_LCA8_Rq 3;
BA_ "GenSigSendType" SG_ 598 HMI_Status_LCA7_Rq 3;
BA_ "GenSigSendType" SG_ 598 HMI_Status_LCA6_Rq 3;
BA_ "GenSigSendType" SG_ 598 HMI_Status_LCA5_Rq 3;
BA_ "GenSigSendType" SG_ 598 HMI_Status_LCA4_Rq 3;
BA_ "GenSigSendType" SG_ 598 HMI_Status_LCA3_Rq 3;
BA_ "GenSigSendType" SG_ 598 HMI_Status_LCA2_Rq 3;
BA_ "GenSigSendType" SG_ 598 HMI_Status_LCA1_Rq 3;
BA_ "GenSigSendType" SG_ 598 HMI_Status_HoF11_Rq 3;
BA_ "GenSigSendType" SG_ 598 HMI_Status_HoF10_Rq 3;
BA_ "GenSigSendType" SG_ 598 HMI_Status_HoF9_Rq 3;
BA_ "GenSigSendType" SG_ 598 HMI_Status_HoF8_Rq 3;
BA_ "GenSigSendType" SG_ 598 HMI_Status_HoF7_Rq 3;
BA_ "GenSigSendType" SG_ 598 HMI_Status_HoF6_Rq 3;
BA_ "GenSigSendType" SG_ 598 HMI_Status_HoF5_Rq 3;
BA_ "GenSigSendType" SG_ 598 HMI_Status_HoF4_Rq 3;
BA_ "GenSigSendType" SG_ 598 HMI_Status_HoF3_Rq 3;
BA_ "GenSigSendType" SG_ 598 HMI_Status_HoF2_Rq 3;
BA_ "GenSigSendType" SG_ 598 HMI_Status_HoF1_Rq 3;
BA_ "GenSigSendType" SG_ 598 HMI_Status_AESESA1_Rq 3;
BA_ "GenSigSendType" SG_ 598 HMI_Status_PDA6_Rq 3;
BA_ "GenSigSendType" SG_ 598 HMI_Status_PDA5_Rq 3;
BA_ "GenSigSendType" SG_ 598 HMI_Status_PDA2_Rq 3;
BA_ "GenSigSendType" SG_ 598 HMI_Status_PDA1_Rq 3;
BA_ "GenSigSendType" SG_ 598 HMI_Status_REDKEY2_Rq 3;
BA_ "GenSigSendType" SG_ 598 HMI_Status_REDKEY1_Rq 3;
BA_ "GenSigSendType" SG_ 598 HMI_Status_EDA3_Rq 3;
BA_ "GenSigSendType" SG_ 598 HMI_Status_EDA2_Rq 3;
BA_ "GenSigSendType" SG_ 598 HMI_Status_EDA1_Rq 3;
BA_ "GenSigSendType" SG_ 598 HMI_Status_APSRPC1_Rq 3;
BA_ "GenSigSendType" SG_ 598 HMI_Status_DM18_Rq 3;
BA_ "GenSigSendType" SG_ 598 HMI_Status_DM14_Rq 3;
BA_ "GenSigSendType" SG_ 598 HMI_Status_DM13_Rq 3;
BA_ "GenSigSendType" SG_ 598 HMI_Status_DM12_Rq 3;
BA_ "GenSigSendType" SG_ 598 HMI_Status_DM11_Rq 3;
BA_ "GenSigSendType" SG_ 598 HMI_Status_DM10_Rq 3;
BA_ "GenSigSendType" SG_ 598 HMI_Status_DM9_Rq 3;
BA_ "GenSigSendType" SG_ 598 HMI_Status_DM8_Rq 3;
BA_ "GenSigSendType" SG_ 598 HMI_Status_DM7_Rq 3;
BA_ "GenSigSendType" SG_ 598 HMI_Status_DM6_Rq 3;
BA_ "GenSigSendType" SG_ 598 HMI_Status_DM5_Rq 3;
BA_ "GenSigSendType" SG_ 598 HMI_Status_DM4_Rq 3;
BA_ "GenSigSendType" SG_ 598 HMI_Status_DM3_Rq 3;
BA_ "GenSigSendType" SG_ 598 HMI_Status_DM2_Rq 3;
BA_ "GenSigSendType" SG_ 598 HMI_Status_DM1_Rq 3;
BA_ "GenSigSendType" SG_ 598 HMI_Status_PASFR8_Rq 3;
BA_ "GenSigSendType" SG_ 598 HMI_Status_PASFR7_Rq 3;
BA_ "GenSigSendType" SG_ 598 HMI_Status_PASFR6_Rq 3;
BA_ "GenSigSendType" SG_ 598 HMI_Status_PASFR5_Rq 3;
BA_ "GenSigSendType" SG_ 598 HMI_Status_PASFR4_Rq 3;
BA_ "GenSigSendType" SG_ 598 HMI_Status_PASFR3_Rq 3;
BA_ "GenSigSendType" SG_ 598 HMI_Status_PASFR2_Rq 3;
BA_ "GenSigSendType" SG_ 598 HMI_Status_PASFR1_Rq 3;
BA_ "GenSigSendType" SG_ 598 HMI_Status_PASR4_Rq 3;
BA_ "GenSigSendType" SG_ 598 HMI_Status_PASR3_Rq 3;
BA_ "GenSigSendType" SG_ 598 HMI_Status_PASR2_Rq 3;
BA_ "GenSigSendType" SG_ 598 HMI_Status_PASR1_Rq 3;
BA_ "GenSigSendType" SG_ 598 HMI_Status_PAS1_Rq 3;
VAL_ 1025 Gen_on_disp_req_CMU 0 "No_Display" 1 "SupplyStop" 2 "PowerLimited" ;
VAL_ 1025 DrvSys_Pwrdwn_Req_Xev 0 "OFF" 1 "ON" ;
VAL_ 1025 V2H_Supply_State 0 "No_Display" 1 "SupplyStop" 2 "PowerLimited" ;
VAL_ 1025 TrqDwn_MsgC_Rq 0 "OFF" 1 "ON" ;
VAL_ 1025 SelfWake_Set_Req 0 "unknown" 1 "wakeup" 2 "notwakeup" ;
VAL_ 1025 PSU_Supply_State 0 "No_Display" 1 "Powering" 2 "Supply_Stop" 3 "Display_3" 4 "Display_4" 5 "Display_5" 6 "---" 7 "---" ;
VAL_ 1025 HvBatSysWarn_D_Rq 0 "No_Display" 1 "Display_Guide1" 2 "Display_Guide2" ;
VAL_ 1025 GenSysState_D_Rq 0 "No_Display" 1 "Display_Maintenance" 2 "Display_Limit" 3 "Display_Disable" 4 "Display_Fail" 5 "Display_Maintenance_Pre1" 6 "Display_Maintenance_Pre2" 7 "Display_Maintenance_Pre3" ;
VAL_ 1025 TrqDwn_MsgB_Rq 0 "OFF" 1 "ON" ;
VAL_ 1025 TrqDwn_MsgA_Rq 0 "OFF" 1 "ON" ;
VAL_ 1025 TrqDwn_BzB_Rq 0 "OFF" 1 "ON" ;
VAL_ 1025 TrqDwn_BzA_Rq 0 "OFF" 1 "ON" ;
VAL_ 1025 DispEVMode_D_Rq 0 "No_Display" 1 "Display_1" 2 "Display_2" 3 "Display_3" ;
VAL_ 1025 BattTemp_Warn_D_Rq 0 "No_Display" 1 "Display_Guide1(Hot)" 2 "Display_Guide2(Cold)" ;
VAL_ 1025 RegenRejMsg_D_Req 0 "OFF" 1 "ON" ;
VAL_ 1025 RegenRejLamp_D_Req 0 "OFF" 1 "ON" ;
VAL_ 1025 Mot_D_ReqPwrHis 0 "OFF" 1 "ON" ;
VAL_ 1025 Mot_D_ReqPwrGain 0 "gain_0" 1 "gain_1" 2 "gain_2" 3 "gain_3" ;
VAL_ 1025 ElecDrvSys_Pwrdwn_Req 0 "OFF" 1 "ON" ;
VAL_ 1025 PwrDwn_Flash_Req 0 "OFF" 1 "ON" ;
VAL_ 1025 PwrDwn_D_Req 0 "OFF" 1 "ON" ;
VAL_ 1025 Charging_State_D_Actl 0 "Not_Charging" 1 "Normal_Chargeing" 2 "Quick_Chargeing1" 3 "Quick_Chargeing2" ;
VAL_ 1025 Charger_Connector_Fit_State 0 "Not_Connected" 1 "Normal_Charger_Connected" 2 "Quick_Charger1_Connected" 3 "Quick_Charger2_Connected" ;
VAL_ 1025 GenSys_Notavail_Req_Xev 0 "OFF" 1 "ON" ;
VAL_ 1025 EV_Warning_Ind_Req 0 "OFF" 1 "ON" ;
VAL_ 1025 ElecDrvSys_Caut_Req 0 "OFF" 1 "ON" ;
VAL_ 1025 BatteryHeater_ON 0 "OFF" 1 "ON" ;
VAL_ 1025 Batt_Lack_Warn_D_Rq 0 "No_Display" 1 "Display_level1" 2 "Display_level2" 3 "Display_level3" ;
VAL_ 1025 BatteryChargingPreTelltale 0 "OFF" 1 "ON" ;
VAL_ 1025 Charger_Connector_Fitting 0 "OFF" 1 "ON" ;
VAL_ 1025 Air_BleedingMode_Req 0 "OFF" 1 "ON" ;
VAL_ 1025 BatteryHeater_info3 0 "No_Display" 1 "Display" ;
VAL_ 1025 BatteryHeater_info2 0 "No_Display" 1 "Display" ;
VAL_ 1025 BatteryHeater_info1 0 "No_Display" 1 "Display_No1" 2 "Display_No2" 3 "Display_No3" ;
VAL_ 1025 SOC_Charge_Guide_Req_Xev 0 "OFF" 1 "ON" ;
VAL_ 1025 PbBatteryChargingState 0 "unknown" 1 "no_PbBatChg" 2 "Reserve" 3 "Reserve" 4 "PbBatChg" 5 "PbBatChg_fin" 6 "Reserve" 7 "Reserve" ;
VAL_ 1025 Useract_Reject_Msg 0 "OFF" 1 "Disable_Ready-ON_message" 2 "Ready-OFF_message" ;
VAL_ 1025 Leakage_Advan_Com 0 "OFF" 1 "ON" ;
VAL_ 1025 ChargSys_Error_Req 0 "OFF" 1 "ON" ;
VAL_ 1025 ChargSys_Warn_Req 0 "OFF" 1 "ON" ;
VAL_ 1025 ElecDrvSys_mainte_Req 0 "OFF" 1 "ON" ;
VAL_ 1025 FuelLid_Close_B_Req 0 "OFF" 1 "Fuel Lid CLOSE Request" ;
VAL_ 1025 Power_generation_State 0 "Unknown" 1 "Possible" 2 "Malfunction" 3 "Not Equipped" ;
VAL_ 1025 Battery_Deterioration 0 "0seg" 1 "1seg" 2 "2seg" 3 "3seg" 4 "4seg" 5 "5seg" 6 "6seg" 7 "7seg" 8 "8seg" 9 "9seg" 10 "10seg" 11 "no display" 12 "no display" 13 "no display" 14 "no display" 15 "no display" ;
VAL_ 1025 Batt_coling_disp_req_TCU 0 "NoRequest" 1 "Disp_Request" ;
VAL_ 1025 Batt_coling_disp_req_CMU 0 "NoRequest" 1 "Disp_Request" ;
VAL_ 1025 Refueling_Propriety_State 0 "OFF" 1 "Refueling Wait" 2 "Refueling Allowed" 3 "Refueling Disallowed" ;
VAL_ 1025 ElecDrvSys_Warn_Req 0 "OFF" 1 "ON" ;
VAL_ 1025 PowerDown 0 "OFF" 1 "Efective" ;
VAL_ 1025 REX_Run 0 "OFF" 1 "Running" ;
VAL_ 1025 SuplyStatus 0 "OFF" 1 "Supplying" ;
VAL_ 1025 DCChargeStatus 0 "OFF" 1 "Charging" ;
VAL_ 1025 ACChargeStatus 0 "OFF" 1 "Charging" ;
VAL_ 1025 EVData_2_mode 0 "Data1" 1 "Data2" 2 "Data3" ;
VAL_ 1025 OilDtrWrn_Stat_B_Actl 0 "OFF" 1 "ON" ;
VAL_ 1025 SedimentWarning 0 "OFF" 1 "ON" ;
VAL_ 1025 AirAmbTe_D_Qf 0 "Faulty" 1 "No_Data_Exists" 2 "Not_Within_Specifications" 3 "OK" ;
VAL_ 1025 EngClntTe_D_Qf 0 "Faulty" 1 "No_Data_Exists" 2 "Not_Within_Specifications" 3 "OK" ;
VAL_ 1025 DPFTelltale 0 "OFF" 1 "ON" ;
VAL_ 1025 OilDtrWrn_Init_B_Eco 0 "NotAccepted" 1 "Accepted" ;
VAL_ 1025 Oil_deteriorate_warning 0 "OFF" 1 "ON" ;
VAL_ 1025 FuelFilterWarning 0 "Warning OFF" 1 "Warning ON" ;
VAL_ 1025 OilPressureWarning 0 "Normal_Pressure_Lamp_Off" 1 "Low_Pressure_Lamp_On" ;
VAL_ 1025 OverrevBz_D_Rq 0 "No Request" 1 "Buzzer Pattern1" 2 "Buzzer Pattern2" 3 "Invalid" ;
VAL_ 1025 FUEL_CAP_OFF_TELTAL 0 "OFF" 1 "ON" ;
VAL_ 1025 EngineIdleStatus 0 "Not in IdleMode" 1 "Idle Mode" ;
VAL_ 1025 BatteryChargingTelltale 0 "OFF(Charging)" 1 "ON(Not Charging)" ;
VAL_ 1025 DieselGlowplugTelltale 0 "OFF" 1 "ON" ;
VAL_ 1025 Oil_Deteriorate_Warn_Rst 0 "OFF" 1 "ON" ;
VAL_ 1025 GPF_SootDepoWarning 0 "OFF" 1 "ON" ;
VAL_ 1025 PCM_BPS_DrESUPwr_Fail 0 "non Fail" 1 "Fail" ;
VAL_ 1025 DriverStatus_disp 0 "OFF(Inside)" 1 "ON(Outside)" ;
VAL_ 1025 LowTempTorqLimit 0 "OFF" 1 "ON" ;
VAL_ 1025 HighTempTorqLimit 0 "OFF" 1 "ON" ;
VAL_ 1025 MildHevBatteryWarningTelltale 0 "OFF" 1 "ON" ;
VAL_ 1025 MildHevWarningTelltale 0 "OFF" 1 "ON" ;
VAL_ 1025 BatteryPerformanceTelltale 0 "OFF" 1 "ON" ;
VAL_ 1025 OilLevelWarning 0 "Normal_Level_Lamp_Off" 1 "Low_Level_Lamp_On" 2 "Over_High_Level_Lamp_On" 3 "not used" ;
VAL_ 1025 ECMMILRequest 0 "Off" 1 "On" 2 "Flash" 3 "not used" ;
VAL_ 1025 PCM_INDLvl_D_Rq 0 "Off" 1 "Level1(MostSevere)" 2 "Level2(Severe)" 3 "Level3(NotSevere)" ;
VAL_ 1025 HPECU_DTC_Clear_Rq 0 "nonRequest clear" 1 "Request clear" ;
VAL_ 1025 AC_Mode_Sig 0 "Normal" 1 "preAC_Operated" 2 "preAC_Canceled (DC Charge)" 3 "preAC_Canceled_SOC" 4 "preAC_Candeled_Fail" ;
VAL_ 1025 BAT_Refcooling_Lvl 0 "level0" 1 "level1" 2 "level2" 3 "level3" 4 "level4" ;
VAL_ 1010 CXP_UERR 0 "Normal" 1 "Communication Error" ;
VAL_ 1010 GFPEXT 0 "Undecided" 1 "w/ Sensor & w/o Heater" 2 "w/ Sensor & w/ Heater" 3 "w/o Sensor & w/ Heater" ;
VAL_ 1010 P2Z_INV 0 "Valid" 1 "Invalid" ;
VAL_ 1010 GRPHLDR 0 "Hands OFF" 1 "Hands ON" ;
VAL_ 1010 GRPHLDL 0 "Hands OFF" 1 "Hands ON" ;
VAL_ 1010 TMPMFIX 0 "Usable" 1 "Temporary unusable" ;
VAL_ 1010 TMPABNR 0 "Usable" 1 "Temporary unusable" ;
VAL_ 1010 TMPABNL 0 "Usable" 1 "Temporary unusable" ;
VAL_ 1010 GRPFAIL1 0 "Normal" 1 "in Trouble" ;
VAL_ 1010 GRPFAIL0 0 "Normal" 1 "in Trouble" ;
VAL_ 1010 F_HTRSW 0 "Normal" 1 "Failure" ;
VAL_ 1010 F_HTROP 0 "Normal" 1 "Failure" ;
VAL_ 1010 F_HTRGS 0 "Normal" 1 "Failure" ;
VAL_ 1010 HPECU_MasterWarning_Rq 0 "Not request" 1 "MasterWarningRequest_FL1" 2 "MasterWarningRequest_FL2" 3 "MasterWarningRequest_FL3" 4 "MasterWarningRequest_FL4" ;
VAL_ 1010 HPECU_calc_CVN 0 "Not Calculating" 1 "Calculating CVN" ;
VAL_ 1010 HPECU_DTC_Clear_Comp 0 "Not Complete" 1 "Complete" ;
VAL_ 1010 HP_Remote_PreAC_Res 0 "OFF" 1 "ON" ;
VAL_ 1010 HP_PreAC_RearDef_Rq 0 "No request" 1 "Requested" ;
VAL_ 1010 HP_State_PreAC_Operation 0 "No_Operation" 1 "During judgment" 2 "Permit_PreAC" 3 "Operate_PreAC" 4 "Completed_PreAC" 5 "Reject1" 6 "Reject2" 7 "Reject3" 8 "Reject4" 9 "Reject5" 10 "Reject6" 11 "Reject7" 12 "reserved" 13 "reserved" 14 "reserved" 15 "reserved" ;
VAL_ 1010 HP_Flg_HeatExchgFrost 0 "FrostLevel_0" 1 "FrostLevel_1" 2 "FrostLevel_2" 3 "FrostLevel_3" ;
VAL_ 1010 HP_Fail_OperationCycleFail 0 "Normal" 1 "Failure" ;
VAL_ 1010 HP_State_OperationCycle 0 "Stop" 1 "Cooling" 2 "Warming" 3 "Defrost" 4 "BAT_Refcool_only" 5 "Cooling_BAT_Refcool" 6 "Cooling_Reject_BAT_Refcool" 7 "Warming_Reject_BAT_Refcool" 8 "Stop_Reject_BAT_Refcool" 15 "Not_Determined" ;
VAL_ 1010 HP_Fail_TempRfrgCondOut 0 "Normal" 1 "Circuit_Open" 2 "Battery_Short" 3 "Gnd_Short" ;
VAL_ 1010 HP_Fail_SolVlv_Warm 0 "Normal" 1 "Circuit_Open" 2 "Battery_Short" 3 "Gnd_Short" ;
VAL_ 1010 HP_Fail_SolVlv_HiPre_Fail 0 "Normal" 1 "Circuit_Open" 2 "Battery_Short" 3 "Gnd_Short" ;
VAL_ 1010 DBKL_MET 0 "Driver belt used" 1 "Driver belt not used" 2 "Not Defined" 3 "Fault (unused)" ;
VAL_ 1010 atcADmode 0 "-" 1 "-" 2 "PANEL" 3 "B/L" 4 "FLOOR" 5 "D/F" 6 "DEF" 7 "PANEL-B/L" 8 "B/L-FLOOR" 9 "FLOOR-D/F" 10 "D/F-DEF" 14 "No_Data_Exists" 15 "Faulty" ;
VAL_ 1010 THO_Control_Req 0 "Not Request" 1 "Water Heat Request" 2 "Reserved" 3 "Reserved" 4 "Reserved" 5 "Reserved" 6 "Reserved" 7 "Reserved" ;
VAL_ 1010 Compressor_Rev_Rq 0 "OFF" 1 "ON" ;
VAL_ 994 Navi_Oneway_dist_lsb0 0 "LSB=1m(const)" 1 "LSB=10m" ;
VAL_ 994 Navi_Oneway_flg0 0 "no passage in both directions" 1 "can pass in own directions" 2 "can pass in opposite directions" 3 "can pass in both directions" 4 "Reserved" 7 "Unknown" ;
VAL_ 994 Navi_Oneway_MM 0 "no passage in both directions" 1 "can pass in own directions" 2 "can pass in opposite directions" 3 "can pass in both directions" 4 "Reserved" 7 "Unknown" ;
VAL_ 994 Navi_BuildupArea_dist_lsb2 0 "LSB=1m(const)" 1 "LSB=10m" ;
VAL_ 994 Navi_BuildupArea_flg2 0 "not buildup area" 1 "buildup area" 2 "Reserved" 3 "Unknown" ;
VAL_ 994 Navi_BuildupArea_dist_lsb1 0 "LSB=1m(const)" 1 "LSB=10m" ;
VAL_ 994 Navi_BuildupArea_flg1 0 "not buildup area" 1 "buildup area" 2 "Reserved" 3 "Unknown" ;
VAL_ 994 Navi_BuildupArea_MM 0 "not buildup area" 1 "buildup area" 2 "Reserved" 3 "Unknown" ;
VAL_ 994 Navi_brdg_dist_type0 0 "not to end" 1 "to end" ;
VAL_ 994 Navi_brdg_dist_lsb0 0 "LSB=1m(const)" 1 "LSB=10m" ;
VAL_ 994 Navi_tnnl_dist_type0 0 "not to end" 1 "to end" ;
VAL_ 994 Navi_tnnl_dist_lsb0 0 "LSB=1m" 1 "LSB=10m" ;
VAL_ 988 ADAS_Map_PositionConfidence4 0 "Initial" 1 "OnRoad" 2 "OffRoad" 3 "Ferry" ;
VAL_ 988 ADAS_Map_PositionConfidence3 0 "Initial" 1 "No judgement of parking" 2 "Judgement of parking" ;
VAL_ 988 ADAS_Map_PositionConfidence2 0 "Initial" 1 "No judgement of intersection or " 2 "Judgement of intersection or bra" ;
VAL_ 988 ADAS_Map_PositionConfidence1 0 "Initial" 1 "No Map-matching candidate" 2 "One candidate map-matching road" 3 "No parallel roads" 4 "Multiple parallel roads" ;
VAL_ 988 MAP_Version 18212 "2018Q2CW12" ;
VAL_ 988 NavRouteGuidance_flg 0 "Initial" 1 "Cannot Route Guidance (Ex. CP/AA" 2 "No Route Guidance" 3 "Route Guidance" ;
VAL_ 988 Multi_Carriageway_Ego 0 "Initial" 1 "No Multi carriageway" 2 "Multi carriageway" ;
VAL_ 988 Lane_Num_Next 0 "Initial" 1 "1 lane on both way (narrow)" 2 "1 lane on each way (narrow)" 3 "1 lane on both way (wide)" 4 "1 lane on each way (wide)" 5 "1 lane on each way (unknown)" 6 "2 lane on each way" 7 "3 lane on each way" 8 "4 lane on each way" 9 "5 lane on each way" 10 "6 lane on each way" 11 "7 lane on each way" 12 "8 lane on each way" 15 "Unknown" ;
VAL_ 988 Lane_Num_Ego 0 "Initial" 1 "1 lane on both way (narrow)" 2 "1 lane on each way (narrow)" 3 "1 lane on both way (wide)" 4 "1 lane on each way (wide)" 5 "1 lane on each way (unknown)" 6 "2 lane on each way" 7 "3 lane on each way" 8 "4 lane on each way" 9 "5 lane on each way" 10 "6 lane on each way" 11 "7 lane on each way" 12 "8 lane on each way" 15 "Unknown" ;
VAL_ 988 ADAS_Map_SUB_Attribute_Ego 0 "Initial" 1 "Intersection" 2 "Junction" 3 "Junction" 4 "Rotary" 5 "Toll gate" 6 "Railroad crossing" 7 "Roundabout" 15 "Unknown" ;
VAL_ 988 Route_Destination_Ego 0 "Initial" 1 "Near Destionation" 2 "Near Ferry terminal" ;
VAL_ 988 Stop_Info_Ego 0 "Initial" 1 "No Stop" 2 "Stop" ;
VAL_ 988 One_Way_Code_Ego 0 "Initial" 1 "No One way" 2 "One way" ;
VAL_ 988 Supplymental_Speed_Sign_Ego 0 "Initial" 1 "School Zone" 2 "Time" 3 "Rain/Wetness" 4 "Snow/Ice" 5 "Trailer" 6 "Track" 7 "Tractor" ;
VAL_ 985 NavCountry_Roadside 0 "Invalid" 1 "Left-hand traffic" 2 "Right-hand traffic" ;
VAL_ 985 Speed_Limit_Unit 0 "No_Display" 1 "Mile" 2 "KiloMeter" 3 "Not_used" ;
VAL_ 985 NavZoneArea_flag_300m 0 "No_Zone" 1 "Zone" ;
VAL_ 985 NavZoneArea_flag_200m 0 "No_Zone" 1 "Zone" ;
VAL_ 985 NavZoneArea_flag_100m 0 "No_Zone" 1 "Zone" ;
VAL_ 985 NavZoneArea_flag 0 "No_Zone" 1 "Zone" ;
VAL_ 985 Implicit_Speed_Sign_Ego 0 "Initial" 1 "Motorway" 2 "Highway/Express way" 3 "City Entrance" 4 "Residential Area" ;
VAL_ 985 Speed_Limit_Sign_Ego 0 "Initial" 1 "Speed Limit" 2 "End of Speed Limit" 3 "End of All" ;
VAL_ 985 Speed_Limit_Accuracy_Ego 0 "Initial" 1 "Low reliability (Ex. Variable sp" 2 "Medium reliability" 3 "High reliability (Ex.Static spee" ;
VAL_ 985 NavFunctionalRoadClass_Next 0 "Motorway" 1 "National Highway in some specifi" 2 "reserve" 3 "reserve" 4 "Major roads of high importance" 5 "Other major roads" 6 "Secondary roads" 7 "reserve" 8 "Local connecting roads" 9 "Local roads of high importance" 10 "Residential connecting roads" 11 "reserve" 12 "Residential roads" 13 "Other roads, usually not suitabl" 14 "Narrow alley (in Japan)" 15 "Default roadclass" 31 "Unknow" ;
VAL_ 985 NavFunctionalRoadClass_Ego 0 "Motorway" 1 "National Highway in some specifi" 2 "reserve" 3 "reserve" 4 "Major roads of high importance" 5 "Other major roads" 6 "Secondary roads" 7 "reserve" 8 "Local connecting roads" 9 "Local roads of high importance" 10 "Residential connecting roads" 11 "reserve" 12 "Residential roads" 13 "Other roads, usually not suitabl" 14 "Narrow alley (in Japan)" 15 "Default roadclass" 31 "Unknow" ;
VAL_ 985 ADAS_MAP_DR_Confidence 0 "Confidence_High(~80m)" 1 "Confidence_Mid(80~120m)" 2 "Confidence_Low (120m~)" 3 "N/A" ;
VAL_ 985 ADAS_MAP_MAP_Accuracy 0 "10m at 1sigma" 1 "17.5m-22m at 1sigma" 2 "Reserved" 3 "n/a" ;
VAL_ 985 ADAS_Map_SUB_Attribute 0 "Intersection" 1 "Junction" 2 "Toll gate" 3 "Railroad crossing" 4 "Reserved" 5 "Reserved" 6 "Reserved" 7 "N/A" ;
VAL_ 985 ADAS_Map_PositionConfidence 0 "One candidate map-mathcing road " 1 "One candidate map-matching road " 2 "No parallel roads and No Judgeme" 3 "No parallel roads and Judgement " 4 "Multiple parallel roads and No J" 5 "Multiple parallel roads and Judg" 6 "No Map-matcing candidate." 7 "N/A" ;
VAL_ 977 HMI_State_Notice_ISPU 0 "Non Active" 1 "Active" 2 "malfunction" 3 "Reserved" ;
VAL_ 961 Dtc_Ip_SSrInCar_CircuitGndShort 0 "Normal" 1 "Fail" ;
VAL_ 961 Dtc_Ip_SSrInCar_CircuitOpen 0 "Normal" 1 "Fail" ;
VAL_ 961 HazardSw_D_Actl 0 "OFF" 1 "ON" 2 "Reserved" 3 "Unknown" ;
VAL_ 961 RearDef_SwitchIn 0 "OFF" 1 "ON" ;
VAL_ 961 FrontDef_SwitchIn 0 "OFF" 1 "ON" ;
VAL_ 961 InCarTe_D_Qf 0 "Faulty" 1 "No_Data_Exists" 2 "Not_Within_Specifications" 3 "OK" ;
VAL_ 960 ADAS_MAP_Tunnel_inf 0 "In the tunnel" 1 "Unknow / Out of the tunnel" 2 "Reserved" 3 "N/A" ;
VAL_ 960 ADAS_Map_Link_Type_Ego 0 "Reserved" 1 "Reserved" 2 "Reserved" 3 "Reserved" 4 "Reserved" 5 "Reserved" 6 "Reserved" 7 "Reserved" 8 "Reserved" 9 "Reserved" 10 "Reserved" 11 "Reserved" 12 "Reserved" 13 "Reserved" 14 "unknow(Road type is nothing)" 15 "Error" ;
VAL_ 960 ADAS_Map_FormofWay_Ego 0 "Reserved" 1 "Highway" 2 "Reserved" 3 "General Road" 4 "Reserved" 5 "Reserved" 6 "Reserved" 7 "Reserved" 8 "Reserved" 9 "Reserved" 10 "Other Road(Parking place)" 11 "Reserved" 12 "Reserved" 13 "Reserved" 14 "unknow(Road type is nothing)" 15 "Error" ;
VAL_ 960 NavFunctionalRoadClass 0 "Motorway" 1 "National Highway in some specifi" 2 "reserve" 3 "reserve" 4 "Major roads of high importance" 5 "Other major roads" 6 "Secondary roads" 7 "reserve" 8 "Local connecting roads" 9 "Local roads of high importance" 10 "Residential connecting roads" 11 "reserve" 12 "Residential roads" 13 "Other roads, usually not suitabl" 14 "Narrow alley (in Japan)" 15 "Default roadclass" 31 "Unknow" ;
VAL_ 960 NavBuildUpArea_flg 0 "No_BuildUpArea" 1 "BuildUpArea" ;
VAL_ 960 NavDataAvailable_flg 0 "Not Available" 1 "Available Position Not Fix" 2 "Available Position Fix" 3 "Fail" ;
VAL_ 960 ipRearDef_Ind 0 "Off" 1 "On" ;
VAL_ 960 RearDef_B_Rq 0 "Rear defogger Off" 1 "Rear defogger On" ;
VAL_ 960 FrontDef_B_Rq 0 "Front defroster Off" 1 "Front defroster On" ;
VAL_ 960 PanelHeaterSwitchIn_RH 0 "Off" 1 "Low" 2 "Mid" 3 "High" 4 "Auto" ;
VAL_ 960 PanelHeaterSwitchIn_LH 0 "Off" 1 "Low" 2 "Mid" 3 "High" 4 "Auto" ;
VAL_ 960 SteeringHeaterSwitchIn 0 "Off" 1 "Low" 2 "Mid" 3 "High" 4 "Auto" ;
VAL_ 960 SeatVentilationSwitchIn_RH 0 "Off" 1 "Low" 2 "Mid" 3 "High" 4 "Auto" ;
VAL_ 960 SeatHeaterSwitchIn_RH 0 "Off" 1 "Low" 2 "Mid" 3 "High" 4 "Auto" ;
VAL_ 960 SeatVentilationSwitchIn_LH 0 "Off" 1 "Low" 2 "Mid" 3 "High" 4 "Auto" ;
VAL_ 960 SeatHeaterSwitchIn_LH 0 "Off" 1 "Low" 2 "Mid" 3 "High" 4 "Auto" ;
VAL_ 960 ipREARmode 0 "NotDefined" 1 "AUTO" 2 "REAR OFF" 3 "REAR ON" ;
VAL_ 960 ipECOmode 0 "NotDefined" 1 "AUTO" 2 "ECO OFF" 3 "ECO ON" ;
VAL_ 960 ipAImode 0 "NotDefined" 1 "AUTO" 2 "FRS" 3 "REC" 4 "REC025" 5 "REC050" 6 "REC075" ;
VAL_ 960 ipADmode 0 "NotDefined" 1 "Auto" 2 "Panel" 3 "B/L" 4 "Floor" 5 "D/F" 6 "DEF" ;
VAL_ 960 ipACmode 0 "NotDefined" 1 "AUTO" 2 "OFF" 3 "AC" 4 "AC-ECO" ;
VAL_ 960 ipBlwLvl 0 "NotDefined" 1 "AUTO" 2 "M0(OFF)" 3 "M1" 4 "M2" 5 "M3" 6 "M4" 7 "M5" 8 "M6" 9 "M7" ;
VAL_ 918 CS_R_SW 0 "Off" 1 "On" ;
VAL_ 918 BZ_M_SW 0 "Off" 1 "On" ;
VAL_ 894 MAV_WASH 0 "normal" 1 "wash" ;
VAL_ 894 R_CROP_0 0 "normal" ;
VAL_ 894 BGMMUTE 0 "normal" 1 "Mute" ;
VAL_ 894 MAVTYPE 0 "invalid" 1 "360VM" 2 "Reserved" 3 "Reserved" 4 "Side&Rear w/ECU" 5 "Rear w/ECU" 6 "Reserved" 7 "Reserved" 8 "Reserved" 9 "None" ;
VAL_ 894 ENBLMMSW 0 "Disabled" 1 "Enabled" ;
VAL_ 894 MAV_BP_L 0 "No request" 1 "BEEP Request" ;
VAL_ 894 MAV_BP_S 0 "No request" 1 "BEEP Request" ;
VAL_ 894 MAV_ERR 0 "No Error" 1 "Error" ;
VAL_ 894 RM_DISP 0 "No request" 1 "Display Request" ;
VAL_ 893 LCDRSTE 0 "state0" 1 "state1" 2 "state2" 3 "state3" 4 "state4" 5 "state5" 6 "state6" 7 "invalid" ;
VAL_ 893 LCDRINV 0 "valid" 1 "invalid" ;
VAL_ 893 EDAPHZ 0 "Ig-ON" 1 "EDSS_OFF" 2 "Normal driving" 3 "Driving Support" 4 "Driving Intervenition" 5 "Stop keeping and rescue support" 6 "Ig-OFF" 7 "Reserved" ;
VAL_ 893 EDAHZD 0 "No request" 1 "hazard lamp request" 2 "turn indicator request (left)" 3 "turn indicator request (right)" ;
VAL_ 893 EDAHRN 0 "No request" 1 "request" ;
VAL_ 893 EDRLCA 0 "Not equipped" 1 "Off" 2 "Stand-By" 3 "Active" 4 "Faulted" 5 "Reserved" 6 "Reserved" 7 "Reserved" ;
VAL_ 893 EDRAES 0 "Not equipped" 1 "OFF" 2 "On but not engaged" 3 "Engaged" 4 "Faulted" 5 "Reserved" 6 "Reserved" 7 "Reserved" ;
VAL_ 893 EDRLTA 0 "Not equipped" 1 "Off" 2 "Stand-By" 3 "Active" 4 "Faulted" 5 "Reserved" 6 "Reserved" 7 "Reserved" ;
VAL_ 893 EDRESA 0 "Not equipped" 1 "OFF" 2 "On but not engaged" 3 "Engaged" 4 "Faulted" 5 "Reserved" 6 "Reserved" 7 "Reserved" ;
VAL_ 893 EDRLDWS 0 "Not equipped" 1 "Off" 2 "Cannot activate" 3 "Faulted" 4 "Left warning ON" 5 "Reserved" 6 "Reserved" 7 "Reserved" 8 "Right warning ON" 9 "Reserved" 10 "Reserved" 11 "Reserved" 12 "Both warning ON" 13 "Reserved" 14 "Reserved" 15 "Reserved" ;
VAL_ 893 EDRLDA 0 "Not equipped" 1 "Off" 2 "On but not engaged" 3 "Engaged" 4 "Faulted" 5 "Reserved" 6 "Reserved" 7 "Reserved" ;
VAL_ 857 cmu_fail_state 0 "Undiagnosed" 1 "Normal detected" 2 "Failure detected" 3 "Invalid" ;
VAL_ 857 EDA_onsw_dispflag 0 "off" 1 "On" ;
VAL_ 857 HOFDIOPE 0 "OFF" 1 "OK" 2 "NG" 3 "BACK" ;
VAL_ 855 SRVC_AC 0 "Indeterminate" 1 "Undefined" 2 "Determined, agreed" 3 "Determined, disagreed" ;
VAL_ 855 SRVC_VC 0 "Indeterminate" 1 "Undefined" 2 "Determined, agreed" 3 "Determined, disagreed" ;
VAL_ 855 SRVC_PC 0 "Indeterminate" 1 "Undefined" 2 "Determined, agreed" 3 "Determined, disagreed" ;
VAL_ 855 Ota_SuppIgonReq 0 "Unknown(default)" 1 "Suppression off" 2 "Suppression active" 3 "Reserved" 4 "Reserved" 5 "Reserved" 6 "Reserved" 7 "Reserved" 8 "Reserved" 9 "Reserved" 10 "Reserved" 11 "Reserved" 12 "Reserved" 13 "Reserved" 14 "Reserved" 15 "Reserved" ;
VAL_ 855 SRVC_STT 0 "Undetermined" 1 "Undefined" 2 "Determined, agreed" 3 "Determined, disagreed" ;
VAL_ 848 RECRNOFF 0 "No recording events" 1 "G detection" 2 "Burglar alarm cooperation" 3 "Reserved" 4 "Reserved" 5 "Remote monitoring of my car" 6 "Reserved" 7 "Reserved" 8 "Reserved" 9 "Reserved" 10 "Parking continuous recording" 11 "Approach detection" 12 "Reserved" 13 "Reserved" 14 "Reserved" 15 "Event does not require recording" ;
VAL_ 848 WUREQ 0 "No request" 1 "VDR on request" ;
VAL_ 848 RECEND 0 "Normal state" 1 "Recording end state" ;
VAL_ 848 IMGI_POF 0 "Request PVM 360" 1 "Request PVM Rr" ;
VAL_ 847 LCFP 0 "No request" 1 "Turn Prohibit Request from LCA" 2 "Reserved" 3 "Reserved" ;
VAL_ 847 DM_BZR 0 "No output" 1 "Driving Support" 2 "Interv or Rescue or To shoulder" 3 "Reserved" 4 "Reserved" 5 "Reserved" 6 "Reserved" 7 "Reserved" 8 "Reserved" 9 "Reserved" 10 "Reserved" 11 "Reserved" 12 "Reserved" 13 "Reserved" 14 "Reserved" 15 "Reserved" ;
VAL_ 847 LCAINDI 0 "off" 1 "white lighting" 2 "green lighting" 3 "Umber lighting" 4 "Reserved" 5 "Reserved" 6 "Reserved" 7 "Reserved" ;
VAL_ 847 DM_DISPM 0 "No display" 1 "Driving Support" 2 "Driving Intervenition" 3 "Stop keeping and rescue support" 4 "Deceleration to road shoulder" 5 "Reserved" 6 "Reserved" 7 "Reserved" 8 "Reserved" 9 "Stop hold malfunction" 10 "Reserved" 11 "Reserved" 12 "Reserved" 13 "Reserved" 14 "Reserved" 15 "Reserved" ;
VAL_ 847 DM_HRNRQ 0 "No request" 1 "On request(Honk vehicle horn)" ;
VAL_ 847 DM_DRULK 0 "No request" 1 "On request(unlock)" ;
VAL_ 847 ACCSPMEX 0 "Not Exist" 1 "Exist" ;
VAL_ 847 ACCSPMD 0 "invalid" 1 "OFF" 2 "Low" 3 "High" ;
VAL_ 847 DM_TRNRQ 0 "No request" 1 "Hazard request" 2 "Reserved" 3 "Reserved" 4 "Left turn lamp is ON" 5 "Right turn lamp is ON" 6 "Reserved" 7 "Reserved" ;
VAL_ 847 LCSRWNGD 0 "Off" 1 "Lighting" 2 "Reserved" 3 "Reserved" ;
VAL_ 847 LCSARRRD 0 "OFF" 1 "LCA waiting (green)" 2 "standby (gray)" 3 "Reserved" 4 "Reserved" 5 "LCA move horizontally (green)" 6 "Reserved" 7 "standby (white)" ;
VAL_ 847 LCSARRLD 0 "OFF" 1 "LCA waiting (green)" 2 "standby (gray)" 3 "Reserved" 4 "Reserved" 5 "LCA move horizontally (green)" 6 "Reserved" 7 "standby (white)" ;
VAL_ 847 LCSLWNGD 0 "Off" 1 "Lighting" 2 "Reserved" 3 "Reserved" ;
VAL_ 847 LCASGIND 0 "No Indication" 1 "Indication 1" 2 "Indication 2" 3 "Indication 3" 4 "Indication 4" 5 "Indication 5" 6 "Indication 6" 7 "Indication 7" 8 "Indication 8" 9 "Indication 9" 10 "Indication 10" 11 "Indication 11" 12 "Indication 12" 13 "Indication 13" 14 "Indication 14" 15 "Indication 15" ;
VAL_ 847 LCAMSG 0 "none" 1 "system cancel" 2 "system malfunction" 3 "system unavailable" 4 "cannot start type 1" 5 "cannot start type 2" 6 "cannot start type 3" 7 "system stanby" 8 "hold steering wheel req display" 9 "automatic standby" 10 "Reserved" 11 "Reserved" 12 "Reserved" 13 "Reserved" 14 "Reserved" 15 "Reserved" ;
VAL_ 847 LCWNKONR 0 "No request" 1 "Right turn lamp is ON" ;
VAL_ 847 LCWNKONL 0 "No request" 1 "Left turn lamp is ON" ;
VAL_ 847 DISPREQA 0 "no flag" 1 "MID display diag flag" ;
VAL_ 847 DISPUP 0 "non renewal flag" 1 "MID display renewal flag" ;
VAL_ 847 LTCMODE 0 "LTC-Mode Off" 1 "LTC-Mode On" ;
VAL_ 847 LCSONSD 0 "non-display" 1 "On-Screen display" ;
VAL_ 847 LCSRQBZ 0 "No request" 1 "Request" ;
VAL_ 847 LCAVCBZ 0 "No request" 1 "Request" ;
VAL_ 847 LCANGBZ 0 "No request" 1 "Request" ;
VAL_ 846 OMI_R 0 "Right Side Off" 1 "Right Side Lighting" 2 "Right Flashing" 3 "underfined" ;
VAL_ 846 OMI_L 0 "Left Side Off" 1 "Left Side Lighting" 2 "Left Flashing" 3 "underfined" ;
VAL_ 837 PDAEXIST 0 "No indication" 1 "soft SW indication" ;
VAL_ 837 PDAONST 0 "OFF" 1 "ON" ;
VAL_ 837 SDGEXIST 0 "No indication" 1 "soft SW indication" ;
VAL_ 837 SDGONST 0 "OFF" 1 "ON" ;
VAL_ 837 SDGCONT 0 "No control" 1 "controlled" ;
VAL_ 837 USMEXIST 0 "No indication" 1 "soft SW indication" ;
VAL_ 837 USMONST 0 "OFF" 1 "ON" ;
VAL_ 837 USMTLTYP 0 "No target" 1 "Traffic light and stop sign" 2 "Traffic light" 3 "Stop sign" ;
VAL_ 837 USMTLDSW 0 "URSM for traffic light OFF" 1 "URSM for traffic light ON" ;
VAL_ 837 USMSW 0 "URSM OFF" 1 "URSM ON" 2 "URSM Fail" 3 "URSM Ready" ;
VAL_ 837 USMDSE 0 "URSM sensitivity level 1" 1 "URSM sensitivity level 2" 2 "URSM sensitivity level 3" 3 "URSM sensitivity level 4" 4 "URSM sensitivity level 5" 5 "Reserved" 6 "Reserved" 7 "Reserved" ;
VAL_ 837 USMDSPSW 0 "URSM SW disp is not requested" 1 "URSM SW disp is requested" ;
VAL_ 837 ISAAVABL 0 "OFF" 1 "ON" ;
VAL_ 837 TMNAVABL 0 "OFF" 1 "ON" ;
VAL_ 837 TSSPOP 0 "No Request" 1 "Request" 2 "Reserved" 3 "Reserved" ;
VAL_ 837 CCEX 0 "OFF" 1 "ON" ;
VAL_ 837 CCAVABL 0 "OFF" 1 "ON" ;
VAL_ 837 AHBEXIST 0 "without AHB system" 1 "with AHB" ;
VAL_ 837 IDAAVABL 0 "OFF" 1 "ON" ;
VAL_ 837 USMAVABL 0 "OFF" 1 "ON" ;
VAL_ 837 AHBAVABL 0 "OFF" 1 "ON" ;
VAL_ 837 ACCAVABL 0 "OFF" 1 "ON" ;
VAL_ 837 PCSAVABL 0 "OFF" 1 "ON" ;
VAL_ 837 TSSTUNA 0 "OFF" 1 "ON" ;
VAL_ 837 TSSMALF 0 "OFF" 1 "ON" ;
VAL_ 837 FRDTUCT 0 "OFF" 1 "ON" ;
VAL_ 837 FRDTEMP 0 "OFF" 1 "ON" ;
VAL_ 837 FRDDUST 0 "OFF" 1 "ON" ;
VAL_ 837 FCMTEMP 0 "OFF" 1 "ON" ;
VAL_ 837 FCMDUST 0 "OFF" 1 "ON" ;
VAL_ 832 RCM_EDRtype 0 "Old_type" 1 "Standard_type" ;
VAL_ 832 EDRTrigger 0 "Trigger off" 1 "Trigger on" 2 "Invalid" 3 "undefined" ;
VAL_ 832 FirstRowBucklePsngr_FD 0 "passenger belt not used" 1 "passenger belt used" 2 "fault(hole IC)/resrve(mech)" 3 "reserve" ;
VAL_ 832 OCS_Status 0 "Unknown" 1 "Vacancy" 2 "Occupied" 3 "Malfunction" ;
VAL_ 832 PAD_Ind_Req 0 "AirbagOn_illum_Off_illum" 1 "AirbagOn_illum_Off_Not_illum" 2 "AirbagOn_Not_illum_Off_illum" 3 "Invalid" 4 "AirbagOn_Not_illum_Off_Not_illum" 5 "Reserved" ;
VAL_ 807 USMBZ 0 "No buzzer request" 1 "Buzzer request1" 2 "Buzzer request2" 3 "Buzzer request3" 4 "Buzzer request4" 5 "Reserve" 6 "Reserve" 7 "Reserve" ;
VAL_ 807 USMOR 0 "Not driver override" 1 "Driver override" ;
VAL_ 807 USMDSPCR 0 "Not displaying curve" 1 "Displaying curve" ;
VAL_ 807 USMDSPTL 0 "Not displaying traffic light" 1 "Displaying traffic light type A " 2 "Displaying traffic light type A " 3 "Reserve" 4 "Reserve" 5 "Displaying traffic light type B " 6 "Displaying traffic light type B " 7 "Reserve" ;
VAL_ 807 USMDSPPV 0 "Not displaying preceding vehicle" 1 "Displaying preceding vehicle" 2 "Displaying approaching preceding" 3 "Reserve" ;
VAL_ 807 DWREQ 0 "Distance Warning no request" 1 "Distance Warning request" 2 "Pre Distance Warning request" ;
VAL_ 805 ApsShiftLvrLock_D_Req 0 "Not request" 1 "Locked" 2 "Unlocked" 3 "Reserved" ;
VAL_ 805 APPSYS2 0 "APP System is invalid" 1 "APP System is valid" ;
VAL_ 805 APPMD2 0 "Not control" 1 "Act control" 2 "Suspend control" 3 "Fin control" ;
VAL_ 797 DrvrID_12_State_OMS 0 "ID 12 not registered" 1 "ID 12 registered" ;
VAL_ 797 DrvrID_11_State_OMS 0 "ID 11 not registered" 1 "ID 11 registered" ;
VAL_ 797 DrvrID_10_State_OMS 0 "ID 10 not registered" 1 "ID 10 registered" ;
VAL_ 797 DrvrID_9_State_OMS 0 "ID 9 not registered" 1 "ID 9 registered" ;
VAL_ 797 DrvrID_8_State_OMS 0 "ID 8 not registered" 1 "ID 8 registered" ;
VAL_ 797 DrvrID_7_State_OMS 0 "ID 7 not registered" 1 "ID 7 registered" ;
VAL_ 797 DrvrID_6_State_OMS 0 "ID 6 not registered" 1 "ID 6 registered" ;
VAL_ 797 DrvrID_5_State_OMS 0 "ID 5 not registered" 1 "ID 5 registered" ;
VAL_ 797 DrvrID_4_State_OMS 0 "ID 4 not registered" 1 "ID 4 registered" ;
VAL_ 797 DrvrID_3_State_OMS 0 "ID 3 not registered" 1 "ID 3 registered" ;
VAL_ 797 DrvrID_2_State_OMS 0 "ID 2 not registered" 1 "ID 2 registered" ;
VAL_ 797 DrvrID_1_State_OMS 0 "ID 1 not registered" 1 "ID 1 registered" ;
VAL_ 797 DrvrID_Invalid_State_OMS 0 "Invalid ID State" 1 "Normal" ;
VAL_ 797 Deletion_Result_OMS 0 "Initial value" 1 "DrvrID1" 2 "DrvrID2" 3 "DrvrID3" 4 "DrvrID4" 5 "DrvrID5" 6 "DrvrID6" 7 "DrvrID7" 8 "DrvrID8" 9 "DrvrID9" 10 "DrvrID10" 11 "DrvrID11" 12 "DrvrID12" 13 "ALL" 14 "Error" 15 "Invalid" ;
VAL_ 797 Deletion_State_OMS 0 "No action/Initial value" 1 "Start /On going" 2 "Stop" 3 "Finish" 4 "Time out" 5 "Reserved" 6 "Reserved" 7 "Error" ;
VAL_ 797 Registration_Result_OMS 0 "Initial value" 1 "DrvrID1" 2 "DrvrID2" 3 "DrvrID3" 4 "DrvrID4" 5 "DrvrID5" 6 "DrvrID6" 7 "DrvrID7" 8 "DrvrID8" 9 "DrvrID9" 10 "DrvrID10" 11 "DrvrID11" 12 "DrvrID12" 13 "Reserved" 14 "Error" 15 "Invalid" ;
VAL_ 797 Registration_State_OMS 0 "No action/Initial value" 1 "Start /On going" 2 "Stop" 3 "Finish" 4 "Time out" 5 "Reserved" 6 "Reserved" 7 "Error" ;
VAL_ 797 Recovery_Request_OMS 0 "Ini" 1 "Hd bck" 2 "Hd frw" 3 "Hd rht" 4 "Hd lft" 5 "Hd dwn" 6 "Hd up" 7 "Fc dwn" 8 "Fc up" 9 "Fc rht" 10 "Fc lft" 11 "Msk off" 12 "Sngls off" 13 "Check" 14 "Dcrs fc reli" 15 "Dcrs fc drct reli" 30 "Errr" 31 "Inv" ;
VAL_ 797 Identification_Result_OMS 0 "Initial value" 1 "DrvrID1" 2 "DrvrID2" 3 "DrvrID3" 4 "DrvrID4" 5 "DrvrID5" 6 "DrvrID6" 7 "DrvrID7" 8 "DrvrID8" 9 "DrvrID9" 10 "DrvrID10" 11 "DrvrID11" 12 "DrvrID12" 13 "Guest" 14 "Error" 15 "Invalid" ;
VAL_ 797 Identification_State_OMS 0 "No action/Initial value" 1 "Start /On going" 2 "Stop" 3 "Finish" 4 "Time out" 5 "Reserved" 6 "Reserved" 7 "Error" ;
VAL_ 797 OMS_Mode_OMS 0 "Initial value" 1 "Identification mode" 2 "Sensing mode" 3 "Reserved" ;
VAL_ 796 AimHeadZ 0 "Not calibrated" 1 "claibrated" ;
VAL_ 796 DrvrHeadReli 0 "Not detected" 1 "False detection:over 50%" 2 "False detection:10 - 50%" 3 "False detection:5 - 10%" 4 "False detection:1 - 5%" 5 "False detection:under 1%" 6 "Reserved" 7 "Invalid value" ;
VAL_ 795 DrvrEyeRReli 0 "Not detected" 1 "False detection:over 50%" 2 "False detection:10 - 50%" 3 "False detection:5 - 10%" 4 "False detection:1 - 5%" 5 "False detection:under 1%" 6 "Reserved" 7 "Invalid value" ;
VAL_ 795 DrvrEyeLReli 0 "Not detected" 1 "False detection:over 50%" 2 "False detection:10 - 50%" 3 "False detection:5 - 10%" 4 "False detection:1 - 5%" 5 "False detection:under 1%" 6 "Reserved" 7 "Invalid value" ;
VAL_ 795 DrvrFaceReli 0 "Not detected" 1 "False detection:over 50%" 2 "False detection:10 - 50%" 3 "False detection:5 - 10%" 4 "False detection:1 - 5%" 5 "False detection:under 1%" 6 "Reserved" 7 "Invalid value" ;
VAL_ 792 AH_IND_S 0 "OFF" 1 "ON(Lo)" 2 "ON(shade Hi)" 3 "ON(Hi)" 4 "ON(AHBSW ON)" 5 "ON(AHB)" 6 "Abnormal" 7 "Bulb check" ;
VAL_ 792 A_BW_PRE 0 "Bad Weather sys is not exist" 1 "Bad Weather sys is exist" ;
VAL_ 792 A_BW_IND 0 "Not in multi weather light" 1 "In multi weather light" 2 "Reserved" 3 "Reserved" ;
VAL_ 792 A_HLLI 0 "Normal/Undetermined" 1 "leveling malfunction" 2 "leveling Uninitialized" 3 "Reserved" ;
VAL_ 792 A_LMP_ST 0 "Normal/Undetermined" 1 "Data writing is not finished" 2 "Headlight System Malfunction" 3 "Reserved" ;
VAL_ 792 OTHHLCOM 0 "Initial/Unknown" 1 "Head lamp Off" 2 "Head Lamp On" 3 "Undefined yet" ;
VAL_ 792 OTHTLAH 0 "Initial/Unknown" 1 "Tail Off" 2 "Tail On" 3 "Undefined yet" ;
VAL_ 792 SRP_IND 0 "No Indicator Request" 1 "Indicator Request" ;
VAL_ 792 SRP_PRE 0 "Road Projection is not exist" 1 "Road Projection is exist" ;
VAL_ 780 IMGOP_P 0 "w/o PVM Image for DVR" 1 "w/ PVM Image for DVR" ;
VAL_ 780 DRADUABN 0 "All normal" 1 "Fr camara error" 2 "PVM 1-3 camera error" 3 "PVM 1-3 camera + Fr camera error" 6 "PVM all camera error" 7 "PVM all camera + Fr camera error" ;
VAL_ 780 DRADUTMP 0 "No ADAS temporary abnormalities" 1 "ADAS temporary abnormalities" ;
VAL_ 608 ASE_Sport_Mode_Active 0 "NotActivated" 1 "Activated" ;
VAL_ 608 TRQ_XFER_CMD_BY_BRK_ALOWD 0 "No" 1 "Yes" ;
VAL_ 608 IDM_SD_Evl_D_Num_260 0 "NoEvaluation" 1 "AccelFine" 2 "BrakeFine" 3 "SteerLeftFine" 4 "SteerRightFine" 5 "AccelG_Constant" 6 "BrakeG_Constant" 7 "SteerLeftG_Constant" 8 "SteerRightG_Contant" 9 "AccelFastStep" 10 "AccelFastRelease" 11 "BrakeFastStep" 12 "BrakeFastRelease" 13 "SteerLeftFastOperate" 14 "SteerRightFastOperate" 15 "SteerLeftFastReturn" 16 "SteerRightFastReturn" 17 "AccelFluctuation" 18 "BrakeFluctuation" 19 "SteerFluctuation" 20 "Clutch_NotFine" ;
VAL_ 608 TELLTALE_4X4_AUTO 0 "OFF" 1 "Flash 1 times" 2 "Flash 2 times" 3 "Flash 3 times" 4 "Flash 4 times" 5 "Flash 5times" 6 "Flash 6times" 7 "Flash 7times" 8 "Flash 8times" 9 "Flash 9times" 10 "Flash 10times" 11 "Flash 11times" 12 "Flash 12times" 13 "Flash 13times" 14 "Flash 14times" 15 "Flash ON" ;
VAL_ 608 LOW4 0 "OFF" 1 "ON" ;
VAL_ 608 AI4WD 0 "OFF" 1 "ON" ;
VAL_ 608 MODE_4x4 0 "Automatic_4WD" 1 "Neutral" 2 "2WD" 3 "4wD_LOW" 4 "4WD_HIGH" 15 "Invalid" ;
VAL_ 599 HMI_Warning_LCA1_Rq 0 "no indication" 1 "LCA Failure" ;
VAL_ 599 HMI_Warning_DM3_Rq 0 "no indication" 1 "DM EV Wearing Sunglass" ;
VAL_ 599 HMI_Warning_DM2_Rq 0 "no indication" 1 "DM EV Wearing Accesary" ;
VAL_ 599 HMI_Warning_DM1_Rq 0 "no indication" 1 "DM EV Wearing Mask" ;
VAL_ 599 HMI_Warning_VCUNIT1_Rq 0 "no indication" 1 "VCU Failure" ;
VAL_ 599 HMI_Warning_OMC10_Rq 0 "no indication" 1 "OMC Degradation" ;
VAL_ 599 HMI_Warning_OMC8_Rq 0 "no indication" 1 "OMC Failure" ;
VAL_ 599 HMI_Warning_OMC7_Rq 0 "no indication" 1 "OMC LED Failure" ;
VAL_ 599 HMI_Warning_OMC6_Rq 0 "no indication" 1 "OMC CAM Failure" ;
VAL_ 599 HMI_Warning_OMC5_Rq 0 "no indication" 1 "OMC System Failure" ;
VAL_ 599 HMI_Warning_OMC4_Rq 0 "no indication" 1 "OMC High Temperature" ;
VAL_ 599 HMI_Warning_OMC3_Rq 0 "no indication" 1 "OMC Backlit" ;
VAL_ 599 HMI_Warning_OMC2_Rq 0 "no indication" 1 "OMC Degradation" ;
VAL_ 599 HMI_Warning_OMC1_Rq 0 "no indication" 1 "OMC Blockage" ;
VAL_ 599 HMI_Warning_VMC8_Rq 0 "no indication" 1 "VMC Failure" ;
VAL_ 599 HMI_Warning_VMC7_Rq 0 "no indication" 1 "VMC Camera Failure" ;
VAL_ 599 HMI_Warning_VMC6_Rq 0 "no indication" 1 "VMC Not Aligned" ;
VAL_ 599 HMI_Warning_VMC5_Rq 0 "no indication" 1 "VMC Lowsun" ;
VAL_ 599 HMI_Warning_VMC4_Rq 0 "no indication" 1 "VMC High Temperature" ;
VAL_ 599 HMI_Warning_VMC3_Rq 0 "no indication" 1 "VMC Backlit" ;
VAL_ 599 HMI_Warning_VMC2_Rq 0 "no indication" 1 "VMC Degradation" ;
VAL_ 599 HMI_Warning_VMC1_Rq 0 "no indication" 1 "VMC Blockage" ;
VAL_ 599 HMI_Warning_Sonar4_Rq 0 "no indication" 1 "Sonar Failure" ;
VAL_ 599 HMI_Warning_Sonar3_Rq 0 "no indication" 1 "Sonar Sensor Failure" ;
VAL_ 599 HMI_Warning_Sonar2_Rq 0 "no indication" 1 "Sonar High Temperature" ;
VAL_ 599 HMI_Warning_Sonar1_Rq 0 "no indication" 1 "Sonar Blockage" ;
VAL_ 599 HMI_Warning_RSRDR6_Rq 0 "no indication" 1 "RSRDR Failure" ;
VAL_ 599 HMI_Warning_RSRDR5_Rq 0 "no indication" 1 "RSRDR Not Aligned" ;
VAL_ 599 HMI_Warning_RSRDR4_Rq 0 "no indication" 1 "RSRDR High Temperature" ;
VAL_ 599 HMI_Warning_RSRDR3_Rq 0 "no indication" 1 "RSRDR Interference" ;
VAL_ 599 HMI_Warning_RSRDR2_Rq 0 "no indication" 1 "RSRDR Vibration" ;
VAL_ 599 HMI_Warning_RSRDR1_Rq 0 "no indication" 1 "RSRDR Blockage" ;
VAL_ 599 HMI_Warning_FSRDR6_Rq 0 "no indication" 1 "FSRDR Failure" ;
VAL_ 599 HMI_Warning_FSRDR5_Rq 0 "no indication" 1 "FSRDR Not Aligned" ;
VAL_ 599 HMI_Warning_FSRDR4_Rq 0 "no indication" 1 "FSRDR High Temperature" ;
VAL_ 599 HMI_Warning_FSRDR3_Rq 0 "no indication" 1 "FSRDR Interference" ;
VAL_ 599 HMI_Warning_FSRDR2_Rq 0 "no indication" 1 "FSRDR Vibration" ;
VAL_ 599 HMI_Warning_FSRDR1_Rq 0 "no indication" 1 "FSRDR Blockage" ;
VAL_ 599 HMI_Warning_FRDR6_Rq 0 "no indication" 1 "FRDR Failure" ;
VAL_ 599 HMI_Warning_FRDR5_Rq 0 "no indication" 1 "FRDR Not Aligned" ;
VAL_ 599 HMI_Warning_FRDR4_Rq 0 "no indication" 1 "FRDR High Temperature" ;
VAL_ 599 HMI_Warning_FRDR3_Rq 0 "no indication" 1 "FRDR Interference" ;
VAL_ 599 HMI_Warning_FRDR2_Rq 0 "no indication" 1 "FRDR Vibration" ;
VAL_ 599 HMI_Warning_FRDR1_Rq 0 "no indication" 1 "FRDR Blockage" ;
VAL_ 599 HMI_Warning_FSC6_Rq 0 "no indication" 1 "FSC Failure" ;
VAL_ 599 HMI_Warning_FSC5_Rq 0 "no indication" 1 "FSC Not Aligned" ;
VAL_ 599 HMI_Warning_FSC4_Rq 0 "no indication" 1 "FSC High Temperature" ;
VAL_ 599 HMI_Warning_FSC3_Rq 0 "no indication" 1 "FSC Backlit" ;
VAL_ 599 HMI_Warning_FSC2_Rq 0 "no indication" 1 "FSC Degradation" ;
VAL_ 599 HMI_Warning_FSC1_Rq 0 "no indication" 1 "FSC Blockage" ;
VAL_ 599 HMI_Warning_HBC1_Rq 0 "no indication" 1 "HBC Active Lo" 2 "HBC TMP Failure" 3 "HBC Failure" ;
VAL_ 599 HMI_Warning_ALH1_Rq 0 "no indication" 1 "ALH Active Lo" 2 "ALH TMP Failure" 3 "ALH Failure" ;
VAL_ 599 HMI_Warning_PASR1_Rq 0 "no indication" 1 "PAS Failure Trailer" ;
VAL_ 599 HMI_Warning_TSR1_Rq 0 "no indication" 1 "TSR Fallback1" 2 "TSR Fallback2" 3 "Reserved" ;
VAL_ 599 HMI_Warning_LKA1_Rq 0 "no indication" 1 "LKA TMP Failure" 2 "LKA Failure" 3 "Reserved" ;
VAL_ 599 HMI_Warning_ISA1_Rq 0 "no indication" 1 "ISA Failure" ;
VAL_ 599 HMI_Warning_ASC1_Rq 0 "no indication" 1 "ASC Failure" ;
VAL_ 599 HMI_Warning_ACC1_Rq 0 "no indication" 1 "ACC fallback" 2 "ACC TMP Failure" 3 "ACC Failure" ;
VAL_ 598 HMI_Status_VCUNIT1_Rq 0 "no indication" 1 "VCU Towing" 2 "VCU Towing Rear" 3 "Reserved" ;
VAL_ 598 HMI_Status_OMC1_Rq 0 "no indication" 1 "OMC Test" ;
VAL_ 598 HMI_Status_VMC1_Rq 0 "no indication" 1 "VMC Test" ;
VAL_ 598 HMI_Status_Sonar1_Rq 0 "no indication" 1 "Sonar Test" ;
VAL_ 598 HMI_Status_RSRDR3_Rq 0 "no indication" 1 "RSRDR Calibration Abnormal" ;
VAL_ 598 HMI_Status_RSRDR2_Rq 0 "no indication" 1 "RSRDR Calibration Normal" ;
VAL_ 598 HMI_Status_RSRDR1_Rq 0 "no indication" 1 "RSRDR Test" ;
VAL_ 598 HMI_Status_FSRDR3_Rq 0 "no indication" 1 "FSRDR Calibration Abnormal" ;
VAL_ 598 HMI_Status_FSRDR2_Rq 0 "no indication" 1 "FSRDR Calibration Normal" ;
VAL_ 598 HMI_Status_FSRDR1_Rq 0 "no indication" 1 "FSRDR Test" ;
VAL_ 598 HMI_Status_FRDR3_Rq 0 "no indication" 1 "FRDR Calibration Abnormal" ;
VAL_ 598 HMI_Status_FRDR2_Rq 0 "no indication" 1 "FRDR Calibration Normal" ;
VAL_ 598 HMI_Status_FRDR1_Rq 0 "no indication" 1 "FRDR Test" ;
VAL_ 598 HMI_Status_FSC3_Rq 0 "no indication" 1 "FSC Calibration Abnormal" ;
VAL_ 598 HMI_Status_FSC2_Rq 0 "no indication" 1 "FSC Calibration Normal" ;
VAL_ 598 HMI_Status_FSC1_Rq 0 "no indication" 1 "FSC Test Mode" ;
VAL_ 598 HMI_Status_TMN2_Rq 0 "no indication" 1 "TMN On" ;
VAL_ 598 HMI_Status_TMN1_Rq 0 "no indication" 1 "TMN Front Vehicle Warning" ;
VAL_ 598 HMI_Status_LCA12_Rq 0 "no indication" 1 "LCA EV Surround Check" ;
VAL_ 598 HMI_Status_LCA11_Rq 0 "no indication" 1 "LC Warn Approach Left" 2 "LC Warn Approach Right" 3 "Reserved" ;
VAL_ 598 HMI_Status_LCA10_Rq 0 "no indication" 1 "LCA EV Req Hold" ;
VAL_ 598 HMI_Status_LCA9_Rq 0 "no indication" 1 "LCA EV Reject Vel Over" ;
VAL_ 598 HMI_Status_LCA8_Rq 0 "no indication" 1 "LCA EV Reject Surround" ;
VAL_ 598 HMI_Status_LCA7_Rq 0 "no indication" 1 "LCA EV Reject" ;
VAL_ 598 HMI_Status_LCA6_Rq 0 "no indication" 1 "LCA EV Cancel" ;
VAL_ 598 HMI_Status_LCA5_Rq 0 "no indication" 1 "LCA EV Accepted" ;
VAL_ 598 HMI_Status_LCA4_Rq 0 "no indication" 1 "LC EV Auto Standby" ;
VAL_ 598 HMI_Status_LCA3_Rq 0 "no indication" 1 "LC EV Cancel LKA OFF" ;
VAL_ 598 HMI_Status_LCA2_Rq 0 "no indication" 1 "LC EV Cancel LKA ON" ;
VAL_ 598 HMI_Status_LCA1_Rq 0 "no indication" 1 "LCA Standby" 2 "LCA Standby RH" 3 "LCA Standby LH" 4 "LCA Available" 5 "LCA Unavailable RH" 6 "LCA Unavailable LH" 7 "LCA Unavailable" 8 "LCA Active RH" 9 "LCA Active LH" 10 "LCA Wait L" 11 "LCA Move L" 12 "LCA Cross L" 13 "LCA Close L" 14 "LCA Wait R" 15 "LCA Move R" 16 "LCA Cross R" 17 "LCA Close R" 18 "Reserved" 31 "Reserved" ;
VAL_ 598 HMI_Status_HoF11_Rq 0 "no indication" 1 "HoF Approval REC" ;
VAL_ 598 HMI_Status_HoF10_Rq 0 "no indication" 1 "HoF REC Wait" 2 "HoF REC Recording" 3 "Reserved" ;
VAL_ 598 HMI_Status_HoF9_Rq 0 "no indication" 1 "HoF EV Not Start02" ;
VAL_ 598 HMI_Status_HoF8_Rq 0 "no indication" 1 "HoF EV Not Start01" ;
VAL_ 598 HMI_Status_HoF7_Rq 0 "no indication" 1 "HoF EV End03" ;
VAL_ 598 HMI_Status_HoF6_Rq 0 "no indication" 1 "HoF EV End02" ;
VAL_ 598 HMI_Status_HoF5_Rq 0 "no indication" 1 "HoF EV End01" ;
VAL_ 598 HMI_Status_HoF4_Rq 0 "no indication" 1 "HoF EV Resume01" ;
VAL_ 598 HMI_Status_HoF3_Rq 0 "no indication" 1 "HoF EV Start01" ;
VAL_ 598 HMI_Status_HoF2_Rq 0 "no indication" 1 "Reserved" 2 "HoF01" 3 "HoF02" 4 "HoF03" 5 "HoF04" 6 "HoF05" 7 "HoF06" 8 "HoF07" 9 "HoF08" 10 "HoF09" 11 "HoF10" 12 "HoF12" 13 "HoF13" 14 "HoF14" 15 "HoF15" 16 "Reserved" 31 "Reserved" ;
VAL_ 598 HMI_Status_HoF1_Rq 0 "no indication" 1 "HoF Active" ;
VAL_ 598 HMI_Status_AESESA1_Rq 0 "no indication" 1 "AES OFF" 2 "AES Warning" 3 "AES Control" 4 "Reserved" 5 "Reserved" 6 "Reserved" 7 "Reserved" ;
VAL_ 598 HMI_Status_PDA6_Rq 0 "no indication" 1 "PDA Vehicle Distance" ;
VAL_ 598 HMI_Status_PDA5_Rq 0 "no indication" 1 "PDA End Notification" ;
VAL_ 598 HMI_Status_PDA2_Rq 0 "no indication" 1 "PDA Disp Curve" 2 "PDA Disp Traffic Light" 3 "PDA Disp Forward Vehicle" ;
VAL_ 598 HMI_Status_PDA1_Rq 0 "no indication" 1 "PDA Inactive" 2 "PDA Active" 3 "PDA Override" 4 "Reserved" 5 "Reserved" 6 "Reserved" 7 "Reserved" ;
VAL_ 598 HMI_Status_REDKEY2_Rq 0 "no indication" 1 "REDKEY EV ON" ;
VAL_ 598 HMI_Status_REDKEY1_Rq 0 "no indication" 1 "REDKEY ON" ;
VAL_ 598 HMI_Status_EDA3_Rq 0 "no indication" 1 "CTS RMF EV Cancel" ;
VAL_ 598 HMI_Status_EDA2_Rq 0 "no indication" 1 "EDA EV Cancel" ;
VAL_ 598 HMI_Status_EDA1_Rq 0 "no indication" 1 "EDA Control3" 2 "EDA Control4" 3 "EDA Control10 Left" 4 "EDA Control10 Right" 5 "EDA Control11 Left" 6 "EDA Control11 Right" 7 "EDA Control14" 8 "CTS RMF Control3" 9 "CTS RMF Control4" 10 "CTS RMF Control10 Left" 11 "CTS RMF Control10 Right" 12 "CTS RMF Control11 Left" 13 "CTS RMF Control11 Right" 14 "CTS RMF Control14" 15 "Reserved" ;
VAL_ 598 HMI_Status_APSRPC1_Rq 0 "no indication" 1 "APS Inactive" 2 "APS Active" 3 "APS Pause" 4 "APS End" 5 "RPS Active" 6 "Reserved" 7 "Reserved" ;
VAL_ 598 HMI_Status_DM18_Rq 0 "no indication" 1 "DM EV Abnormal Posture" ;
VAL_ 598 HMI_Status_DM14_Rq 0 "no indication" 1 "DM EV Abnormal Posture" ;
VAL_ 598 HMI_Status_DM13_Rq 0 "no indication" 1 "DM EV Yawing" ;
VAL_ 598 HMI_Status_DM12_Rq 0 "no indication" 1 "DM EV Talking" ;
VAL_ 598 HMI_Status_DM11_Rq 0 "no indication" 1 "DM EV Smoking" ;
VAL_ 598 HMI_Status_DM10_Rq 0 "no indication" 1 "DM EV Sleep" ;
VAL_ 598 HMI_Status_DM9_Rq 0 "no indication" 1 "DM EV Engage Awake" ;
VAL_ 598 HMI_Status_DM8_Rq 0 "no indication" 1 "DM EV Visual Actuation RH" 2 "DM EV Visual Actuation LH" 3 "DM EV Visual Actuation LR" ;
VAL_ 598 HMI_Status_DM7_Rq 0 "no indication" 1 "DM EV Coginitive Distraction" ;
VAL_ 598 HMI_Status_DM6_Rq 0 "no indication" 1 "DM EV Warning Drowsy" ;
VAL_ 598 HMI_Status_DM5_Rq 0 "no indication" 1 "DM EV Attention Drowsy" ;
VAL_ 598 HMI_Status_DM4_Rq 0 "no indication" 1 "DM EV Sleep" ;
VAL_ 598 HMI_Status_DM3_Rq 0 "no indication" 1 "DM EV Warning" ;
VAL_ 598 HMI_Status_DM2_Rq 0 "no indication" 1 "DM EV Attention" ;
VAL_ 598 HMI_Status_DM1_Rq 0 "no indication" 1 "DM OFF" 2 "DM Inactive" 3 "DM Active" 4 "OMC OFF (CH)" 5 "DM Active(ANS Cancel)" 6 "Reserved" 7 "Reserved" ;
VAL_ 598 HMI_Status_PASFR8_Rq 0 "no indication" 1 "Reserved" 2 "PAS RRC Very Short" 3 "PAS RRC Short" 4 "PAS RRC Middle" 5 "PAS RRC Long" 6 "PAS RRC Very Long" 7 "Reserved" ;
VAL_ 598 HMI_Status_PASFR7_Rq 0 "no indication" 1 "Reserved" 2 "PAS RLC Very Short" 3 "PAS RLC Short" 4 "PAS RLC Middle" 5 "PAS RLC Long" 6 "PAS RLC Very Long" 7 "Reserved" ;
VAL_ 598 HMI_Status_PASFR6_Rq 0 "no indication" 1 "Reserved" 2 "PAS RR Very Short" 3 "PAS RR Short" 4 "PAS RR Middle" 5 "PAS RR Long" 6 "Reserved" 7 "Reserved" ;
VAL_ 598 HMI_Status_PASFR5_Rq 0 "no indication" 1 "Reserved" 2 "PAS RL Very Short" 3 "PAS RL Short" 4 "PAS RL Middle" 5 "PAS RL Long" 6 "Reserved" 7 "Reserved" ;
VAL_ 598 HMI_Status_PASFR4_Rq 0 "no indication" 1 "Reserved" 2 "PAS FRC Very Short" 3 "PAS FRC Short" 4 "PAS FRC Middle" 5 "PAS FRC Long" 6 "PAS FRC Very Long" 7 "Reserved" ;
VAL_ 598 HMI_Status_PASFR3_Rq 0 "no indication" 1 "Reserved" 2 "PAS FLC Very Short" 3 "PAS FLC Short" 4 "PAS FLC Middle" 5 "PAS FLC Long" 6 "PAS FLC Very Long" 7 "Reserved" ;
VAL_ 598 HMI_Status_PASFR2_Rq 0 "no indication" 1 "Reserved" 2 "PAS FR Very Short" 3 "PAS FR Short" 4 "PAS FR Middle" 5 "PAS FR Long" 6 "Reserved" 7 "Reserved" ;
VAL_ 598 HMI_Status_PASFR1_Rq 0 "no indication" 1 "Reserved" 2 "PAS FL Very Short" 3 "PAS FL Short" 4 "PAS FL Middle" 5 "PAS FL Long" 6 "Reserved" 7 "Reserved" ;
VAL_ 598 HMI_Status_PASR4_Rq 0 "no indication" 1 "Reserved" 2 "PAS RRC Very Short" 3 "PAS RRC Short" 4 "PAS RRC Middle" 5 "PAS RRC Long" 6 "PAS RRC Very Long" 7 "Reserved" ;
VAL_ 598 HMI_Status_PASR3_Rq 0 "no indication" 1 "Reserved" 2 "PAS RLC Very Short" 3 "PAS RLC Short" 4 "PAS RLC Middle" 5 "PAS RLC Long" 6 "PAS RLC Very Long" 7 "Reserved" ;
VAL_ 598 HMI_Status_PASR2_Rq 0 "no indication" 1 "Reserved" 2 "PAS RR Very Short" 3 "PAS RR Short" 4 "PAS RR Middle" 5 "PAS RR Long" 6 "Reserved" 7 "Reserved" ;
VAL_ 598 HMI_Status_PASR1_Rq 0 "no indication" 1 "Reserved" 2 "PAS RL Very Short" 3 "PAS RL Short" 4 "PAS RL Middle" 5 "PAS RL Long" 6 "Reserved" 7 "Reserved" ;
VAL_ 598 HMI_Status_PAS1_Rq 0 "no indication" 1 "PAS OFF" ;
